VERSION ""

NS_ :

BS_:

BU_: HzpStatus PathPoint LtRtEdg HzpSlot FarPathPoint PathPointRear IPMFreeSpace LtRtSlot WheelObj HMI E115DCU
VAL_TABLE_ HZP_PathDltButton 2 "DeleteAllPath" 1 "DeleteOnePath" 0 "NotAct" ;
VAL_TABLE_ HZP_VSLAM_Sts 7 "Relocation" 6 "Locating Fail" 5 "Initial Locating Fail" 4 "Mapping OverSize" 3 "MappingFail" 2 "Localization" 1 "Mapping" 0 "UnEnable" ;
VAL_TABLE_ APA_Search_STS 7 "Finish" 6 "3rd Curb OK" 5 "Fail " 4 "Fall detect" 3 "Rise and Fall OK" 2 "Rise Conf" 1 "Rish detect" 0 "Reserved" ;
VAL_TABLE_ APA_STS 7 "RTA,Wait to release brake" 6 "APA_Fail" 5 "APA_Finish" 4 "APA HangOn" 3 "APA processing" 2 "Standby" 1 "OFF" 0 "Reserved" ;

BO_ 3221225472 VECTOR__INDEPENDENT_SIG_MSG: 0 Vector__XXX
 SG_ ESC_HBB_Status : 0|2@0+ (1,0) [0|3] "" Vector__XXX
 SG_ Checksum_GW_TCU1 : 0|8@0+ (1,0) [0|255] "" Vector__XXX
 SG_ Rollingcount_GW_TCU1 : 0|4@0+ (1,0) [0|15] "" Vector__XXX
 SG_ GpsNumSats2 : 0|8@0+ (1,0) [0|255] "" Vector__XXX
 SG_ GpsNumSats : 0|8@0+ (1,0) [0|255] "" Vector__XXX
 SG_ GpsAge : 0|16@0+ (0.01,0) [0|655.35] "" Vector__XXX

BO_ 1942 HZP_PathPointRear1: 8 PathPointRear
 SG_ PthPtRr1_Slope : 25|2@0+ (1,0) [0|0] ""  E115DCU
 SG_ PathPointStrAng : 54|11@0- (0.5,0) [-500|500] ""  E115DCU
 SG_ PthPtRollCnt : 59|4@0+ (1,0) [0|15] ""  E115DCU
 SG_ PathPointY : 23|14@0- (0.01,0) [0|0] ""  E115DCU
 SG_ PathPointX : 7|14@0- (0.01,0) [0|0] ""  E115DCU
 SG_ PathPointAng : 39|17@0- (0.003,0) [0|0] ""  E115DCU

BO_ 1943 HZP_PathPointRear2: 8 PathPointRear
 SG_ PthPtRr2_Slope : 25|2@0+ (1,0) [0|0] ""  E115DCU
 SG_ PathPointStrAng : 54|11@0- (0.5,0) [-500|500] ""  E115DCU
 SG_ PthPtRollCnt : 59|4@0+ (1,0) [0|15] ""  E115DCU
 SG_ PathPointY : 23|14@0- (0.01,0) [0|0] ""  E115DCU
 SG_ PathPointX : 7|14@0- (0.01,0) [0|0] ""  E115DCU
 SG_ PathPointAng : 39|17@0- (0.003,0) [0|0] ""  E115DCU

BO_ 1944 HZP_PathPointRear3: 8 PathPointRear
 SG_ PthPtRr3_Slope : 25|2@0+ (1,0) [0|0] ""  E115DCU
 SG_ PathPointStrAng : 54|11@0- (0.5,0) [-500|500] ""  E115DCU
 SG_ PthPtRollCnt : 59|4@0+ (1,0) [0|15] ""  E115DCU
 SG_ PathPointY : 23|14@0- (0.01,0) [0|0] ""  E115DCU
 SG_ PathPointX : 7|14@0- (0.01,0) [0|0] ""  E115DCU
 SG_ PathPointAng : 39|17@0- (0.003,0) [0|0] ""  E115DCU

BO_ 1945 HZP_PathPointRear4: 8 PathPointRear
 SG_ PthPtRr4_Slope : 25|2@0+ (1,0) [0|0] ""  E115DCU
 SG_ PathPointStrAng : 54|11@0- (0.5,0) [-500|500] ""  E115DCU
 SG_ PthPtRollCnt : 59|4@0+ (1,0) [0|15] ""  E115DCU
 SG_ PathPointY : 23|14@0- (0.01,0) [0|0] ""  E115DCU
 SG_ PathPointX : 7|14@0- (0.01,0) [0|0] ""  E115DCU
 SG_ PathPointAng : 39|17@0- (0.003,0) [0|0] ""  E115DCU

BO_ 1946 HZP_PathPointRear5: 8 PathPointRear
 SG_ PthPtRr5_Slope : 25|2@0+ (1,0) [0|0] ""  E115DCU
 SG_ PathPointStrAng : 54|11@0- (0.5,0) [-500|500] ""  E115DCU
 SG_ PthPtRollCnt : 59|4@0+ (1,0) [0|15] ""  E115DCU
 SG_ PathPointY : 23|14@0- (0.01,0) [0|0] ""  E115DCU
 SG_ PathPointX : 7|14@0- (0.01,0) [0|0] ""  E115DCU
 SG_ PathPointAng : 39|17@0- (0.003,0) [0|0] ""  E115DCU

BO_ 1947 HZP_PathPointRear6: 8 PathPointRear
 SG_ PthPtRr6_Slope : 25|2@0+ (1,0) [0|0] ""  E115DCU
 SG_ PathPointStrAng : 54|11@0- (0.5,0) [-500|500] ""  E115DCU
 SG_ PthPtRollCnt : 59|4@0+ (1,0) [0|15] ""  E115DCU
 SG_ PathPointY : 23|14@0- (0.01,0) [0|0] ""  E115DCU
 SG_ PathPointX : 7|14@0- (0.01,0) [0|0] ""  E115DCU
 SG_ PathPointAng : 39|17@0- (0.003,0) [0|0] ""  E115DCU

BO_ 1948 HZP_PathPointRear7: 8 PathPointRear
 SG_ PthPtRr7_Slope : 25|2@0+ (1,0) [0|0] ""  E115DCU
 SG_ PathPointStrAng : 54|11@0- (0.5,0) [-500|500] ""  E115DCU
 SG_ PthPtRollCnt : 59|4@0+ (1,0) [0|15] ""  E115DCU
 SG_ PathPointY : 23|14@0- (0.01,0) [0|0] ""  E115DCU
 SG_ PathPointX : 7|14@0- (0.01,0) [0|0] ""  E115DCU
 SG_ PathPointAng : 39|17@0- (0.003,0) [0|0] ""  E115DCU

BO_ 1949 HZP_PathPointRear8: 8 PathPointRear
 SG_ PthPtRr8_Slope : 25|2@0+ (1,0) [0|0] ""  E115DCU
 SG_ PathPointStrAng : 54|11@0- (0.5,0) [-500|500] ""  E115DCU
 SG_ PthPtRollCnt : 59|4@0+ (1,0) [0|15] ""  E115DCU
 SG_ PathPointY : 23|14@0- (0.01,0) [0|0] ""  E115DCU
 SG_ PathPointX : 7|14@0- (0.01,0) [0|0] ""  E115DCU
 SG_ PathPointAng : 39|17@0- (0.003,0) [0|0] ""  E115DCU

BO_ 1950 HZP_PathPointRear9: 8 PathPointRear
 SG_ PthPtRr9_Slope : 25|2@0+ (1,0) [0|0] ""  E115DCU
 SG_ PathPointStrAng : 54|11@0- (0.5,0) [-500|500] ""  E115DCU
 SG_ PthPtRollCnt : 59|4@0+ (1,0) [0|15] ""  E115DCU
 SG_ PathPointY : 23|14@0- (0.01,0) [0|0] ""  E115DCU
 SG_ PathPointX : 7|14@0- (0.01,0) [0|0] ""  E115DCU
 SG_ PathPointAng : 39|17@0- (0.003,0) [0|0] ""  E115DCU

BO_ 1951 HZP_PathPointRear10: 8 PathPointRear
 SG_ PthPtRr10_Slope : 25|2@0+ (1,0) [0|0] ""  E115DCU
 SG_ PathPointStrAng : 54|11@0- (0.5,0) [-500|500] ""  E115DCU
 SG_ PthPtRollCnt : 59|4@0+ (1,0) [0|15] ""  E115DCU
 SG_ PathPointY : 23|14@0- (0.01,0) [0|0] ""  E115DCU
 SG_ PathPointX : 7|14@0- (0.01,0) [0|0] ""  E115DCU
 SG_ PathPointAng : 39|17@0- (0.003,0) [0|0] ""  E115DCU

BO_ 1952 HZP_MapEdgSlot_Info: 8 LtRtSlot
 SG_ HZP_MapRtSlotNm : 21|6@0+ (1,0) [0|63] ""  E115DCU
 SG_ HZP_MapRtEdgNm : 14|7@0+ (1,0) [0|127] ""  E115DCU
 SG_ HZP_MapLtSlotNm : 29|6@0+ (1,0) [0|63] ""  E115DCU
 SG_ HZP_MapLtEdgNm : 6|7@0+ (1,0) [0|127] ""  E115DCU

BO_ 1745 HZP_MapLtSlotPt_1: 8 LtRtSlot
 SG_ LtSlotPt_RollCnt : 59|4@0+ (1,0) [0|15] ""  E115DCU
 SG_ LtSlot2_Pt01Y : 53|10@0- (0.1,0) [-51.2|51.1] "m"  E115DCU
 SG_ LtSlot2_Pt01X : 47|10@0- (0.1,0) [-51.2|51.1] "m"  E115DCU
 SG_ LtSlot1_Pt02Y : 25|10@0- (0.1,0) [-51.2|51.1] "m"  E115DCU
 SG_ LtSlot1_Pt02X : 19|10@0- (0.1,0) [-51.2|51.1] "m"  E115DCU
 SG_ LtSlot1_Pt01Y : 13|10@0- (0.1,0) [-51.2|51.1] "m"  E115DCU
 SG_ LtSlot1_Pt01X : 7|10@0- (0.1,0) [-51.2|51.1] "m"  E115DCU

BO_ 1746 HZP_MapLtSlotPt_2: 8 LtRtSlot
 SG_ LtSlotPt_RollCnt : 59|4@0+ (1,0) [0|15] ""  E115DCU
 SG_ LtSlot3_Pt02Y : 53|10@0- (0.1,0) [-51.2|51.1] "m"  E115DCU
 SG_ LtSlot3_Pt02X : 47|10@0- (0.1,0) [-51.2|51.1] "m"  E115DCU
 SG_ LtSlot3_Pt01Y : 25|10@0- (0.1,0) [-51.2|51.1] "m"  E115DCU
 SG_ LtSlot3_Pt01X : 19|10@0- (0.1,0) [-51.2|51.1] "m"  E115DCU
 SG_ LtSlot2_Pt02Y : 13|10@0- (0.1,0) [-51.2|51.1] "m"  E115DCU
 SG_ LtSlot2_Pt02X : 7|10@0- (0.1,0) [-51.2|51.1] "m"  E115DCU

BO_ 1747 HZP_MapLtSlotPt_3: 8 LtRtSlot
 SG_ LtSlotPt_RollCnt : 59|4@0+ (1,0) [0|15] ""  E115DCU
 SG_ LtSlot5_Pt01Y : 53|10@0- (0.1,0) [-51.2|51.1] "m"  E115DCU
 SG_ LtSlot5_Pt01X : 47|10@0- (0.1,0) [-51.2|51.1] "m"  E115DCU
 SG_ LtSlot4_Pt02Y : 25|10@0- (0.1,0) [-51.2|51.1] "m"  E115DCU
 SG_ LtSlot4_Pt02X : 19|10@0- (0.1,0) [-51.2|51.1] "m"  E115DCU
 SG_ LtSlot4_Pt01Y : 13|10@0- (0.1,0) [-51.2|51.1] "m"  E115DCU
 SG_ LtSlot4_Pt01X : 7|10@0- (0.1,0) [-51.2|51.1] "m"  E115DCU

BO_ 1748 HZP_MapLtSlotPt_4: 8 LtRtSlot
 SG_ LtSlotPt_RollCnt : 59|4@0+ (1,0) [0|15] ""  E115DCU
 SG_ LtSlot6_Pt02Y : 53|10@0- (0.1,0) [-51.2|51.1] "m"  E115DCU
 SG_ LtSlot6_Pt02X : 47|10@0- (0.1,0) [-51.2|51.1] "m"  E115DCU
 SG_ LtSlot6_Pt01Y : 25|10@0- (0.1,0) [-51.2|51.1] "m"  E115DCU
 SG_ LtSlot6_Pt01X : 19|10@0- (0.1,0) [-51.2|51.1] "m"  E115DCU
 SG_ LtSlot5_Pt02Y : 13|10@0- (0.1,0) [-51.2|51.1] "m"  E115DCU
 SG_ LtSlot5_Pt02X : 7|10@0- (0.1,0) [-51.2|51.1] "m"  E115DCU

BO_ 1749 HZP_MapLtSlotPt_5: 8 LtRtSlot
 SG_ LtSlotPt_RollCnt : 59|4@0+ (1,0) [0|15] ""  E115DCU
 SG_ LtSlot8_Pt01Y : 53|10@0- (0.1,0) [-51.2|51.1] "m"  E115DCU
 SG_ LtSlot8_Pt01X : 47|10@0- (0.1,0) [-51.2|51.1] "m"  E115DCU
 SG_ LtSlot7_Pt02Y : 25|10@0- (0.1,0) [-51.2|51.1] "m"  E115DCU
 SG_ LtSlot7_Pt02X : 19|10@0- (0.1,0) [-51.2|51.1] "m"  E115DCU
 SG_ LtSlot7_Pt01Y : 13|10@0- (0.1,0) [-51.2|51.1] "m"  E115DCU
 SG_ LtSlot7_Pt01X : 7|10@0- (0.1,0) [-51.2|51.1] "m"  E115DCU

BO_ 1750 HZP_MapLtSlotPt_6: 8 LtRtSlot
 SG_ LtSlotPt_RollCnt : 59|4@0+ (1,0) [0|15] ""  E115DCU
 SG_ LtSlot9_Pt02Y : 53|10@0- (0.1,0) [-51.2|51.1] "m"  E115DCU
 SG_ LtSlot9_Pt02X : 47|10@0- (0.1,0) [-51.2|51.1] "m"  E115DCU
 SG_ LtSlot9_Pt01Y : 25|10@0- (0.1,0) [-51.2|51.1] "m"  E115DCU
 SG_ LtSlot9_Pt01X : 19|10@0- (0.1,0) [-51.2|51.1] "m"  E115DCU
 SG_ LtSlot8_Pt02Y : 13|10@0- (0.1,0) [-51.2|51.1] "m"  E115DCU
 SG_ LtSlot8_Pt02X : 7|10@0- (0.1,0) [-51.2|51.1] "m"  E115DCU

BO_ 1751 HZP_MapLtSlotPt_7: 8 LtRtSlot
 SG_ LtSlotPt_RollCnt : 59|4@0+ (1,0) [0|15] ""  E115DCU
 SG_ LtSlot11_Pt01Y : 53|10@0- (0.1,0) [-51.2|51.1] "m"  E115DCU
 SG_ LtSlot11_Pt01X : 47|10@0- (0.1,0) [-51.2|51.1] "m"  E115DCU
 SG_ LtSlot10_Pt02Y : 25|10@0- (0.1,0) [-51.2|51.1] "m"  E115DCU
 SG_ LtSlot10_Pt02X : 19|10@0- (0.1,0) [-51.2|51.1] "m"  E115DCU
 SG_ LtSlot10_Pt01Y : 13|10@0- (0.1,0) [-51.2|51.1] "m"  E115DCU
 SG_ LtSlot10_Pt01X : 7|10@0- (0.1,0) [-51.2|51.1] "m"  E115DCU

BO_ 1752 HZP_MapLtSlotPt_8: 8 LtRtSlot
 SG_ LtSlotPt_RollCnt : 59|4@0+ (1,0) [0|15] ""  E115DCU
 SG_ LtSlot12_Pt02Y : 53|10@0- (0.1,0) [-51.2|51.1] "m"  E115DCU
 SG_ LtSlot12_Pt02X : 47|10@0- (0.1,0) [-51.2|51.1] "m"  E115DCU
 SG_ LtSlot12_Pt01Y : 25|10@0- (0.1,0) [-51.2|51.1] "m"  E115DCU
 SG_ LtSlot12_Pt01X : 19|10@0- (0.1,0) [-51.2|51.1] "m"  E115DCU
 SG_ LtSlot11_Pt02Y : 13|10@0- (0.1,0) [-51.2|51.1] "m"  E115DCU
 SG_ LtSlot11_Pt02X : 7|10@0- (0.1,0) [-51.2|51.1] "m"  E115DCU

BO_ 1753 HZP_MapLtSlotPt_9: 8 LtRtSlot
 SG_ LtSlotPt_RollCnt : 59|4@0+ (1,0) [0|15] ""  E115DCU
 SG_ LtSlot14_Pt01Y : 53|10@0- (0.1,0) [-51.2|51.1] "m"  E115DCU
 SG_ LtSlot14_Pt01X : 47|10@0- (0.1,0) [-51.2|51.1] "m"  E115DCU
 SG_ LtSlot13_Pt02Y : 25|10@0- (0.1,0) [-51.2|51.1] "m"  E115DCU
 SG_ LtSlot13_Pt02X : 19|10@0- (0.1,0) [-51.2|51.1] "m"  E115DCU
 SG_ LtSlot13_Pt01Y : 13|10@0- (0.1,0) [-51.2|51.1] "m"  E115DCU
 SG_ LtSlot13_Pt01X : 7|10@0- (0.1,0) [-51.2|51.1] "m"  E115DCU

BO_ 1754 HZP_MapLtSlotPt_10: 8 LtRtSlot
 SG_ LtSlotPt_RollCnt : 59|4@0+ (1,0) [0|15] ""  E115DCU
 SG_ LtSlot15_Pt02Y : 53|10@0- (0.1,0) [-51.2|51.1] "m"  E115DCU
 SG_ LtSlot15_Pt02X : 47|10@0- (0.1,0) [-51.2|51.1] "m"  E115DCU
 SG_ LtSlot15_Pt01Y : 25|10@0- (0.1,0) [-51.2|51.1] "m"  E115DCU
 SG_ LtSlot15_Pt01X : 19|10@0- (0.1,0) [-51.2|51.1] "m"  E115DCU
 SG_ LtSlot14_Pt02Y : 13|10@0- (0.1,0) [-51.2|51.1] "m"  E115DCU
 SG_ LtSlot14_Pt02X : 7|10@0- (0.1,0) [-51.2|51.1] "m"  E115DCU

BO_ 1761 HZP_MapRtSlotPt_1: 8 LtRtSlot
 SG_ RtSlotPt_RollCnt : 59|4@0+ (1,0) [0|15] ""  E115DCU
 SG_ RtSlot2_Pt01Y : 53|10@0- (0.1,0) [-51.2|51.1] "m"  E115DCU
 SG_ RtSlot2_Pt01X : 47|10@0- (0.1,0) [-51.2|51.1] "m"  E115DCU
 SG_ RtSlot1_Pt02Y : 25|10@0- (0.1,0) [-51.2|51.1] "m"  E115DCU
 SG_ RtSlot1_Pt02X : 19|10@0- (0.1,0) [-51.2|51.1] "m"  E115DCU
 SG_ RtSlot1_Pt01Y : 13|10@0- (0.1,0) [-51.2|51.1] "m"  E115DCU
 SG_ RtSlot1_Pt01X : 7|10@0- (0.1,0) [-51.2|51.1] "m"  E115DCU

BO_ 1762 HZP_MapRtSlotPt_2: 8 LtRtSlot
 SG_ RtSlotPt_RollCnt : 59|4@0+ (1,0) [0|15] ""  E115DCU
 SG_ RtSlot3_Pt02Y : 53|10@0- (0.1,0) [-51.2|51.1] "m"  E115DCU
 SG_ RtSlot3_Pt02X : 47|10@0- (0.1,0) [-51.2|51.1] "m"  E115DCU
 SG_ RtSlot3_Pt01Y : 25|10@0- (0.1,0) [-51.2|51.1] "m"  E115DCU
 SG_ RtSlot3_Pt01X : 19|10@0- (0.1,0) [-51.2|51.1] "m"  E115DCU
 SG_ RtSlot2_Pt02Y : 13|10@0- (0.1,0) [-51.2|51.1] "m"  E115DCU
 SG_ RtSlot2_Pt02X : 7|10@0- (0.1,0) [-51.2|51.1] "m"  E115DCU

BO_ 1763 HZP_MapRtSlotPt_3: 8 LtRtSlot
 SG_ RtSlotPt_RollCnt : 59|4@0+ (1,0) [0|15] ""  E115DCU
 SG_ RtSlot5_Pt01Y : 53|10@0- (0.1,0) [-51.2|51.1] "m"  E115DCU
 SG_ RtSlot5_Pt01X : 47|10@0- (0.1,0) [-51.2|51.1] "m"  E115DCU
 SG_ RtSlot4_Pt02Y : 25|10@0- (0.1,0) [-51.2|51.1] "m"  E115DCU
 SG_ RtSlot4_Pt02X : 19|10@0- (0.1,0) [-51.2|51.1] "m"  E115DCU
 SG_ RtSlot4_Pt01Y : 13|10@0- (0.1,0) [-51.2|51.1] "m"  E115DCU
 SG_ RtSlot4_Pt01X : 7|10@0- (0.1,0) [-51.2|51.1] "m"  E115DCU

BO_ 1764 HZP_MapRtSlotPt_4: 8 LtRtSlot
 SG_ RtSlotPt_RollCnt : 59|4@0+ (1,0) [0|15] ""  E115DCU
 SG_ RtSlot6_Pt02Y : 53|10@0- (0.1,0) [-51.2|51.1] "m"  E115DCU
 SG_ RtSlot6_Pt02X : 47|10@0- (0.1,0) [-51.2|51.1] "m"  E115DCU
 SG_ RtSlot6_Pt01Y : 25|10@0- (0.1,0) [-51.2|51.1] "m"  E115DCU
 SG_ RtSlot6_Pt01X : 19|10@0- (0.1,0) [-51.2|51.1] "m"  E115DCU
 SG_ RtSlot5_Pt02Y : 13|10@0- (0.1,0) [-51.2|51.1] "m"  E115DCU
 SG_ RtSlot5_Pt02X : 7|10@0- (0.1,0) [-51.2|51.1] "m"  E115DCU

BO_ 1765 HZP_MapRtSlotPt_5: 8 LtRtSlot
 SG_ RtSlotPt_RollCnt : 59|4@0+ (1,0) [0|15] ""  E115DCU
 SG_ RtSlot8_Pt01Y : 53|10@0- (0.1,0) [-51.2|51.1] "m"  E115DCU
 SG_ RtSlot8_Pt01X : 47|10@0- (0.1,0) [-51.2|51.1] "m"  E115DCU
 SG_ RtSlot7_Pt02Y : 25|10@0- (0.1,0) [-51.2|51.1] "m"  E115DCU
 SG_ RtSlot7_Pt02X : 19|10@0- (0.1,0) [-51.2|51.1] "m"  E115DCU
 SG_ RtSlot7_Pt01Y : 13|10@0- (0.1,0) [-51.2|51.1] "m"  E115DCU
 SG_ RtSlot7_Pt01X : 7|10@0- (0.1,0) [-51.2|51.1] "m"  E115DCU

BO_ 1766 HZP_MapRtSlotPt_6: 8 LtRtSlot
 SG_ RtSlotPt_RollCnt : 59|4@0+ (1,0) [0|15] ""  E115DCU
 SG_ RtSlot9_Pt02Y : 53|10@0- (0.1,0) [-51.2|51.1] "m"  E115DCU
 SG_ RtSlot9_Pt02X : 47|10@0- (0.1,0) [-51.2|51.1] "m"  E115DCU
 SG_ RtSlot9_Pt01Y : 25|10@0- (0.1,0) [-51.2|51.1] "m"  E115DCU
 SG_ RtSlot9_Pt01X : 19|10@0- (0.1,0) [-51.2|51.1] "m"  E115DCU
 SG_ RtSlot8_Pt02Y : 13|10@0- (0.1,0) [-51.2|51.1] "m"  E115DCU
 SG_ RtSlot8_Pt02X : 7|10@0- (0.1,0) [-51.2|51.1] "m"  E115DCU

BO_ 1767 HZP_MapRtSlotPt_7: 8 LtRtSlot
 SG_ RtSlotPt_RollCnt : 59|4@0+ (1,0) [0|15] ""  E115DCU
 SG_ RtSlot11_Pt01Y : 53|10@0- (0.1,0) [-51.2|51.1] "m"  E115DCU
 SG_ RtSlot11_Pt01X : 47|10@0- (0.1,0) [-51.2|51.1] "m"  E115DCU
 SG_ RtSlot10_Pt02Y : 25|10@0- (0.1,0) [-51.2|51.1] "m"  E115DCU
 SG_ RtSlot10_Pt02X : 19|10@0- (0.1,0) [-51.2|51.1] "m"  E115DCU
 SG_ RtSlot10_Pt01Y : 13|10@0- (0.1,0) [-51.2|51.1] "m"  E115DCU
 SG_ RtSlot10_Pt01X : 7|10@0- (0.1,0) [-51.2|51.1] "m"  E115DCU

BO_ 1768 HZP_MapRtSlotPt_8: 8 LtRtSlot
 SG_ RtSlotPt_RollCnt : 59|4@0+ (1,0) [0|15] ""  E115DCU
 SG_ RtSlot12_Pt02Y : 53|10@0- (0.1,0) [-51.2|51.1] "m"  E115DCU
 SG_ RtSlot12_Pt02X : 47|10@0- (0.1,0) [-51.2|51.1] "m"  E115DCU
 SG_ RtSlot12_Pt01Y : 25|10@0- (0.1,0) [-51.2|51.1] "m"  E115DCU
 SG_ RtSlot12_Pt01X : 19|10@0- (0.1,0) [-51.2|51.1] "m"  E115DCU
 SG_ RtSlot11_Pt02Y : 13|10@0- (0.1,0) [-51.2|51.1] "m"  E115DCU
 SG_ RtSlot11_Pt02X : 7|10@0- (0.1,0) [-51.2|51.1] "m"  E115DCU

BO_ 1769 HZP_MapRtSlotPt_9: 8 LtRtSlot
 SG_ RtSlotPt_RollCnt : 59|4@0+ (1,0) [0|15] ""  E115DCU
 SG_ RtSlot14_Pt01Y : 53|10@0- (0.1,0) [-51.2|51.1] "m"  E115DCU
 SG_ RtSlot14_Pt01X : 47|10@0- (0.1,0) [-51.2|51.1] "m"  E115DCU
 SG_ RtSlot13_Pt02Y : 25|10@0- (0.1,0) [-51.2|51.1] "m"  E115DCU
 SG_ RtSlot13_Pt02X : 19|10@0- (0.1,0) [-51.2|51.1] "m"  E115DCU
 SG_ RtSlot13_Pt01Y : 13|10@0- (0.1,0) [-51.2|51.1] "m"  E115DCU
 SG_ RtSlot13_Pt01X : 7|10@0- (0.1,0) [-51.2|51.1] "m"  E115DCU

BO_ 1770 HZP_MapRtSlotPt_10: 8 LtRtSlot
 SG_ RtSlotPt_RollCnt : 59|4@0+ (1,0) [0|15] ""  E115DCU
 SG_ RtSlot15_Pt02Y : 53|10@0- (0.1,0) [-51.2|51.1] "m"  E115DCU
 SG_ RtSlot15_Pt02X : 47|10@0- (0.1,0) [-51.2|51.1] "m"  E115DCU
 SG_ RtSlot15_Pt01Y : 25|10@0- (0.1,0) [-51.2|51.1] "m"  E115DCU
 SG_ RtSlot15_Pt01X : 19|10@0- (0.1,0) [-51.2|51.1] "m"  E115DCU
 SG_ RtSlot14_Pt02Y : 13|10@0- (0.1,0) [-51.2|51.1] "m"  E115DCU
 SG_ RtSlot14_Pt02X : 7|10@0- (0.1,0) [-51.2|51.1] "m"  E115DCU

BO_ 1979 HZP_MapRtEdgPt_CLS1: 8 LtRtEdg
 SG_ RtEdg_Pt30Cls : 61|2@0+ (1,0) [0|0] ""  E115DCU
 SG_ RtEdg_Pt29Cls : 63|2@0+ (1,0) [0|0] ""  E115DCU
 SG_ RtEdg_Pt28Cls : 49|2@0+ (1,0) [0|0] ""  E115DCU
 SG_ RtEdg_Pt27Cls : 51|2@0+ (1,0) [0|0] ""  E115DCU
 SG_ RtEdg_Pt26Cls : 53|2@0+ (1,0) [0|0] ""  E115DCU
 SG_ RtEdg_Pt25Cls : 55|2@0+ (1,0) [0|0] ""  E115DCU
 SG_ RtEdg_Pt24Cls : 41|2@0+ (1,0) [0|0] ""  E115DCU
 SG_ RtEdg_Pt23Cls : 43|2@0+ (1,0) [0|0] ""  E115DCU
 SG_ RtEdg_Pt22Cls : 45|2@0+ (1,0) [0|0] ""  E115DCU
 SG_ RtEdg_Pt21Cls : 47|2@0+ (1,0) [0|0] ""  E115DCU
 SG_ RtEdg_Pt20Cls : 33|2@0+ (1,0) [0|0] ""  E115DCU
 SG_ RtEdg_Pt19Cls : 35|2@0+ (1,0) [0|0] ""  E115DCU
 SG_ RtEdg_Pt18Cls : 37|2@0+ (1,0) [0|0] ""  E115DCU
 SG_ RtEdg_Pt17Cls : 39|2@0+ (1,0) [0|0] ""  E115DCU
 SG_ RtEdg_Pt16Cls : 25|2@0+ (1,0) [0|0] ""  E115DCU
 SG_ RtEdg_Pt15Cls : 27|2@0+ (1,0) [0|0] ""  E115DCU
 SG_ RtEdg_Pt14Cls : 29|2@0+ (1,0) [0|0] ""  E115DCU
 SG_ RtEdg_Pt13Cls : 31|2@0+ (1,0) [0|0] ""  E115DCU
 SG_ RtEdg_Pt12Cls : 17|2@0+ (1,0) [0|0] ""  E115DCU
 SG_ RtEdg_Pt11Cls : 19|2@0+ (1,0) [0|0] ""  E115DCU
 SG_ RtEdg_Pt10Cls : 21|2@0+ (1,0) [0|0] ""  E115DCU
 SG_ RtEdg_Pt09Cls : 23|2@0+ (1,0) [0|0] ""  E115DCU
 SG_ RtEdg_Pt08Cls : 9|2@0+ (1,0) [0|0] ""  E115DCU
 SG_ RtEdg_Pt07Cls : 11|2@0+ (1,0) [0|0] ""  E115DCU
 SG_ RtEdg_Pt06Cls : 13|2@0+ (1,0) [0|0] ""  E115DCU
 SG_ RtEdg_Pt05Cls : 15|2@0+ (1,0) [0|0] ""  E115DCU
 SG_ RtEdg_Pt04Cls : 1|2@0+ (1,0) [0|0] ""  E115DCU
 SG_ RtEdg_Pt03Cls : 3|2@0+ (1,0) [0|0] ""  E115DCU
 SG_ RtEdg_Pt02Cls : 5|2@0+ (1,0) [0|0] ""  E115DCU
 SG_ RtEdg_Pt01Cls : 7|2@0+ (1,0) [0|0] ""  E115DCU

BO_ 1963 HZP_MapLtEdgPt_CLS1: 8 LtRtEdg
 SG_ LtEdg_Pt30Cls : 61|2@0+ (1,0) [0|0] ""  E115DCU
 SG_ LtEdg_Pt29Cls : 63|2@0+ (1,0) [0|0] ""  E115DCU
 SG_ LtEdg_Pt28Cls : 49|2@0+ (1,0) [0|0] ""  E115DCU
 SG_ LtEdg_Pt27Cls : 51|2@0+ (1,0) [0|0] ""  E115DCU
 SG_ LtEdg_Pt26Cls : 53|2@0+ (1,0) [0|0] ""  E115DCU
 SG_ LtEdg_Pt25Cls : 55|2@0+ (1,0) [0|0] ""  E115DCU
 SG_ LtEdg_Pt24Cls : 41|2@0+ (1,0) [0|0] ""  E115DCU
 SG_ LtEdg_Pt23Cls : 43|2@0+ (1,0) [0|0] ""  E115DCU
 SG_ LtEdg_Pt22Cls : 45|2@0+ (1,0) [0|0] ""  E115DCU
 SG_ LtEdg_Pt21Cls : 47|2@0+ (1,0) [0|0] ""  E115DCU
 SG_ LtEdg_Pt20Cls : 33|2@0+ (1,0) [0|0] ""  E115DCU
 SG_ LtEdg_Pt19Cls : 35|2@0+ (1,0) [0|0] ""  E115DCU
 SG_ LtEdg_Pt18Cls : 37|2@0+ (1,0) [0|0] ""  E115DCU
 SG_ LtEdg_Pt17Cls : 39|2@0+ (1,0) [0|0] ""  E115DCU
 SG_ LtEdg_Pt16Cls : 25|2@0+ (1,0) [0|0] ""  E115DCU
 SG_ LtEdg_Pt15Cls : 27|2@0+ (1,0) [0|0] ""  E115DCU
 SG_ LtEdg_Pt14Cls : 29|2@0+ (1,0) [0|0] ""  E115DCU
 SG_ LtEdg_Pt13Cls : 31|2@0+ (1,0) [0|0] ""  E115DCU
 SG_ LtEdg_Pt12Cls : 17|2@0+ (1,0) [0|0] ""  E115DCU
 SG_ LtEdg_Pt11Cls : 19|2@0+ (1,0) [0|0] ""  E115DCU
 SG_ LtEdg_Pt10Cls : 21|2@0+ (1,0) [0|0] ""  E115DCU
 SG_ LtEdg_Pt09Cls : 23|2@0+ (1,0) [0|0] ""  E115DCU
 SG_ LtEdg_Pt08Cls : 9|2@0+ (1,0) [0|0] ""  E115DCU
 SG_ LtEdg_Pt07Cls : 11|2@0+ (1,0) [0|0] ""  E115DCU
 SG_ LtEdg_Pt06Cls : 13|2@0+ (1,0) [0|0] ""  E115DCU
 SG_ LtEdg_Pt05Cls : 15|2@0+ (1,0) [0|0] ""  E115DCU
 SG_ LtEdg_Pt04Cls : 1|2@0+ (1,0) [0|0] ""  E115DCU
 SG_ LtEdg_Pt03Cls : 3|2@0+ (1,0) [0|0] ""  E115DCU
 SG_ LtEdg_Pt02Cls : 5|2@0+ (1,0) [0|0] ""  E115DCU
 SG_ LtEdg_Pt01Cls : 7|2@0+ (1,0) [0|0] ""  E115DCU

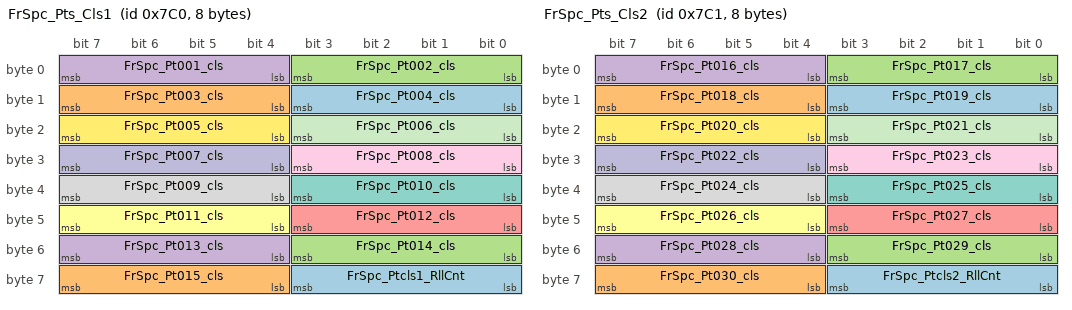
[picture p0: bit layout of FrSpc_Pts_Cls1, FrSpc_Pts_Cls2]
BO_ 1984 FrSpc_Pts_Cls1: 8 IPMFreeSpace
 SG_ FrSpc_Ptcls1_RllCnt : 59|4@0+ (1,0) [0|15] ""  E115DCU
 SG_ FrSpc_Pt015_cls : 63|4@0+ (1,0) [0|15] ""  E115DCU
 SG_ FrSpc_Pt014_cls : 51|4@0+ (1,0) [0|15] ""  E115DCU
 SG_ FrSpc_Pt013_cls : 55|4@0+ (1,0) [0|15] ""  E115DCU
 SG_ FrSpc_Pt012_cls : 43|4@0+ (1,0) [0|15] ""  E115DCU
 SG_ FrSpc_Pt011_cls : 47|4@0+ (1,0) [0|15] ""  E115DCU
 SG_ FrSpc_Pt010_cls : 35|4@0+ (1,0) [0|15] ""  E115DCU
 SG_ FrSpc_Pt009_cls : 39|4@0+ (1,0) [0|15] ""  E115DCU
 SG_ FrSpc_Pt008_cls : 27|4@0+ (1,0) [0|15] ""  E115DCU
 SG_ FrSpc_Pt007_cls : 31|4@0+ (1,0) [0|15] ""  E115DCU
 SG_ FrSpc_Pt006_cls : 19|4@0+ (1,0) [0|15] ""  E115DCU
 SG_ FrSpc_Pt005_cls : 23|4@0+ (1,0) [0|15] ""  E115DCU
 SG_ FrSpc_Pt004_cls : 11|4@0+ (1,0) [0|15] ""  E115DCU
 SG_ FrSpc_Pt003_cls : 15|4@0+ (1,0) [0|15] ""  E115DCU
 SG_ FrSpc_Pt002_cls : 3|4@0+ (1,0) [0|15] ""  E115DCU
 SG_ FrSpc_Pt001_cls : 7|4@0+ (1,0) [0|15] ""  E115DCU

BO_ 1985 FrSpc_Pts_Cls2: 8 IPMFreeSpace
 SG_ FrSpc_Ptcls2_RllCnt : 59|4@0+ (1,0) [0|15] ""  E115DCU
 SG_ FrSpc_Pt030_cls : 63|4@0+ (1,0) [0|15] ""  E115DCU
 SG_ FrSpc_Pt029_cls : 51|4@0+ (1,0) [0|15] ""  E115DCU
 SG_ FrSpc_Pt028_cls : 55|4@0+ (1,0) [0|15] ""  E115DCU
 SG_ FrSpc_Pt027_cls : 43|4@0+ (1,0) [0|15] ""  E115DCU
 SG_ FrSpc_Pt026_cls : 47|4@0+ (1,0) [0|15] ""  E115DCU
 SG_ FrSpc_Pt025_cls : 35|4@0+ (1,0) [0|15] ""  E115DCU
 SG_ FrSpc_Pt024_cls : 39|4@0+ (1,0) [0|15] ""  E115DCU
 SG_ FrSpc_Pt023_cls : 27|4@0+ (1,0) [0|15] ""  E115DCU
 SG_ FrSpc_Pt022_cls : 31|4@0+ (1,0) [0|15] ""  E115DCU
 SG_ FrSpc_Pt021_cls : 19|4@0+ (1,0) [0|15] ""  E115DCU
 SG_ FrSpc_Pt020_cls : 23|4@0+ (1,0) [0|15] ""  E115DCU
 SG_ FrSpc_Pt019_cls : 11|4@0+ (1,0) [0|15] ""  E115DCU
 SG_ FrSpc_Pt018_cls : 15|4@0+ (1,0) [0|15] ""  E115DCU
 SG_ FrSpc_Pt017_cls : 3|4@0+ (1,0) [0|15] ""  E115DCU
 SG_ FrSpc_Pt016_cls : 7|4@0+ (1,0) [0|15] ""  E115DCU

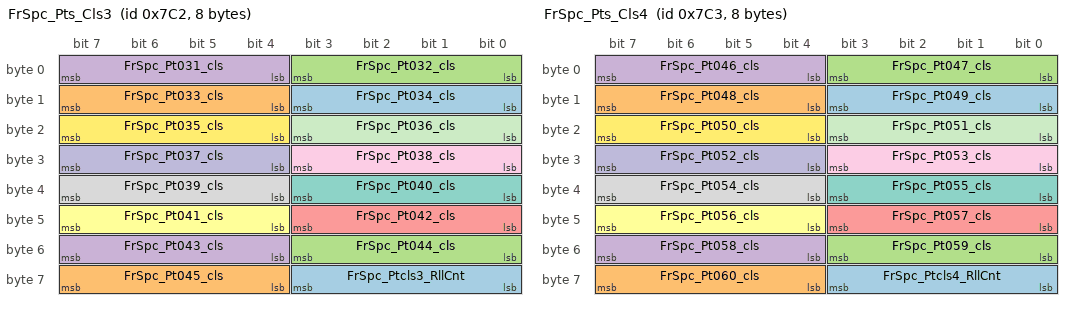
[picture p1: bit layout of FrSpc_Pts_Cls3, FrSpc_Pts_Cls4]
BO_ 1986 FrSpc_Pts_Cls3: 8 IPMFreeSpace
 SG_ FrSpc_Ptcls3_RllCnt : 59|4@0+ (1,0) [0|15] ""  E115DCU
 SG_ FrSpc_Pt045_cls : 63|4@0+ (1,0) [0|15] ""  E115DCU
 SG_ FrSpc_Pt044_cls : 51|4@0+ (1,0) [0|15] ""  E115DCU
 SG_ FrSpc_Pt043_cls : 55|4@0+ (1,0) [0|15] ""  E115DCU
 SG_ FrSpc_Pt042_cls : 43|4@0+ (1,0) [0|15] ""  E115DCU
 SG_ FrSpc_Pt041_cls : 47|4@0+ (1,0) [0|15] ""  E115DCU
 SG_ FrSpc_Pt040_cls : 35|4@0+ (1,0) [0|15] ""  E115DCU
 SG_ FrSpc_Pt039_cls : 39|4@0+ (1,0) [0|15] ""  E115DCU
 SG_ FrSpc_Pt038_cls : 27|4@0+ (1,0) [0|15] ""  E115DCU
 SG_ FrSpc_Pt037_cls : 31|4@0+ (1,0) [0|15] ""  E115DCU
 SG_ FrSpc_Pt036_cls : 19|4@0+ (1,0) [0|15] ""  E115DCU
 SG_ FrSpc_Pt035_cls : 23|4@0+ (1,0) [0|15] ""  E115DCU
 SG_ FrSpc_Pt034_cls : 11|4@0+ (1,0) [0|15] ""  E115DCU
 SG_ FrSpc_Pt033_cls : 15|4@0+ (1,0) [0|15] ""  E115DCU
 SG_ FrSpc_Pt032_cls : 3|4@0+ (1,0) [0|15] ""  E115DCU
 SG_ FrSpc_Pt031_cls : 7|4@0+ (1,0) [0|15] ""  E115DCU

BO_ 1987 FrSpc_Pts_Cls4: 8 IPMFreeSpace
 SG_ FrSpc_Ptcls4_RllCnt : 59|4@0+ (1,0) [0|15] ""  E115DCU
 SG_ FrSpc_Pt060_cls : 63|4@0+ (1,0) [0|15] ""  E115DCU
 SG_ FrSpc_Pt059_cls : 51|4@0+ (1,0) [0|15] ""  E115DCU
 SG_ FrSpc_Pt058_cls : 55|4@0+ (1,0) [0|15] ""  E115DCU
 SG_ FrSpc_Pt057_cls : 43|4@0+ (1,0) [0|15] ""  E115DCU
 SG_ FrSpc_Pt056_cls : 47|4@0+ (1,0) [0|15] ""  E115DCU
 SG_ FrSpc_Pt055_cls : 35|4@0+ (1,0) [0|15] ""  E115DCU
 SG_ FrSpc_Pt054_cls : 39|4@0+ (1,0) [0|15] ""  E115DCU
 SG_ FrSpc_Pt053_cls : 27|4@0+ (1,0) [0|15] ""  E115DCU
 SG_ FrSpc_Pt052_cls : 31|4@0+ (1,0) [0|15] ""  E115DCU
 SG_ FrSpc_Pt051_cls : 19|4@0+ (1,0) [0|15] ""  E115DCU
 SG_ FrSpc_Pt050_cls : 23|4@0+ (1,0) [0|15] ""  E115DCU
 SG_ FrSpc_Pt049_cls : 11|4@0+ (1,0) [0|15] ""  E115DCU
 SG_ FrSpc_Pt048_cls : 15|4@0+ (1,0) [0|15] ""  E115DCU
 SG_ FrSpc_Pt047_cls : 3|4@0+ (1,0) [0|15] ""  E115DCU
 SG_ FrSpc_Pt046_cls : 7|4@0+ (1,0) [0|15] ""  E115DCU

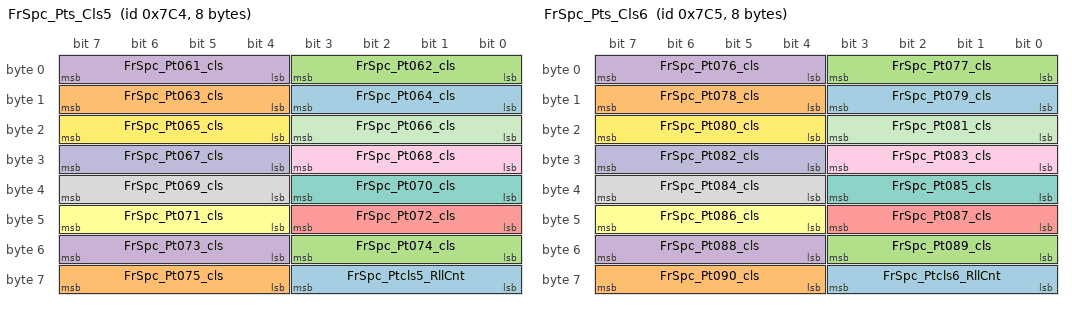
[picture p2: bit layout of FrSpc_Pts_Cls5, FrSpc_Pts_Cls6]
BO_ 1988 FrSpc_Pts_Cls5: 8 IPMFreeSpace
 SG_ FrSpc_Ptcls5_RllCnt : 59|4@0+ (1,0) [0|15] ""  E115DCU
 SG_ FrSpc_Pt075_cls : 63|4@0+ (1,0) [0|15] ""  E115DCU
 SG_ FrSpc_Pt074_cls : 51|4@0+ (1,0) [0|15] ""  E115DCU
 SG_ FrSpc_Pt073_cls : 55|4@0+ (1,0) [0|15] ""  E115DCU
 SG_ FrSpc_Pt072_cls : 43|4@0+ (1,0) [0|15] ""  E115DCU
 SG_ FrSpc_Pt071_cls : 47|4@0+ (1,0) [0|15] ""  E115DCU
 SG_ FrSpc_Pt070_cls : 35|4@0+ (1,0) [0|15] ""  E115DCU
 SG_ FrSpc_Pt069_cls : 39|4@0+ (1,0) [0|15] ""  E115DCU
 SG_ FrSpc_Pt068_cls : 27|4@0+ (1,0) [0|15] ""  E115DCU
 SG_ FrSpc_Pt067_cls : 31|4@0+ (1,0) [0|15] ""  E115DCU
 SG_ FrSpc_Pt066_cls : 19|4@0+ (1,0) [0|15] ""  E115DCU
 SG_ FrSpc_Pt065_cls : 23|4@0+ (1,0) [0|15] ""  E115DCU
 SG_ FrSpc_Pt064_cls : 11|4@0+ (1,0) [0|15] ""  E115DCU
 SG_ FrSpc_Pt063_cls : 15|4@0+ (1,0) [0|15] ""  E115DCU
 SG_ FrSpc_Pt062_cls : 3|4@0+ (1,0) [0|15] ""  E115DCU
 SG_ FrSpc_Pt061_cls : 7|4@0+ (1,0) [0|15] ""  E115DCU

BO_ 1989 FrSpc_Pts_Cls6: 8 IPMFreeSpace
 SG_ FrSpc_Ptcls6_RllCnt : 59|4@0+ (1,0) [0|15] ""  E115DCU
 SG_ FrSpc_Pt090_cls : 63|4@0+ (1,0) [0|15] ""  E115DCU
 SG_ FrSpc_Pt089_cls : 51|4@0+ (1,0) [0|15] ""  E115DCU
 SG_ FrSpc_Pt088_cls : 55|4@0+ (1,0) [0|15] ""  E115DCU
 SG_ FrSpc_Pt087_cls : 43|4@0+ (1,0) [0|15] ""  E115DCU
 SG_ FrSpc_Pt086_cls : 47|4@0+ (1,0) [0|15] ""  E115DCU
 SG_ FrSpc_Pt085_cls : 35|4@0+ (1,0) [0|15] ""  E115DCU
 SG_ FrSpc_Pt084_cls : 39|4@0+ (1,0) [0|15] ""  E115DCU
 SG_ FrSpc_Pt083_cls : 27|4@0+ (1,0) [0|15] ""  E115DCU
 SG_ FrSpc_Pt082_cls : 31|4@0+ (1,0) [0|15] ""  E115DCU
 SG_ FrSpc_Pt081_cls : 19|4@0+ (1,0) [0|15] ""  E115DCU
 SG_ FrSpc_Pt080_cls : 23|4@0+ (1,0) [0|15] ""  E115DCU
 SG_ FrSpc_Pt079_cls : 11|4@0+ (1,0) [0|15] ""  E115DCU
 SG_ FrSpc_Pt078_cls : 15|4@0+ (1,0) [0|15] ""  E115DCU
 SG_ FrSpc_Pt077_cls : 3|4@0+ (1,0) [0|15] ""  E115DCU
 SG_ FrSpc_Pt076_cls : 7|4@0+ (1,0) [0|15] ""  E115DCU

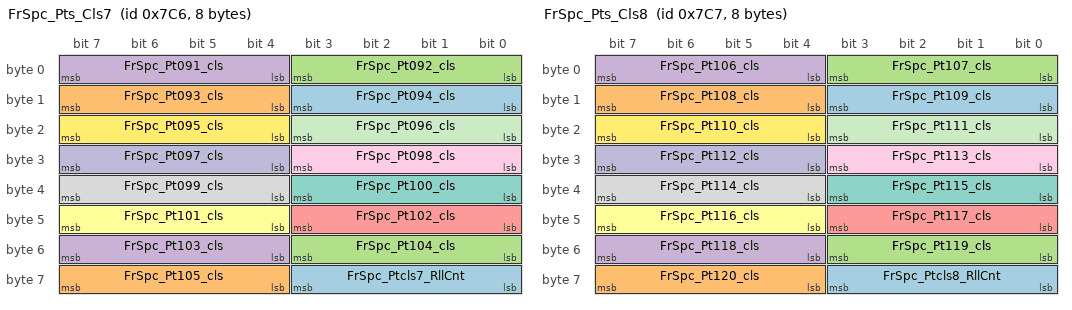
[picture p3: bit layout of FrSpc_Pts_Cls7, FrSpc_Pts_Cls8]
BO_ 1990 FrSpc_Pts_Cls7: 8 IPMFreeSpace
 SG_ FrSpc_Ptcls7_RllCnt : 59|4@0+ (1,0) [0|15] ""  E115DCU
 SG_ FrSpc_Pt105_cls : 63|4@0+ (1,0) [0|15] ""  E115DCU
 SG_ FrSpc_Pt104_cls : 51|4@0+ (1,0) [0|15] ""  E115DCU
 SG_ FrSpc_Pt103_cls : 55|4@0+ (1,0) [0|15] ""  E115DCU
 SG_ FrSpc_Pt102_cls : 43|4@0+ (1,0) [0|15] ""  E115DCU
 SG_ FrSpc_Pt101_cls : 47|4@0+ (1,0) [0|15] ""  E115DCU
 SG_ FrSpc_Pt100_cls : 35|4@0+ (1,0) [0|15] ""  E115DCU
 SG_ FrSpc_Pt099_cls : 39|4@0+ (1,0) [0|15] ""  E115DCU
 SG_ FrSpc_Pt098_cls : 27|4@0+ (1,0) [0|15] ""  E115DCU
 SG_ FrSpc_Pt097_cls : 31|4@0+ (1,0) [0|15] ""  E115DCU
 SG_ FrSpc_Pt096_cls : 19|4@0+ (1,0) [0|15] ""  E115DCU
 SG_ FrSpc_Pt095_cls : 23|4@0+ (1,0) [0|15] ""  E115DCU
 SG_ FrSpc_Pt094_cls : 11|4@0+ (1,0) [0|15] ""  E115DCU
 SG_ FrSpc_Pt093_cls : 15|4@0+ (1,0) [0|15] ""  E115DCU
 SG_ FrSpc_Pt092_cls : 3|4@0+ (1,0) [0|15] ""  E115DCU
 SG_ FrSpc_Pt091_cls : 7|4@0+ (1,0) [0|15] ""  E115DCU

BO_ 1991 FrSpc_Pts_Cls8: 8 IPMFreeSpace
 SG_ FrSpc_Ptcls8_RllCnt : 59|4@0+ (1,0) [0|15] ""  E115DCU
 SG_ FrSpc_Pt120_cls : 63|4@0+ (1,0) [0|15] ""  E115DCU
 SG_ FrSpc_Pt119_cls : 51|4@0+ (1,0) [0|15] ""  E115DCU
 SG_ FrSpc_Pt118_cls : 55|4@0+ (1,0) [0|15] ""  E115DCU
 SG_ FrSpc_Pt117_cls : 43|4@0+ (1,0) [0|15] ""  E115DCU
 SG_ FrSpc_Pt116_cls : 47|4@0+ (1,0) [0|15] ""  E115DCU
 SG_ FrSpc_Pt115_cls : 35|4@0+ (1,0) [0|15] ""  E115DCU
 SG_ FrSpc_Pt114_cls : 39|4@0+ (1,0) [0|15] ""  E115DCU
 SG_ FrSpc_Pt113_cls : 27|4@0+ (1,0) [0|15] ""  E115DCU
 SG_ FrSpc_Pt112_cls : 31|4@0+ (1,0) [0|15] ""  E115DCU
 SG_ FrSpc_Pt111_cls : 19|4@0+ (1,0) [0|15] ""  E115DCU
 SG_ FrSpc_Pt110_cls : 23|4@0+ (1,0) [0|15] ""  E115DCU
 SG_ FrSpc_Pt109_cls : 11|4@0+ (1,0) [0|15] ""  E115DCU
 SG_ FrSpc_Pt108_cls : 15|4@0+ (1,0) [0|15] ""  E115DCU
 SG_ FrSpc_Pt107_cls : 3|4@0+ (1,0) [0|15] ""  E115DCU
 SG_ FrSpc_Pt106_cls : 7|4@0+ (1,0) [0|15] ""  E115DCU

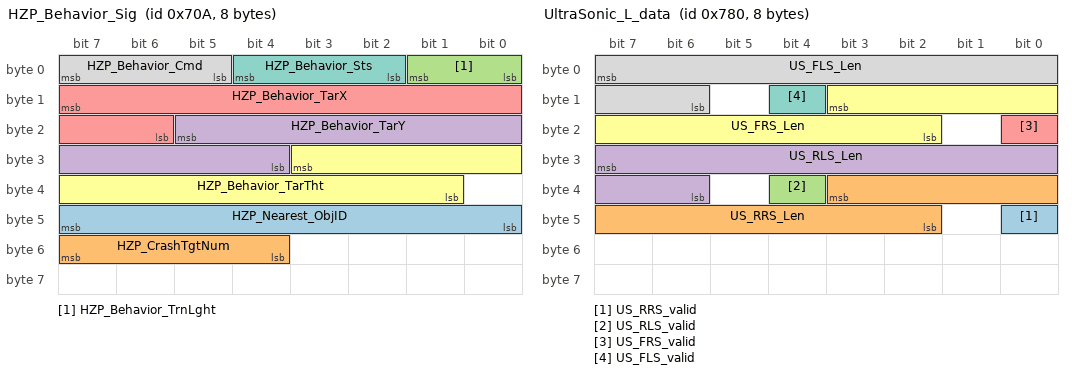
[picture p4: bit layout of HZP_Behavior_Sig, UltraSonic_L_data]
BO_ 1802 HZP_Behavior_Sig: 8 E115DCU
 SG_ HZP_Nearest_ObjID : 47|8@0+ (1,0) [0|0] "" Vector__XXX
 SG_ HZP_CrashTgtNum : 55|4@0+ (1,0) [0|0] "" Vector__XXX
 SG_ HZP_Behavior_TrnLght : 1|2@0+ (1,0) [0|0] "" Vector__XXX
 SG_ HZP_Behavior_TarY : 21|10@0- (0.02,0) [-10.24|10.22] "" Vector__XXX
 SG_ HZP_Behavior_TarX : 15|10@0- (0.05,0) [-25.6|25.55] "" Vector__XXX
 SG_ HZP_Behavior_TarTht : 27|11@0- (0.1758,0) [-180.0192|179.8434] "" Vector__XXX
 SG_ HZP_Behavior_Sts : 4|3@0+ (1,0) [0|0] "" Vector__XXX
 SG_ HZP_Behavior_Cmd : 7|3@0+ (1,0) [0|0] "" Vector__XXX

BO_ 1903 FrSpc_Info: 8 Vector__XXX
 SG_ FrSpc_CmrRightBlkFlg : 41|2@0+ (1,0) [0|0] "" Vector__XXX
 SG_ FrSpc_CmrRearBlkFlg : 45|2@0+ (1,0) [0|0] "" Vector__XXX
 SG_ FrSpc_CmrLeft_BlkFlg : 43|2@0+ (1,0) [0|0] "" Vector__XXX
 SG_ FrSpc_CmrFront_BlkFlg : 47|2@0+ (1,0) [0|0] "" Vector__XXX
 SG_ FreeSpc_IPM_Idx : 15|32@0+ (1,0) [0|0] "" Vector__XXX
 SG_ FrSpc_Num : 7|8@0+ (1,0) [0|0] "" Vector__XXX
 SG_ FrSpc0_Rllcnt : 59|4@0+ (1,0) [0|0] "" Vector__XXX

BO_ 1920 UltraSonic_L_data: 8 Vector__XXX
 SG_ US_RRS_valid : 40|1@0+ (1,0) [0|1] "" Vector__XXX
 SG_ US_RRS_Len : 35|10@0+ (1,0) [0|1023] "cm" Vector__XXX
 SG_ US_RLS_valid : 36|1@0+ (1,0) [0|1] "" Vector__XXX
 SG_ US_RLS_Len : 31|10@0+ (1,0) [0|1023] "cm" Vector__XXX
 SG_ US_FRS_valid : 16|1@0+ (1,0) [0|1] "" Vector__XXX
 SG_ US_FRS_Len : 11|10@0+ (1,0) [0|1023] "cm" Vector__XXX
 SG_ US_FLS_valid : 12|1@0+ (1,0) [0|1] "" Vector__XXX
 SG_ US_FLS_Len : 7|10@0+ (1,0) [0|1023] "cm" Vector__XXX

BO_ 1871 HZP_PathPoint_Far8: 8 FarPathPoint
 SG_ Far_PthPt15_Slope : 61|2@0+ (1,0) [0|0] ""  E115DCU
 SG_ Far_PthPt14_Slope : 63|2@0+ (1,0) [0|0] ""  E115DCU
 SG_ Far_PthPt13_Slope : 49|2@0+ (1,0) [0|0] ""  E115DCU
 SG_ Far_PthPt12_Slope : 51|2@0+ (1,0) [0|0] ""  E115DCU
 SG_ Far_PthPt11_Slope : 53|2@0+ (1,0) [0|0] ""  E115DCU
 SG_ Far_PthPt10_Slope : 55|2@0+ (1,0) [0|0] ""  E115DCU
 SG_ Far_PthPt9_Slope : 41|2@0+ (1,0) [0|0] ""  E115DCU
 SG_ Far_PthPt8_Slope : 43|2@0+ (1,0) [0|0] ""  E115DCU
 SG_ Far_PthPt7_Slope : 45|2@0+ (1,0) [0|0] ""  E115DCU
 SG_ Far_PthPt6_Slope : 47|2@0+ (1,0) [0|0] ""  E115DCU
 SG_ Far_PthPt5_Slope : 33|2@0+ (1,0) [0|0] ""  E115DCU
 SG_ Far_PthPt4_Slope : 35|2@0+ (1,0) [0|0] ""  E115DCU
 SG_ Far_PthPt3_Slope : 37|2@0+ (1,0) [0|0] ""  E115DCU
 SG_ Far_PthPt2_Slope : 39|2@0+ (1,0) [0|0] ""  E115DCU
 SG_ Far_PthPt1_Slope : 25|2@0+ (1,0) [0|0] ""  E115DCU
 SG_ Far_PathPoint15Ang : 19|10@0- (0.36,0) [-180|180] ""  E115DCU
 SG_ PthPtRollCnt : 59|4@0+ (1,0) [0|15] ""  E115DCU
 SG_ Far_PathPoint15Y : 13|10@0- (0.1,0) [-51.2|51.1] ""  E115DCU
 SG_ Far_PathPoint15X : 7|10@0- (0.1,0) [-51.2|51.1] ""  E115DCU

BO_ 1870 HZP_PathPoint_Far7: 8 FarPathPoint
 SG_ Far_PathPoint14Ang : 53|10@0- (0.36,0) [-180|180] ""  E115DCU
 SG_ Far_PathPoint13Ang : 19|10@0- (0.36,0) [-180|180] ""  E115DCU
 SG_ Far_PathPoint14Y : 47|10@0- (0.1,0) [-51.2|51.1] ""  E115DCU
 SG_ Far_PathPoint14X : 25|10@0- (0.1,0) [-51.2|51.1] ""  E115DCU
 SG_ PthPtRollCnt : 59|4@0+ (1,0) [0|15] ""  E115DCU
 SG_ Far_PathPoint13Y : 13|10@0- (0.1,0) [-51.2|51.1] ""  E115DCU
 SG_ Far_PathPoint13X : 7|10@0- (0.1,0) [-51.2|51.1] ""  E115DCU

BO_ 1869 HZP_PathPoint_Far6: 8 FarPathPoint
 SG_ Far_PathPoint12Ang : 53|10@0- (0.36,0) [-180|180] ""  E115DCU
 SG_ Far_PathPoint11Ang : 19|10@0- (0.36,0) [-180|180] ""  E115DCU
 SG_ Far_PathPoint12Y : 47|10@0- (0.1,0) [-51.2|51.1] ""  E115DCU
 SG_ Far_PathPoint12X : 25|10@0- (0.1,0) [-51.2|51.1] ""  E115DCU
 SG_ PthPtRollCnt : 59|4@0+ (1,0) [0|15] ""  E115DCU
 SG_ Far_PathPoint11Y : 13|10@0- (0.1,0) [-51.2|51.1] ""  E115DCU
 SG_ Far_PathPoint11X : 7|10@0- (0.1,0) [-51.2|51.1] ""  E115DCU

BO_ 1868 HZP_PathPoint_Far5: 8 FarPathPoint
 SG_ Far_PathPoint10Ang : 53|10@0- (0.36,0) [-180|180] ""  E115DCU
 SG_ Far_PathPoint9Ang : 19|10@0- (0.36,0) [-180|180] ""  E115DCU
 SG_ Far_PathPoint10Y : 47|10@0- (0.1,0) [-51.2|51.1] ""  E115DCU
 SG_ Far_PathPoint10X : 25|10@0- (0.1,0) [-51.2|51.1] ""  E115DCU
 SG_ PthPtRollCnt : 59|4@0+ (1,0) [0|15] ""  E115DCU
 SG_ Far_PathPoint9Y : 13|10@0- (0.1,0) [-51.2|51.1] ""  E115DCU
 SG_ Far_PathPoint9X : 7|10@0- (0.1,0) [-51.2|51.1] ""  E115DCU

BO_ 1867 HZP_PathPoint_Far4: 8 FarPathPoint
 SG_ Far_PathPoint8Ang : 53|10@0- (0.36,0) [-180|180] ""  E115DCU
 SG_ Far_PathPoint7Ang : 19|10@0- (0.36,0) [-180|180] ""  E115DCU
 SG_ Far_PathPoint8Y : 47|10@0- (0.1,0) [-51.2|51.1] ""  E115DCU
 SG_ Far_PathPoint8X : 25|10@0- (0.1,0) [-51.2|51.1] ""  E115DCU
 SG_ PthPtRollCnt : 59|4@0+ (1,0) [0|15] ""  E115DCU
 SG_ Far_PathPoint7Y : 13|10@0- (0.1,0) [-51.2|51.1] ""  E115DCU
 SG_ Far_PathPoint7X : 7|10@0- (0.1,0) [-51.2|51.1] ""  E115DCU

BO_ 1866 HZP_PathPoint_Far3: 8 FarPathPoint
 SG_ Far_PathPoint6Ang : 53|10@0- (0.36,0) [-180|180] ""  E115DCU
 SG_ Far_PathPoint5Ang : 19|10@0- (0.36,0) [-180|180] ""  E115DCU
 SG_ Far_PathPoint6Y : 47|10@0- (0.1,0) [-51.2|51.1] ""  E115DCU
 SG_ Far_PathPoint6X : 25|10@0- (0.1,0) [-51.2|51.1] ""  E115DCU
 SG_ PthPtRollCnt : 59|4@0+ (1,0) [0|15] ""  E115DCU
 SG_ Far_PathPoint5Y : 13|10@0- (0.1,0) [-51.2|51.1] ""  E115DCU
 SG_ Far_PathPoint5X : 7|10@0- (0.1,0) [-51.2|51.1] ""  E115DCU

BO_ 1865 HZP_PathPoint_Far2: 8 FarPathPoint
 SG_ Far_PathPoint4Ang : 53|10@0- (0.36,0) [-180|180] ""  E115DCU
 SG_ Far_PathPoint3Ang : 19|10@0- (0.36,0) [-180|180] ""  E115DCU
 SG_ Far_PathPoint4Y : 47|10@0- (0.1,0) [-51.2|51.1] ""  E115DCU
 SG_ Far_PathPoint4X : 25|10@0- (0.1,0) [-51.2|51.1] ""  E115DCU
 SG_ PthPtRollCnt : 59|4@0+ (1,0) [0|15] ""  E115DCU
 SG_ Far_PathPoint3Y : 13|10@0- (0.1,0) [-51.2|51.1] ""  E115DCU
 SG_ Far_PathPoint3X : 7|10@0- (0.1,0) [-51.2|51.1] ""  E115DCU

BO_ 1864 HZP_PathPoint_Far1: 8 FarPathPoint
 SG_ Far_PathPoint2Ang : 53|10@0- (0.36,0) [-180|180] ""  E115DCU
 SG_ Far_PathPoint1Ang : 19|10@0- (0.36,0) [-180|180] ""  E115DCU
 SG_ Far_PathPoint2Y : 47|10@0- (0.1,0) [-51.2|51.1] ""  E115DCU
 SG_ Far_PathPoint2X : 25|10@0- (0.1,0) [-51.2|51.1] ""  E115DCU
 SG_ PthPtRollCnt : 59|4@0+ (1,0) [0|15] ""  E115DCU
 SG_ Far_PathPoint1Y : 13|10@0- (0.1,0) [-51.2|51.1] ""  E115DCU
 SG_ Far_PathPoint1X : 7|10@0- (0.1,0) [-51.2|51.1] ""  E115DCU

BO_ 1978 HZP_MapRtEdgPt_10: 8 LtRtEdg
 SG_ RtRdgPt_RollCnt : 59|4@0+ (1,0) [0|15] ""  E115DCU
 SG_ RtEdg_Pt30Y : 53|10@0- (0.1,0) [-51.2|51.1] "m"  E115DCU
 SG_ RtEdg_Pt30X : 47|10@0- (0.1,0) [-51.2|51.1] "m"  E115DCU
 SG_ RtEdg_Pt29Y : 25|10@0- (0.1,0) [-51.2|51.1] "m"  E115DCU
 SG_ RtEdg_Pt29X : 19|10@0- (0.1,0) [-51.2|51.1] "m"  E115DCU
 SG_ RtEdg_Pt28Y : 13|10@0- (0.1,0) [-51.2|51.1] "m"  E115DCU
 SG_ RtEdg_Pt28X : 7|10@0- (0.1,0) [-51.2|51.1] "m"  E115DCU

BO_ 1977 HZP_MapRtEdgPt_9: 8 LtRtEdg
 SG_ RtRdgPt_RollCnt : 59|4@0+ (1,0) [0|15] ""  E115DCU
 SG_ RtEdg_Pt27Y : 53|10@0- (0.1,0) [-51.2|51.1] "m"  E115DCU
 SG_ RtEdg_Pt27X : 47|10@0- (0.1,0) [-51.2|51.1] "m"  E115DCU
 SG_ RtEdg_Pt26Y : 25|10@0- (0.1,0) [-51.2|51.1] "m"  E115DCU
 SG_ RtEdg_Pt26X : 19|10@0- (0.1,0) [-51.2|51.1] "m"  E115DCU
 SG_ RtEdg_Pt25Y : 13|10@0- (0.1,0) [-51.2|51.1] "m"  E115DCU
 SG_ RtEdg_Pt25X : 7|10@0- (0.1,0) [-51.2|51.1] "m"  E115DCU

BO_ 1976 HZP_MapRtEdgPt_8: 8 LtRtEdg
 SG_ RtRdgPt_RollCnt : 59|4@0+ (1,0) [0|15] ""  E115DCU
 SG_ RtEdg_Pt24Y : 53|10@0- (0.1,0) [-51.2|51.1] "m"  E115DCU
 SG_ RtEdg_Pt24X : 47|10@0- (0.1,0) [-51.2|51.1] "m"  E115DCU
 SG_ RtEdg_Pt23Y : 25|10@0- (0.1,0) [-51.2|51.1] "m"  E115DCU
 SG_ RtEdg_Pt23X : 19|10@0- (0.1,0) [-51.2|51.1] "m"  E115DCU
 SG_ RtEdg_Pt22Y : 13|10@0- (0.1,0) [-51.2|51.1] "m"  E115DCU
 SG_ RtEdg_Pt22X : 7|10@0- (0.1,0) [-51.2|51.1] "m"  E115DCU

BO_ 1975 HZP_MapRtEdgPt_7: 8 LtRtEdg
 SG_ RtRdgPt_RollCnt : 59|4@0+ (1,0) [0|15] ""  E115DCU
 SG_ RtEdg_Pt21Y : 53|10@0- (0.1,0) [-51.2|51.1] "m"  E115DCU
 SG_ RtEdg_Pt21X : 47|10@0- (0.1,0) [-51.2|51.1] "m"  E115DCU
 SG_ RtEdg_Pt20Y : 25|10@0- (0.1,0) [-51.2|51.1] "m"  E115DCU
 SG_ RtEdg_Pt20X : 19|10@0- (0.1,0) [-51.2|51.1] "m"  E115DCU
 SG_ RtEdg_Pt19Y : 13|10@0- (0.1,0) [-51.2|51.1] "m"  E115DCU
 SG_ RtEdg_Pt19X : 7|10@0- (0.1,0) [-51.2|51.1] "m"  E115DCU

BO_ 1974 HZP_MapRtEdgPt_6: 8 LtRtEdg
 SG_ RtRdgPt_RollCnt : 59|4@0+ (1,0) [0|15] ""  E115DCU
 SG_ RtEdg_Pt18Y : 53|10@0- (0.1,0) [-51.2|51.1] "m"  E115DCU
 SG_ RtEdg_Pt18X : 47|10@0- (0.1,0) [-51.2|51.1] "m"  E115DCU
 SG_ RtEdg_Pt17Y : 25|10@0- (0.1,0) [-51.2|51.1] "m"  E115DCU
 SG_ RtEdg_Pt17X : 19|10@0- (0.1,0) [-51.2|51.1] "m"  E115DCU
 SG_ RtEdg_Pt16Y : 13|10@0- (0.1,0) [-51.2|51.1] "m"  E115DCU
 SG_ RtEdg_Pt16X : 7|10@0- (0.1,0) [-51.2|51.1] "m"  E115DCU

BO_ 1973 HZP_MapRtEdgPt_5: 8 LtRtEdg
 SG_ RtRdgPt_RollCnt : 59|4@0+ (1,0) [0|15] ""  E115DCU
 SG_ RtEdg_Pt15Y : 53|10@0- (0.1,0) [-51.2|51.1] "m"  E115DCU
 SG_ RtEdg_Pt15X : 47|10@0- (0.1,0) [-51.2|51.1] "m"  E115DCU
 SG_ RtEdg_Pt14Y : 25|10@0- (0.1,0) [-51.2|51.1] "m"  E115DCU
 SG_ RtEdg_Pt14X : 19|10@0- (0.1,0) [-51.2|51.1] "m"  E115DCU
 SG_ RtEdg_Pt13Y : 13|10@0- (0.1,0) [-51.2|51.1] "m"  E115DCU
 SG_ RtEdg_Pt13X : 7|10@0- (0.1,0) [-51.2|51.1] "m"  E115DCU

BO_ 1972 HZP_MapRtEdgPt_4: 8 LtRtEdg
 SG_ RtRdgPt_RollCnt : 59|4@0+ (1,0) [0|15] ""  E115DCU
 SG_ RtEdg_Pt12Y : 53|10@0- (0.1,0) [-51.2|51.1] "m"  E115DCU
 SG_ RtEdg_Pt12X : 47|10@0- (0.1,0) [-51.2|51.1] "m"  E115DCU
 SG_ RtEdg_Pt11Y : 25|10@0- (0.1,0) [-51.2|51.1] "m"  E115DCU
 SG_ RtEdg_Pt11X : 19|10@0- (0.1,0) [-51.2|51.1] "m"  E115DCU
 SG_ RtEdg_Pt10Y : 13|10@0- (0.1,0) [-51.2|51.1] "m"  E115DCU
 SG_ RtEdg_Pt10X : 7|10@0- (0.1,0) [-51.2|51.1] "m"  E115DCU

BO_ 1971 HZP_MapRtEdgPt_3: 8 LtRtEdg
 SG_ RtRdgPt_RollCnt : 59|4@0+ (1,0) [0|15] ""  E115DCU
 SG_ RtEdg_Pt09Y : 53|10@0- (0.1,0) [-51.2|51.1] "m"  E115DCU
 SG_ RtEdg_Pt09X : 47|10@0- (0.1,0) [-51.2|51.1] "m"  E115DCU
 SG_ RtEdg_Pt08Y : 25|10@0- (0.1,0) [-51.2|51.1] "m"  E115DCU
 SG_ RtEdg_Pt08X : 19|10@0- (0.1,0) [-51.2|51.1] "m"  E115DCU
 SG_ RtEdg_Pt07Y : 13|10@0- (0.1,0) [-51.2|51.1] "m"  E115DCU
 SG_ RtEdg_Pt07X : 7|10@0- (0.1,0) [-51.2|51.1] "m"  E115DCU

BO_ 1970 HZP_MapRtEdgPt_2: 8 LtRtEdg
 SG_ RtRdgPt_RollCnt : 59|4@0+ (1,0) [0|15] ""  E115DCU
 SG_ RtEdg_Pt06Y : 53|10@0- (0.1,0) [-51.2|51.1] "m"  E115DCU
 SG_ RtEdg_Pt06X : 47|10@0- (0.1,0) [-51.2|51.1] "m"  E115DCU
 SG_ RtEdg_Pt05Y : 25|10@0- (0.1,0) [-51.2|51.1] "m"  E115DCU
 SG_ RtEdg_Pt05X : 19|10@0- (0.1,0) [-51.2|51.1] "m"  E115DCU
 SG_ RtEdg_Pt04Y : 13|10@0- (0.1,0) [-51.2|51.1] "m"  E115DCU
 SG_ RtEdg_Pt04X : 7|10@0- (0.1,0) [-51.2|51.1] "m"  E115DCU

BO_ 1969 HZP_MapRtEdgPt_1: 8 LtRtEdg
 SG_ RtRdgPt_RollCnt : 59|4@0+ (1,0) [0|15] ""  E115DCU
 SG_ RtEdg_Pt03Y : 53|10@0- (0.1,0) [-51.2|51.1] "m"  E115DCU
 SG_ RtEdg_Pt03X : 47|10@0- (0.1,0) [-51.2|51.1] "m"  E115DCU
 SG_ RtEdg_Pt02Y : 25|10@0- (0.1,0) [-51.2|51.1] "m"  E115DCU
 SG_ RtEdg_Pt02X : 19|10@0- (0.1,0) [-51.2|51.1] "m"  E115DCU
 SG_ RtEdg_Pt01Y : 13|10@0- (0.1,0) [-51.2|51.1] "m"  E115DCU
 SG_ RtEdg_Pt01X : 7|10@0- (0.1,0) [-51.2|51.1] "m"  E115DCU

BO_ 1962 HZP_MapLtEdgPt_10: 8 LtRtEdg
 SG_ LtRdgPt_RollCnt : 59|4@0+ (1,0) [0|15] ""  E115DCU
 SG_ LtEdg_Pt30Y : 53|10@0- (0.1,0) [-51.2|51.1] "m"  E115DCU
 SG_ LtEdg_Pt30X : 47|10@0- (0.1,0) [-51.2|51.1] "m"  E115DCU
 SG_ LtEdg_Pt29Y : 25|10@0- (0.1,0) [-51.2|51.1] "m"  E115DCU
 SG_ LtEdg_Pt29X : 19|10@0- (0.1,0) [-51.2|51.1] "m"  E115DCU
 SG_ LtEdg_Pt28Y : 13|10@0- (0.1,0) [-51.2|51.1] "m"  E115DCU
 SG_ LtEdg_Pt28X : 7|10@0- (0.1,0) [-51.2|51.1] "m"  E115DCU

BO_ 1961 HZP_MapLtEdgPt_9: 8 LtRtEdg
 SG_ LtRdgPt_RollCnt : 59|4@0+ (1,0) [0|15] ""  E115DCU
 SG_ LtEdg_Pt27Y : 53|10@0- (0.1,0) [-51.2|51.1] "m"  E115DCU
 SG_ LtEdg_Pt27X : 47|10@0- (0.1,0) [-51.2|51.1] "m"  E115DCU
 SG_ LtEdg_Pt26Y : 25|10@0- (0.1,0) [-51.2|51.1] "m"  E115DCU
 SG_ LtEdg_Pt26X : 19|10@0- (0.1,0) [-51.2|51.1] "m"  E115DCU
 SG_ LtEdg_Pt25Y : 13|10@0- (0.1,0) [-51.2|51.1] "m"  E115DCU
 SG_ LtEdg_Pt25X : 7|10@0- (0.1,0) [-51.2|51.1] "m"  E115DCU

BO_ 1960 HZP_MapLtEdgPt_8: 8 LtRtEdg
 SG_ LtRdgPt_RollCnt : 59|4@0+ (1,0) [0|15] ""  E115DCU
 SG_ LtEdg_Pt24Y : 53|10@0- (0.1,0) [-51.2|51.1] "m"  E115DCU
 SG_ LtEdg_Pt24X : 47|10@0- (0.1,0) [-51.2|51.1] "m"  E115DCU
 SG_ LtEdg_Pt23Y : 25|10@0- (0.1,0) [-51.2|51.1] "m"  E115DCU
 SG_ LtEdg_Pt23X : 19|10@0- (0.1,0) [-51.2|51.1] "m"  E115DCU
 SG_ LtEdg_Pt22Y : 13|10@0- (0.1,0) [-51.2|51.1] "m"  E115DCU
 SG_ LtEdg_Pt22X : 7|10@0- (0.1,0) [-51.2|51.1] "m"  E115DCU

BO_ 1959 HZP_MapLtEdgPt_7: 8 LtRtEdg
 SG_ LtRdgPt_RollCnt : 59|4@0+ (1,0) [0|15] ""  E115DCU
 SG_ LtEdg_Pt21Y : 53|10@0- (0.1,0) [-51.2|51.1] "m"  E115DCU
 SG_ LtEdg_Pt21X : 47|10@0- (0.1,0) [-51.2|51.1] "m"  E115DCU
 SG_ LtEdg_Pt20Y : 25|10@0- (0.1,0) [-51.2|51.1] "m"  E115DCU
 SG_ LtEdg_Pt20X : 19|10@0- (0.1,0) [-51.2|51.1] "m"  E115DCU
 SG_ LtEdg_Pt19Y : 13|10@0- (0.1,0) [-51.2|51.1] "m"  E115DCU
 SG_ LtEdg_Pt19X : 7|10@0- (0.1,0) [-51.2|51.1] "m"  E115DCU

BO_ 1958 HZP_MapLtEdgPt_6: 8 LtRtEdg
 SG_ LtRdgPt_RollCnt : 59|4@0+ (1,0) [0|15] ""  E115DCU
 SG_ LtEdg_Pt18Y : 53|10@0- (0.1,0) [-51.2|51.1] "m"  E115DCU
 SG_ LtEdg_Pt18X : 47|10@0- (0.1,0) [-51.2|51.1] "m"  E115DCU
 SG_ LtEdg_Pt17Y : 25|10@0- (0.1,0) [-51.2|51.1] "m"  E115DCU
 SG_ LtEdg_Pt17X : 19|10@0- (0.1,0) [-51.2|51.1] "m"  E115DCU
 SG_ LtEdg_Pt16Y : 13|10@0- (0.1,0) [-51.2|51.1] "m"  E115DCU
 SG_ LtEdg_Pt16X : 7|10@0- (0.1,0) [-51.2|51.1] "m"  E115DCU

BO_ 1957 HZP_MapLtEdgPt_5: 8 LtRtEdg
 SG_ LtRdgPt_RollCnt : 59|4@0+ (1,0) [0|15] ""  E115DCU
 SG_ LtEdg_Pt15Y : 53|10@0- (0.1,0) [-51.2|51.1] "m"  E115DCU
 SG_ LtEdg_Pt15X : 47|10@0- (0.1,0) [-51.2|51.1] "m"  E115DCU
 SG_ LtEdg_Pt14Y : 25|10@0- (0.1,0) [-51.2|51.1] "m"  E115DCU
 SG_ LtEdg_Pt14X : 19|10@0- (0.1,0) [-51.2|51.1] "m"  E115DCU
 SG_ LtEdg_Pt13Y : 13|10@0- (0.1,0) [-51.2|51.1] "m"  E115DCU
 SG_ LtEdg_Pt13X : 7|10@0- (0.1,0) [-51.2|51.1] "m"  E115DCU

BO_ 1956 HZP_MapLtEdgPt_4: 8 LtRtEdg
 SG_ LtRdgPt_RollCnt : 59|4@0+ (1,0) [0|15] ""  E115DCU
 SG_ LtEdg_Pt12Y : 53|10@0- (0.1,0) [-51.2|51.1] "m"  E115DCU
 SG_ LtEdg_Pt12X : 47|10@0- (0.1,0) [-51.2|51.1] "m"  E115DCU
 SG_ LtEdg_Pt11Y : 25|10@0- (0.1,0) [-51.2|51.1] "m"  E115DCU
 SG_ LtEdg_Pt11X : 19|10@0- (0.1,0) [-51.2|51.1] "m"  E115DCU
 SG_ LtEdg_Pt10Y : 13|10@0- (0.1,0) [-51.2|51.1] "m"  E115DCU
 SG_ LtEdg_Pt10X : 7|10@0- (0.1,0) [-51.2|51.1] "m"  E115DCU

BO_ 1955 HZP_MapLtEdgPt_3: 8 LtRtEdg
 SG_ LtRdgPt_RollCnt : 59|4@0+ (1,0) [0|15] ""  E115DCU
 SG_ LtEdg_Pt09Y : 53|10@0- (0.1,0) [-51.2|51.1] "m"  E115DCU
 SG_ LtEdg_Pt09X : 47|10@0- (0.1,0) [-51.2|51.1] "m"  E115DCU
 SG_ LtEdg_Pt08Y : 25|10@0- (0.1,0) [-51.2|51.1] "m"  E115DCU
 SG_ LtEdg_Pt08X : 19|10@0- (0.1,0) [-51.2|51.1] "m"  E115DCU
 SG_ LtEdg_Pt07Y : 13|10@0- (0.1,0) [-51.2|51.1] "m"  E115DCU
 SG_ LtEdg_Pt07X : 7|10@0- (0.1,0) [-51.2|51.1] "m"  E115DCU

BO_ 1954 HZP_MapLtEdgPt_2: 8 LtRtEdg
 SG_ LtRdgPt_RollCnt : 59|4@0+ (1,0) [0|15] ""  E115DCU
 SG_ LtEdg_Pt06Y : 53|10@0- (0.1,0) [-51.2|51.1] "m"  E115DCU
 SG_ LtEdg_Pt06X : 47|10@0- (0.1,0) [-51.2|51.1] "m"  E115DCU
 SG_ LtEdg_Pt05Y : 25|10@0- (0.1,0) [-51.2|51.1] "m"  E115DCU
 SG_ LtEdg_Pt05X : 19|10@0- (0.1,0) [-51.2|51.1] "m"  E115DCU
 SG_ LtEdg_Pt04Y : 13|10@0- (0.1,0) [-51.2|51.1] "m"  E115DCU
 SG_ LtEdg_Pt04X : 7|10@0- (0.1,0) [-51.2|51.1] "m"  E115DCU

BO_ 1953 HZP_MapLtEdgPt_1: 8 LtRtEdg
 SG_ LtRdgPt_RollCnt : 59|4@0+ (1,0) [0|15] ""  E115DCU
 SG_ LtEdg_Pt03Y : 53|10@0- (0.1,0) [-51.2|51.1] "m"  E115DCU
 SG_ LtEdg_Pt03X : 47|10@0- (0.1,0) [-51.2|51.1] "m"  E115DCU
 SG_ LtEdg_Pt02Y : 25|10@0- (0.1,0) [-51.2|51.1] "m"  E115DCU
 SG_ LtEdg_Pt02X : 19|10@0- (0.1,0) [-51.2|51.1] "m"  E115DCU
 SG_ LtEdg_Pt01Y : 13|10@0- (0.1,0) [-51.2|51.1] "m"  E115DCU
 SG_ LtEdg_Pt01X : 7|10@0- (0.1,0) [-51.2|51.1] "m"  E115DCU

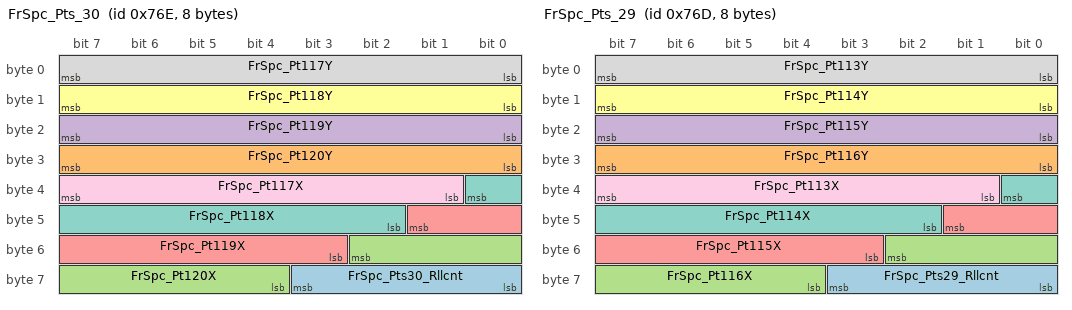
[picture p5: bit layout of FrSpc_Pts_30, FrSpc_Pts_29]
BO_ 1902 FrSpc_Pts_30: 8 IPMFreeSpace
 SG_ FrSpc_Pts30_Rllcnt : 59|4@0+ (1,0) [0|0] ""  E115DCU
 SG_ FrSpc_Pt120Y : 31|8@0- (0.0625,0) [-8|7.9375] "m"  E115DCU
 SG_ FrSpc_Pt120X : 50|7@0- (0.125,0) [-8|7.875] "m"  E115DCU
 SG_ FrSpc_Pt119Y : 23|8@0- (0.0625,0) [-8|7.9375] "m"  E115DCU
 SG_ FrSpc_Pt119X : 41|7@0- (0.125,0) [-8|7.875] "m"  E115DCU
 SG_ FrSpc_Pt118Y : 15|8@0- (0.0625,0) [-8|7.9375] "m"  E115DCU
 SG_ FrSpc_Pt118X : 32|7@0- (0.125,0) [-8|7.875] "m"  E115DCU
 SG_ FrSpc_Pt117Y : 7|8@0- (0.0625,0) [-8|7.9375] "m"  E115DCU
 SG_ FrSpc_Pt117X : 39|7@0- (0.125,0) [-8|7.875] "m"  E115DCU

BO_ 1901 FrSpc_Pts_29: 8 IPMFreeSpace
 SG_ FrSpc_Pts29_Rllcnt : 59|4@0+ (1,0) [0|0] ""  E115DCU
 SG_ FrSpc_Pt116Y : 31|8@0- (0.0625,0) [-8|7.9375] "m"  E115DCU
 SG_ FrSpc_Pt116X : 50|7@0- (0.125,0) [-8|7.875] "m"  E115DCU
 SG_ FrSpc_Pt115Y : 23|8@0- (0.0625,0) [-8|7.9375] "m"  E115DCU
 SG_ FrSpc_Pt115X : 41|7@0- (0.125,0) [-8|7.875] "m"  E115DCU
 SG_ FrSpc_Pt114Y : 15|8@0- (0.0625,0) [-8|7.9375] "m"  E115DCU
 SG_ FrSpc_Pt114X : 32|7@0- (0.125,0) [-8|7.875] "m"  E115DCU
 SG_ FrSpc_Pt113Y : 7|8@0- (0.0625,0) [-8|7.9375] "m"  E115DCU
 SG_ FrSpc_Pt113X : 39|7@0- (0.125,0) [-8|7.875] "m"  E115DCU

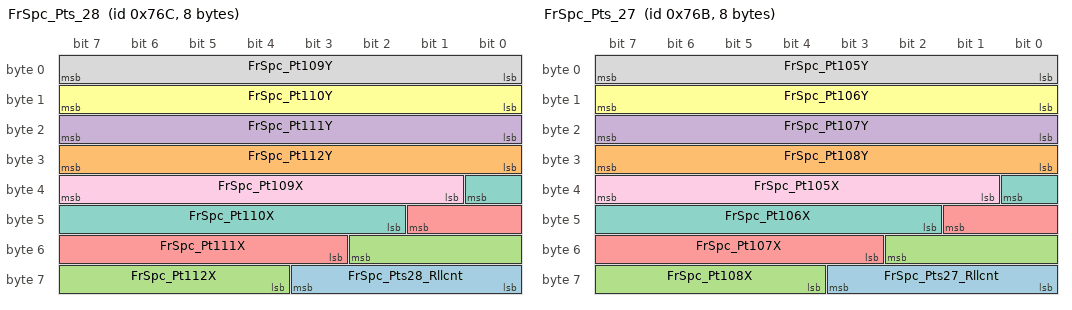
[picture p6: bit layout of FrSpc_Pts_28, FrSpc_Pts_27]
BO_ 1900 FrSpc_Pts_28: 8 IPMFreeSpace
 SG_ FrSpc_Pts28_Rllcnt : 59|4@0+ (1,0) [0|0] ""  E115DCU
 SG_ FrSpc_Pt112Y : 31|8@0- (0.0625,0) [-8|7.9375] "m"  E115DCU
 SG_ FrSpc_Pt112X : 50|7@0- (0.125,0) [-8|7.875] "m"  E115DCU
 SG_ FrSpc_Pt111Y : 23|8@0- (0.0625,0) [-8|7.9375] "m"  E115DCU
 SG_ FrSpc_Pt111X : 41|7@0- (0.125,0) [-8|7.875] "m"  E115DCU
 SG_ FrSpc_Pt110Y : 15|8@0- (0.0625,0) [-8|7.9375] "m"  E115DCU
 SG_ FrSpc_Pt110X : 32|7@0- (0.125,0) [-8|7.875] "m"  E115DCU
 SG_ FrSpc_Pt109Y : 7|8@0- (0.0625,0) [-8|7.9375] "m"  E115DCU
 SG_ FrSpc_Pt109X : 39|7@0- (0.125,0) [-8|7.875] "m"  E115DCU

BO_ 1899 FrSpc_Pts_27: 8 IPMFreeSpace
 SG_ FrSpc_Pts27_Rllcnt : 59|4@0+ (1,0) [0|0] ""  E115DCU
 SG_ FrSpc_Pt108Y : 31|8@0- (0.0625,0) [-8|7.9375] "m"  E115DCU
 SG_ FrSpc_Pt108X : 50|7@0- (0.125,0) [-8|7.875] "m"  E115DCU
 SG_ FrSpc_Pt107Y : 23|8@0- (0.0625,0) [-8|7.9375] "m"  E115DCU
 SG_ FrSpc_Pt107X : 41|7@0- (0.125,0) [-8|7.875] "m"  E115DCU
 SG_ FrSpc_Pt106Y : 15|8@0- (0.0625,0) [-8|7.9375] "m"  E115DCU
 SG_ FrSpc_Pt106X : 32|7@0- (0.125,0) [-8|7.875] "m"  E115DCU
 SG_ FrSpc_Pt105Y : 7|8@0- (0.0625,0) [-8|7.9375] "m"  E115DCU
 SG_ FrSpc_Pt105X : 39|7@0- (0.125,0) [-8|7.875] "m"  E115DCU

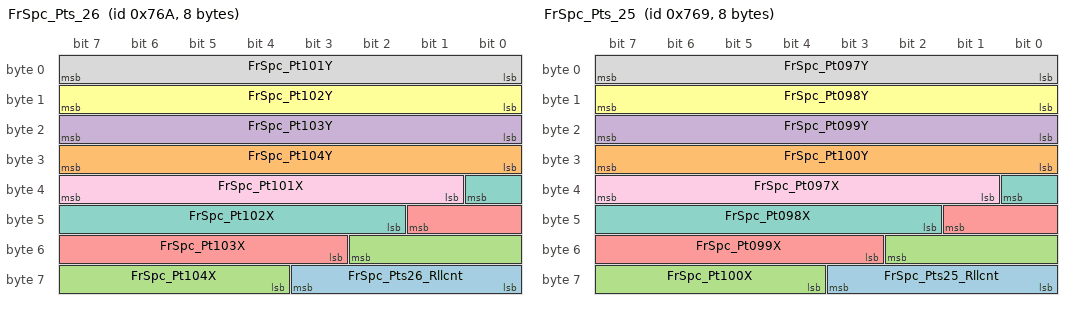
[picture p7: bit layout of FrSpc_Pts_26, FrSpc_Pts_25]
BO_ 1898 FrSpc_Pts_26: 8 IPMFreeSpace
 SG_ FrSpc_Pts26_Rllcnt : 59|4@0+ (1,0) [0|0] ""  E115DCU
 SG_ FrSpc_Pt104Y : 31|8@0- (0.0625,0) [-8|7.9375] "m"  E115DCU
 SG_ FrSpc_Pt104X : 50|7@0- (0.125,0) [-8|7.875] "m"  E115DCU
 SG_ FrSpc_Pt103Y : 23|8@0- (0.0625,0) [-8|7.9375] "m"  E115DCU
 SG_ FrSpc_Pt103X : 41|7@0- (0.125,0) [-8|7.875] "m"  E115DCU
 SG_ FrSpc_Pt102Y : 15|8@0- (0.0625,0) [-8|7.9375] "m"  E115DCU
 SG_ FrSpc_Pt102X : 32|7@0- (0.125,0) [-8|7.875] "m"  E115DCU
 SG_ FrSpc_Pt101Y : 7|8@0- (0.0625,0) [-8|7.9375] "m"  E115DCU
 SG_ FrSpc_Pt101X : 39|7@0- (0.125,0) [-8|7.875] "m"  E115DCU

BO_ 1897 FrSpc_Pts_25: 8 IPMFreeSpace
 SG_ FrSpc_Pts25_Rllcnt : 59|4@0+ (1,0) [0|0] ""  E115DCU
 SG_ FrSpc_Pt100Y : 31|8@0- (0.0625,0) [-8|7.9375] "m"  E115DCU
 SG_ FrSpc_Pt100X : 50|7@0- (0.125,0) [-8|7.875] "m"  E115DCU
 SG_ FrSpc_Pt099Y : 23|8@0- (0.0625,0) [-8|7.9375] "m"  E115DCU
 SG_ FrSpc_Pt099X : 41|7@0- (0.125,0) [-8|7.875] "m"  E115DCU
 SG_ FrSpc_Pt098Y : 15|8@0- (0.0625,0) [-8|7.9375] "m"  E115DCU
 SG_ FrSpc_Pt098X : 32|7@0- (0.125,0) [-8|7.875] "m"  E115DCU
 SG_ FrSpc_Pt097Y : 7|8@0- (0.0625,0) [-8|7.9375] "m"  E115DCU
 SG_ FrSpc_Pt097X : 39|7@0- (0.125,0) [-8|7.875] "m"  E115DCU

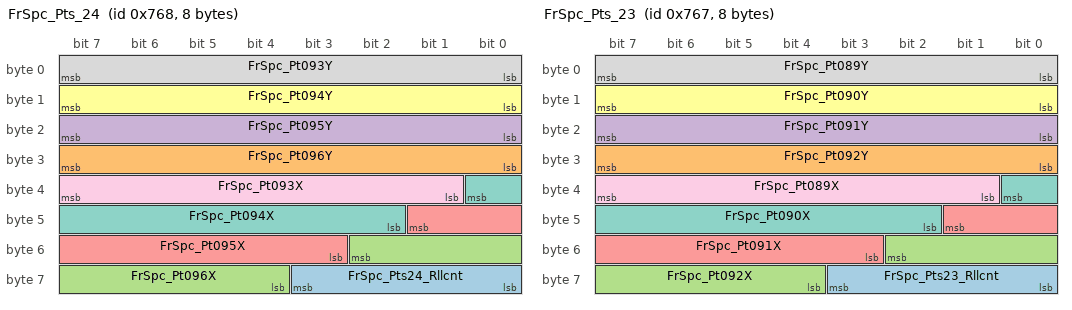
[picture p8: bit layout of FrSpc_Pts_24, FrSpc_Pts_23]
BO_ 1896 FrSpc_Pts_24: 8 IPMFreeSpace
 SG_ FrSpc_Pts24_Rllcnt : 59|4@0+ (1,0) [0|0] ""  E115DCU
 SG_ FrSpc_Pt096Y : 31|8@0- (0.0625,0) [-8|7.9375] "m"  E115DCU
 SG_ FrSpc_Pt096X : 50|7@0- (0.125,0) [-8|7.875] "m"  E115DCU
 SG_ FrSpc_Pt095Y : 23|8@0- (0.0625,0) [-8|7.9375] "m"  E115DCU
 SG_ FrSpc_Pt095X : 41|7@0- (0.125,0) [-8|7.875] "m"  E115DCU
 SG_ FrSpc_Pt094Y : 15|8@0- (0.0625,0) [-8|7.9375] "m"  E115DCU
 SG_ FrSpc_Pt094X : 32|7@0- (0.125,0) [-8|7.875] "m"  E115DCU
 SG_ FrSpc_Pt093Y : 7|8@0- (0.0625,0) [-8|7.9375] "m"  E115DCU
 SG_ FrSpc_Pt093X : 39|7@0- (0.125,0) [-8|7.875] "m"  E115DCU

BO_ 1895 FrSpc_Pts_23: 8 IPMFreeSpace
 SG_ FrSpc_Pts23_Rllcnt : 59|4@0+ (1,0) [0|0] ""  E115DCU
 SG_ FrSpc_Pt092Y : 31|8@0- (0.0625,0) [-8|7.9375] "m"  E115DCU
 SG_ FrSpc_Pt092X : 50|7@0- (0.125,0) [-8|7.875] "m"  E115DCU
 SG_ FrSpc_Pt091Y : 23|8@0- (0.0625,0) [-8|7.9375] "m"  E115DCU
 SG_ FrSpc_Pt091X : 41|7@0- (0.125,0) [-8|7.875] "m"  E115DCU
 SG_ FrSpc_Pt090Y : 15|8@0- (0.0625,0) [-8|7.9375] "m"  E115DCU
 SG_ FrSpc_Pt090X : 32|7@0- (0.125,0) [-8|7.875] "m"  E115DCU
 SG_ FrSpc_Pt089Y : 7|8@0- (0.0625,0) [-8|7.9375] "m"  E115DCU
 SG_ FrSpc_Pt089X : 39|7@0- (0.125,0) [-8|7.875] "m"  E115DCU

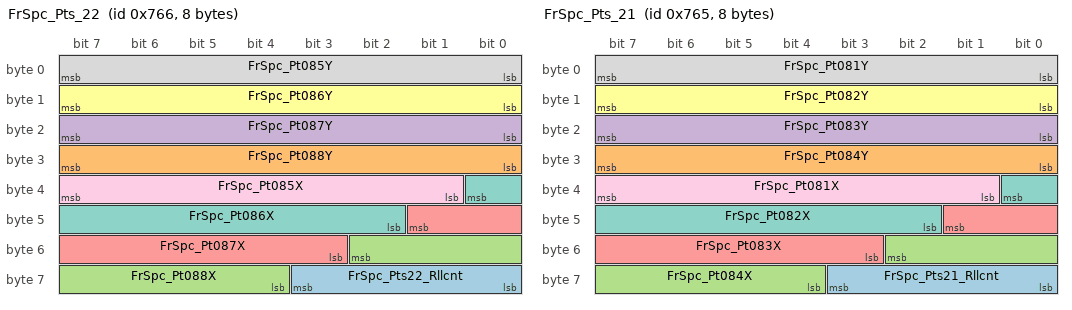
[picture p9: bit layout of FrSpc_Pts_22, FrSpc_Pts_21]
BO_ 1894 FrSpc_Pts_22: 8 IPMFreeSpace
 SG_ FrSpc_Pts22_Rllcnt : 59|4@0+ (1,0) [0|0] ""  E115DCU
 SG_ FrSpc_Pt088Y : 31|8@0- (0.0625,0) [-8|7.9375] "m"  E115DCU
 SG_ FrSpc_Pt088X : 50|7@0- (0.125,0) [-8|7.875] "m"  E115DCU
 SG_ FrSpc_Pt087Y : 23|8@0- (0.0625,0) [-8|7.9375] "m"  E115DCU
 SG_ FrSpc_Pt087X : 41|7@0- (0.125,0) [-8|7.875] "m"  E115DCU
 SG_ FrSpc_Pt086Y : 15|8@0- (0.0625,0) [-8|7.9375] "m"  E115DCU
 SG_ FrSpc_Pt086X : 32|7@0- (0.125,0) [-8|7.875] "m"  E115DCU
 SG_ FrSpc_Pt085Y : 7|8@0- (0.0625,0) [-8|7.9375] "m"  E115DCU
 SG_ FrSpc_Pt085X : 39|7@0- (0.125,0) [-8|7.875] "m"  E115DCU

BO_ 1893 FrSpc_Pts_21: 8 IPMFreeSpace
 SG_ FrSpc_Pts21_Rllcnt : 59|4@0+ (1,0) [0|0] ""  E115DCU
 SG_ FrSpc_Pt084Y : 31|8@0- (0.0625,0) [-8|7.9375] "m"  E115DCU
 SG_ FrSpc_Pt084X : 50|7@0- (0.125,0) [-8|7.875] "m"  E115DCU
 SG_ FrSpc_Pt083Y : 23|8@0- (0.0625,0) [-8|7.9375] "m"  E115DCU
 SG_ FrSpc_Pt083X : 41|7@0- (0.125,0) [-8|7.875] "m"  E115DCU
 SG_ FrSpc_Pt082Y : 15|8@0- (0.0625,0) [-8|7.9375] "m"  E115DCU
 SG_ FrSpc_Pt082X : 32|7@0- (0.125,0) [-8|7.875] "m"  E115DCU
 SG_ FrSpc_Pt081Y : 7|8@0- (0.0625,0) [-8|7.9375] "m"  E115DCU
 SG_ FrSpc_Pt081X : 39|7@0- (0.125,0) [-8|7.875] "m"  E115DCU

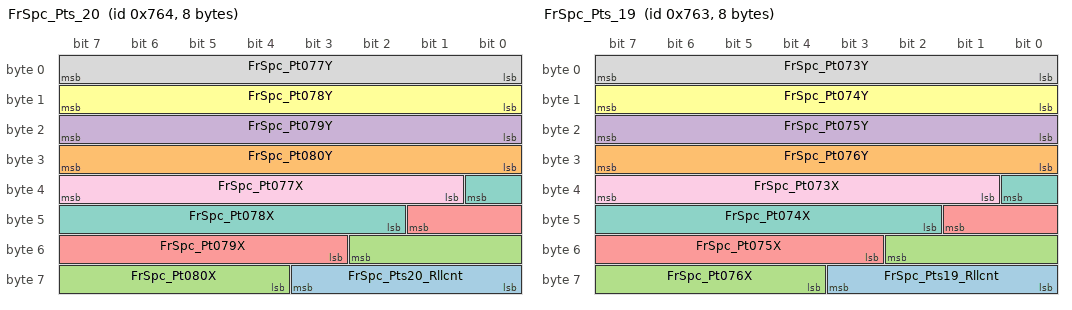
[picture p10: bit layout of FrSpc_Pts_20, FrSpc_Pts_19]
BO_ 1892 FrSpc_Pts_20: 8 IPMFreeSpace
 SG_ FrSpc_Pts20_Rllcnt : 59|4@0+ (1,0) [0|0] ""  E115DCU
 SG_ FrSpc_Pt080Y : 31|8@0- (0.0625,0) [-8|7.9375] "m"  E115DCU
 SG_ FrSpc_Pt080X : 50|7@0- (0.125,0) [-8|7.875] "m"  E115DCU
 SG_ FrSpc_Pt079Y : 23|8@0- (0.0625,0) [-8|7.9375] "m"  E115DCU
 SG_ FrSpc_Pt079X : 41|7@0- (0.125,0) [-8|7.875] "m"  E115DCU
 SG_ FrSpc_Pt078Y : 15|8@0- (0.0625,0) [-8|7.9375] "m"  E115DCU
 SG_ FrSpc_Pt078X : 32|7@0- (0.125,0) [-8|7.875] "m"  E115DCU
 SG_ FrSpc_Pt077Y : 7|8@0- (0.0625,0) [-8|7.9375] "m"  E115DCU
 SG_ FrSpc_Pt077X : 39|7@0- (0.125,0) [-8|7.875] "m"  E115DCU

BO_ 1891 FrSpc_Pts_19: 8 IPMFreeSpace
 SG_ FrSpc_Pts19_Rllcnt : 59|4@0+ (1,0) [0|0] ""  E115DCU
 SG_ FrSpc_Pt076Y : 31|8@0- (0.0625,0) [-8|7.9375] "m"  E115DCU
 SG_ FrSpc_Pt076X : 50|7@0- (0.125,0) [-8|7.875] "m"  E115DCU
 SG_ FrSpc_Pt075Y : 23|8@0- (0.0625,0) [-8|7.9375] "m"  E115DCU
 SG_ FrSpc_Pt075X : 41|7@0- (0.125,0) [-8|7.875] "m"  E115DCU
 SG_ FrSpc_Pt074Y : 15|8@0- (0.0625,0) [-8|7.9375] "m"  E115DCU
 SG_ FrSpc_Pt074X : 32|7@0- (0.125,0) [-8|7.875] "m"  E115DCU
 SG_ FrSpc_Pt073Y : 7|8@0- (0.0625,0) [-8|7.9375] "m"  E115DCU
 SG_ FrSpc_Pt073X : 39|7@0- (0.125,0) [-8|7.875] "m"  E115DCU

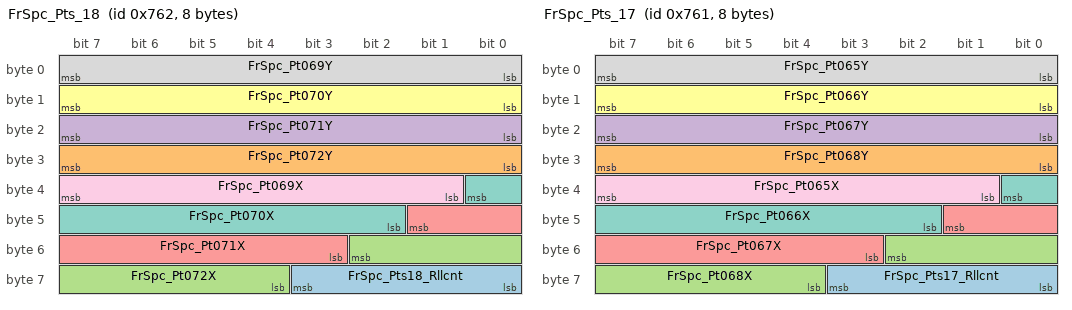
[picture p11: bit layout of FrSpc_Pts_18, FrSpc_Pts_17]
BO_ 1890 FrSpc_Pts_18: 8 IPMFreeSpace
 SG_ FrSpc_Pts18_Rllcnt : 59|4@0+ (1,0) [0|0] ""  E115DCU
 SG_ FrSpc_Pt072Y : 31|8@0- (0.0625,0) [-8|7.9375] "m"  E115DCU
 SG_ FrSpc_Pt072X : 50|7@0- (0.125,0) [-8|7.875] "m"  E115DCU
 SG_ FrSpc_Pt071Y : 23|8@0- (0.0625,0) [-8|7.9375] "m"  E115DCU
 SG_ FrSpc_Pt071X : 41|7@0- (0.125,0) [-8|7.875] "m"  E115DCU
 SG_ FrSpc_Pt070Y : 15|8@0- (0.0625,0) [-8|7.9375] "m"  E115DCU
 SG_ FrSpc_Pt070X : 32|7@0- (0.125,0) [-8|7.875] "m"  E115DCU
 SG_ FrSpc_Pt069Y : 7|8@0- (0.0625,0) [-8|7.9375] "m"  E115DCU
 SG_ FrSpc_Pt069X : 39|7@0- (0.125,0) [-8|7.875] "m"  E115DCU

BO_ 1889 FrSpc_Pts_17: 8 IPMFreeSpace
 SG_ FrSpc_Pts17_Rllcnt : 59|4@0+ (1,0) [0|0] ""  E115DCU
 SG_ FrSpc_Pt068Y : 31|8@0- (0.0625,0) [-8|7.9375] "m"  E115DCU
 SG_ FrSpc_Pt068X : 50|7@0- (0.125,0) [-8|7.875] "m"  E115DCU
 SG_ FrSpc_Pt067Y : 23|8@0- (0.0625,0) [-8|7.9375] "m"  E115DCU
 SG_ FrSpc_Pt067X : 41|7@0- (0.125,0) [-8|7.875] "m"  E115DCU
 SG_ FrSpc_Pt066Y : 15|8@0- (0.0625,0) [-8|7.9375] "m"  E115DCU
 SG_ FrSpc_Pt066X : 32|7@0- (0.125,0) [-8|7.875] "m"  E115DCU
 SG_ FrSpc_Pt065Y : 7|8@0- (0.0625,0) [-8|7.9375] "m"  E115DCU
 SG_ FrSpc_Pt065X : 39|7@0- (0.125,0) [-8|7.875] "m"  E115DCU

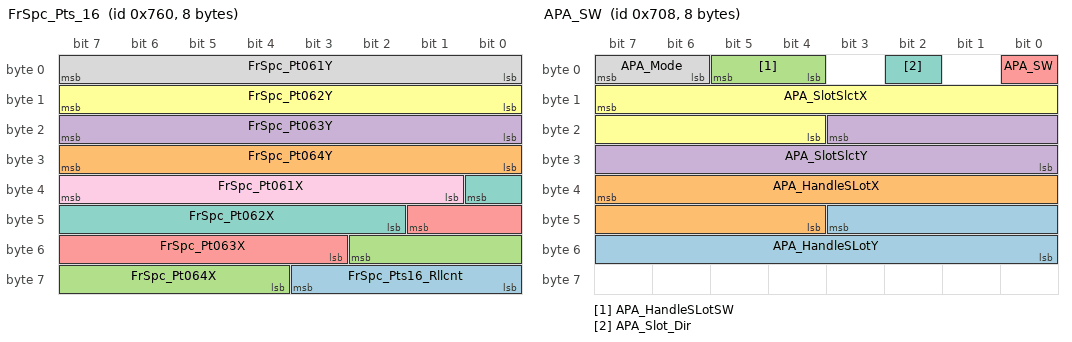
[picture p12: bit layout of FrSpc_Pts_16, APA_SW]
BO_ 1888 FrSpc_Pts_16: 8 IPMFreeSpace
 SG_ FrSpc_Pts16_Rllcnt : 59|4@0+ (1,0) [0|0] ""  E115DCU
 SG_ FrSpc_Pt064Y : 31|8@0- (0.0625,0) [-8|7.9375] "m"  E115DCU
 SG_ FrSpc_Pt064X : 50|7@0- (0.125,0) [-8|7.875] "m"  E115DCU
 SG_ FrSpc_Pt063Y : 23|8@0- (0.0625,0) [-8|7.9375] "m"  E115DCU
 SG_ FrSpc_Pt063X : 41|7@0- (0.125,0) [-8|7.875] "m"  E115DCU
 SG_ FrSpc_Pt062Y : 15|8@0- (0.0625,0) [-8|7.9375] "m"  E115DCU
 SG_ FrSpc_Pt062X : 32|7@0- (0.125,0) [-8|7.875] "m"  E115DCU
 SG_ FrSpc_Pt061Y : 7|8@0- (0.0625,0) [-8|7.9375] "m"  E115DCU
 SG_ FrSpc_Pt061X : 39|7@0- (0.125,0) [-8|7.875] "m"  E115DCU

BO_ 1887 FrSpc_Pts_15: 8 IPMFreeSpace
 SG_ FrSpc_Pts15_Rllcnt : 59|4@0+ (1,0) [0|0] ""  E115DCU
 SG_ FrSpc_Pt060Y : 31|8@0- (0.0625,0) [-8|7.9375] "m"  E115DCU
 SG_ FrSpc_Pt060X : 50|7@0- (0.125,0) [-8|7.875] "m"  E115DCU
 SG_ FrSpc_Pt059Y : 23|8@0- (0.0625,0) [-8|7.9375] "m"  E115DCU
 SG_ FrSpc_Pt059X : 41|7@0- (0.125,0) [-8|7.875] "m"  E115DCU
 SG_ FrSpc_Pt058Y : 15|8@0- (0.0625,0) [-8|7.9375] "m"  E115DCU
 SG_ FrSpc_Pt058X : 32|7@0- (0.125,0) [-8|7.875] "m"  E115DCU
 SG_ FrSpc_Pt057Y : 7|8@0- (0.0625,0) [-8|7.9375] "m"  E115DCU
 SG_ FrSpc_Pt057X : 39|7@0- (0.125,0) [-8|7.875] "m"  E115DCU

BO_ 1886 FrSpc_Pts_14: 8 IPMFreeSpace
 SG_ FrSpc_Pts14_Rllcnt : 59|4@0+ (1,0) [0|0] ""  E115DCU
 SG_ FrSpc_Pt056Y : 31|8@0- (0.0625,0) [-8|7.9375] "m"  E115DCU
 SG_ FrSpc_Pt056X : 50|7@0- (0.125,0) [-8|7.875] "m"  E115DCU
 SG_ FrSpc_Pt055Y : 23|8@0- (0.0625,0) [-8|7.9375] "m"  E115DCU
 SG_ FrSpc_Pt055X : 41|7@0- (0.125,0) [-8|7.875] "m"  E115DCU
 SG_ FrSpc_Pt054Y : 15|8@0- (0.0625,0) [-8|7.9375] "m"  E115DCU
 SG_ FrSpc_Pt054X : 32|7@0- (0.125,0) [-8|7.875] "m"  E115DCU
 SG_ FrSpc_Pt053Y : 7|8@0- (0.0625,0) [-8|7.9375] "m"  E115DCU
 SG_ FrSpc_Pt053X : 39|7@0- (0.125,0) [-8|7.875] "m"  E115DCU

BO_ 1885 FrSpc_Pts_13: 8 IPMFreeSpace
 SG_ FrSpc_Pts13_Rllcnt : 59|4@0+ (1,0) [0|0] ""  E115DCU
 SG_ FrSpc_Pt052Y : 31|8@0- (0.0625,0) [-8|7.9375] "m"  E115DCU
 SG_ FrSpc_Pt052X : 50|7@0- (0.125,0) [-8|7.875] "m"  E115DCU
 SG_ FrSpc_Pt051Y : 23|8@0- (0.0625,0) [-8|7.9375] "m"  E115DCU
 SG_ FrSpc_Pt051X : 41|7@0- (0.125,0) [-8|7.875] "m"  E115DCU
 SG_ FrSpc_Pt050Y : 15|8@0- (0.0625,0) [-8|7.9375] "m"  E115DCU
 SG_ FrSpc_Pt050X : 32|7@0- (0.125,0) [-8|7.875] "m"  E115DCU
 SG_ FrSpc_Pt049Y : 7|8@0- (0.0625,0) [-8|7.9375] "m"  E115DCU
 SG_ FrSpc_Pt049X : 39|7@0- (0.125,0) [-8|7.875] "m"  E115DCU

BO_ 1884 FrSpc_Pts_12: 8 IPMFreeSpace
 SG_ FrSpc_Pts12_Rllcnt : 59|4@0+ (1,0) [0|0] ""  E115DCU
 SG_ FrSpc_Pt048Y : 31|8@0- (0.0625,0) [-8|7.9375] "m"  E115DCU
 SG_ FrSpc_Pt048X : 50|7@0- (0.125,0) [-8|7.875] "m"  E115DCU
 SG_ FrSpc_Pt047Y : 23|8@0- (0.0625,0) [-8|7.9375] "m"  E115DCU
 SG_ FrSpc_Pt047X : 41|7@0- (0.125,0) [-8|7.875] "m"  E115DCU
 SG_ FrSpc_Pt046Y : 15|8@0- (0.0625,0) [-8|7.9375] "m"  E115DCU
 SG_ FrSpc_Pt046X : 32|7@0- (0.125,0) [-8|7.875] "m"  E115DCU
 SG_ FrSpc_Pt045Y : 7|8@0- (0.0625,0) [-8|7.9375] "m"  E115DCU
 SG_ FrSpc_Pt045X : 39|7@0- (0.125,0) [-8|7.875] "m"  E115DCU

BO_ 1883 FrSpc_Pts_11: 8 IPMFreeSpace
 SG_ FrSpc_Pts11_Rllcnt : 59|4@0+ (1,0) [0|0] ""  E115DCU
 SG_ FrSpc_Pt044Y : 31|8@0- (0.0625,0) [-8|7.9375] "m"  E115DCU
 SG_ FrSpc_Pt044X : 50|7@0- (0.125,0) [-8|7.875] "m"  E115DCU
 SG_ FrSpc_Pt043Y : 23|8@0- (0.0625,0) [-8|7.9375] "m"  E115DCU
 SG_ FrSpc_Pt043X : 41|7@0- (0.125,0) [-8|7.875] "m"  E115DCU
 SG_ FrSpc_Pt042Y : 15|8@0- (0.0625,0) [-8|7.9375] "m"  E115DCU
 SG_ FrSpc_Pt042X : 32|7@0- (0.125,0) [-8|7.875] "m"  E115DCU
 SG_ FrSpc_Pt041Y : 7|8@0- (0.0625,0) [-8|7.9375] "m"  E115DCU
 SG_ FrSpc_Pt041X : 39|7@0- (0.125,0) [-8|7.875] "m"  E115DCU

BO_ 1882 FrSpc_Pts_10: 8 IPMFreeSpace
 SG_ FrSpc_Pts10_Rllcnt : 59|4@0+ (1,0) [0|0] ""  E115DCU
 SG_ FrSpc_Pt040Y : 31|8@0- (0.0625,0) [-8|7.9375] "m"  E115DCU
 SG_ FrSpc_Pt040X : 50|7@0- (0.125,0) [-8|7.875] "m"  E115DCU
 SG_ FrSpc_Pt039Y : 23|8@0- (0.0625,0) [-8|7.9375] "m"  E115DCU
 SG_ FrSpc_Pt039X : 41|7@0- (0.125,0) [-8|7.875] "m"  E115DCU
 SG_ FrSpc_Pt038Y : 15|8@0- (0.0625,0) [-8|7.9375] "m"  E115DCU
 SG_ FrSpc_Pt038X : 32|7@0- (0.125,0) [-8|7.875] "m"  E115DCU
 SG_ FrSpc_Pt037Y : 7|8@0- (0.0625,0) [-8|7.9375] "m"  E115DCU
 SG_ FrSpc_Pt037X : 39|7@0- (0.125,0) [-8|7.875] "m"  E115DCU

BO_ 1881 FrSpc_Pts_9: 8 IPMFreeSpace
 SG_ FrSpc_Pts9_Rllcnt : 59|4@0+ (1,0) [0|0] ""  E115DCU
 SG_ FrSpc_Pt036Y : 31|8@0- (0.0625,0) [-8|7.9375] "m"  E115DCU
 SG_ FrSpc_Pt036X : 50|7@0- (0.125,0) [-8|7.875] "m"  E115DCU
 SG_ FrSpc_Pt035Y : 23|8@0- (0.0625,0) [-8|7.9375] "m"  E115DCU
 SG_ FrSpc_Pt035X : 41|7@0- (0.125,0) [-8|7.875] "m"  E115DCU
 SG_ FrSpc_Pt034Y : 15|8@0- (0.0625,0) [-8|7.9375] "m"  E115DCU
 SG_ FrSpc_Pt034X : 32|7@0- (0.125,0) [-8|7.875] "m"  E115DCU
 SG_ FrSpc_Pt033Y : 7|8@0- (0.0625,0) [-8|7.9375] "m"  E115DCU
 SG_ FrSpc_Pt033X : 39|7@0- (0.125,0) [-8|7.875] "m"  E115DCU

BO_ 1880 FrSpc_Pts_8: 8 IPMFreeSpace
 SG_ FrSpc_Pts8_Rllcnt : 59|4@0+ (1,0) [0|0] ""  E115DCU
 SG_ FrSpc_Pt032Y : 31|8@0- (0.0625,0) [-8|7.9375] "m"  E115DCU
 SG_ FrSpc_Pt032X : 50|7@0- (0.125,0) [-8|7.875] "m"  E115DCU
 SG_ FrSpc_Pt031Y : 23|8@0- (0.0625,0) [-8|7.9375] "m"  E115DCU
 SG_ FrSpc_Pt031X : 41|7@0- (0.125,0) [-8|7.875] "m"  E115DCU
 SG_ FrSpc_Pt030Y : 15|8@0- (0.0625,0) [-8|7.9375] "m"  E115DCU
 SG_ FrSpc_Pt030X : 32|7@0- (0.125,0) [-8|7.875] "m"  E115DCU
 SG_ FrSpc_Pt029Y : 7|8@0- (0.0625,0) [-8|7.9375] "m"  E115DCU
 SG_ FrSpc_Pt029X : 39|7@0- (0.125,0) [-8|7.875] "m"  E115DCU

BO_ 1879 FrSpc_Pts_7: 8 IPMFreeSpace
 SG_ FrSpc_Pts7_Rllcnt : 59|4@0+ (1,0) [0|0] ""  E115DCU
 SG_ FrSpc_Pt028Y : 31|8@0- (0.0625,0) [-8|7.9375] "m"  E115DCU
 SG_ FrSpc_Pt028X : 50|7@0- (0.125,0) [-8|7.875] "m"  E115DCU
 SG_ FrSpc_Pt027Y : 23|8@0- (0.0625,0) [-8|7.9375] "m"  E115DCU
 SG_ FrSpc_Pt027X : 41|7@0- (0.125,0) [-8|7.875] "m"  E115DCU
 SG_ FrSpc_Pt026Y : 15|8@0- (0.0625,0) [-8|7.9375] "m"  E115DCU
 SG_ FrSpc_Pt026X : 32|7@0- (0.125,0) [-8|7.875] "m"  E115DCU
 SG_ FrSpc_Pt025Y : 7|8@0- (0.0625,0) [-8|7.9375] "m"  E115DCU
 SG_ FrSpc_Pt025X : 39|7@0- (0.125,0) [-8|7.875] "m"  E115DCU

BO_ 1878 FrSpc_Pts_6: 8 IPMFreeSpace
 SG_ FrSpc_Pts6_Rllcnt : 59|4@0+ (1,0) [0|0] ""  E115DCU
 SG_ FrSpc_Pt024Y : 31|8@0- (0.0625,0) [-8|7.9375] "m"  E115DCU
 SG_ FrSpc_Pt024X : 50|7@0- (0.125,0) [-8|7.875] "m"  E115DCU
 SG_ FrSpc_Pt023Y : 23|8@0- (0.0625,0) [-8|7.9375] "m"  E115DCU
 SG_ FrSpc_Pt023X : 41|7@0- (0.125,0) [-8|7.875] "m"  E115DCU
 SG_ FrSpc_Pt022Y : 15|8@0- (0.0625,0) [-8|7.9375] "m"  E115DCU
 SG_ FrSpc_Pt022X : 32|7@0- (0.125,0) [-8|7.875] "m"  E115DCU
 SG_ FrSpc_Pt021Y : 7|8@0- (0.0625,0) [-8|7.9375] "m"  E115DCU
 SG_ FrSpc_Pt021X : 39|7@0- (0.125,0) [-8|7.875] "m"  E115DCU

BO_ 1877 FrSpc_Pts_5: 8 IPMFreeSpace
 SG_ FrSpc_Pts5_Rllcnt : 59|4@0+ (1,0) [0|0] ""  E115DCU
 SG_ FrSpc_Pt020Y : 31|8@0- (0.0625,0) [-8|7.9375] "m"  E115DCU
 SG_ FrSpc_Pt020X : 50|7@0- (0.125,0) [-8|7.875] "m"  E115DCU
 SG_ FrSpc_Pt019Y : 23|8@0- (0.0625,0) [-8|7.9375] "m"  E115DCU
 SG_ FrSpc_Pt019X : 41|7@0- (0.125,0) [-8|7.875] "m"  E115DCU
 SG_ FrSpc_Pt018Y : 15|8@0- (0.0625,0) [-8|7.9375] "m"  E115DCU
 SG_ FrSpc_Pt018X : 32|7@0- (0.125,0) [-8|7.875] "m"  E115DCU
 SG_ FrSpc_Pt017Y : 7|8@0- (0.0625,0) [-8|7.9375] "m"  E115DCU
 SG_ FrSpc_Pt017X : 39|7@0- (0.125,0) [-8|7.875] "m"  E115DCU

BO_ 1876 FrSpc_Pts_4: 8 IPMFreeSpace
 SG_ FrSpc_Pts4_Rllcnt : 59|4@0+ (1,0) [0|0] ""  E115DCU
 SG_ FrSpc_Pt016Y : 31|8@0- (0.0625,0) [-8|7.9375] "m"  E115DCU
 SG_ FrSpc_Pt016X : 50|7@0- (0.125,0) [-8|7.875] "m"  E115DCU
 SG_ FrSpc_Pt015Y : 23|8@0- (0.0625,0) [-8|7.9375] "m"  E115DCU
 SG_ FrSpc_Pt015X : 41|7@0- (0.125,0) [-8|7.875] "m"  E115DCU
 SG_ FrSpc_Pt014Y : 15|8@0- (0.0625,0) [-8|7.9375] "m"  E115DCU
 SG_ FrSpc_Pt014X : 32|7@0- (0.125,0) [-8|7.875] "m"  E115DCU
 SG_ FrSpc_Pt013Y : 7|8@0- (0.0625,0) [-8|7.9375] "m"  E115DCU
 SG_ FrSpc_Pt013X : 39|7@0- (0.125,0) [-8|7.875] "m"  E115DCU

BO_ 1875 FrSpc_Pts_3: 8 IPMFreeSpace
 SG_ FrSpc_Pts3_Rllcnt : 59|4@0+ (1,0) [0|0] ""  E115DCU
 SG_ FrSpc_Pt012Y : 31|8@0- (0.0625,0) [-8|7.9375] "m"  E115DCU
 SG_ FrSpc_Pt012X : 50|7@0- (0.125,0) [-8|7.875] "m"  E115DCU
 SG_ FrSpc_Pt011Y : 23|8@0- (0.0625,0) [-8|7.9375] "m"  E115DCU
 SG_ FrSpc_Pt011X : 41|7@0- (0.125,0) [-8|7.875] "m"  E115DCU
 SG_ FrSpc_Pt010Y : 15|8@0- (0.0625,0) [-8|7.9375] "m"  E115DCU
 SG_ FrSpc_Pt010X : 32|7@0- (0.125,0) [-8|7.875] "m"  E115DCU
 SG_ FrSpc_Pt009Y : 7|8@0- (0.0625,0) [-8|7.9375] "m"  E115DCU
 SG_ FrSpc_Pt009X : 39|7@0- (0.125,0) [-8|7.875] "m"  E115DCU

BO_ 1874 FrSpc_Pts_2: 8 IPMFreeSpace
 SG_ FrSpc_Pts2_Rllcnt : 59|4@0+ (1,0) [0|0] ""  E115DCU
 SG_ FrSpc_Pt008Y : 31|8@0- (0.0625,0) [-8|7.9375] "m"  E115DCU
 SG_ FrSpc_Pt008X : 50|7@0- (0.125,0) [-8|7.875] "m"  E115DCU
 SG_ FrSpc_Pt007Y : 23|8@0- (0.0625,0) [-8|7.9375] "m"  E115DCU
 SG_ FrSpc_Pt007X : 41|7@0- (0.125,0) [-8|7.875] "m"  E115DCU
 SG_ FrSpc_Pt006Y : 15|8@0- (0.0625,0) [-8|7.9375] "m"  E115DCU
 SG_ FrSpc_Pt006X : 32|7@0- (0.125,0) [-8|7.875] "m"  E115DCU
 SG_ FrSpc_Pt005Y : 7|8@0- (0.0625,0) [-8|7.9375] "m"  E115DCU
 SG_ FrSpc_Pt005X : 39|7@0- (0.125,0) [-8|7.875] "m"  E115DCU

BO_ 1873 FrSpc_Pts_1: 8 IPMFreeSpace
 SG_ FrSpc_Pts1_Rllcnt : 59|4@0+ (1,0) [0|0] ""  E115DCU
 SG_ FrSpc_Pt004Y : 31|8@0- (0.0625,0) [-8|7.9375] "m"  E115DCU
 SG_ FrSpc_Pt004X : 50|7@0- (0.125,0) [-8|7.875] "m"  E115DCU
 SG_ FrSpc_Pt003Y : 23|8@0- (0.0625,0) [-8|7.9375] "m"  E115DCU
 SG_ FrSpc_Pt003X : 41|7@0- (0.125,0) [-8|7.875] "m"  E115DCU
 SG_ FrSpc_Pt002Y : 15|8@0- (0.0625,0) [-8|7.9375] "m"  E115DCU
 SG_ FrSpc_Pt002X : 32|7@0- (0.125,0) [-8|7.875] "m"  E115DCU
 SG_ FrSpc_Pt001Y : 7|8@0- (0.0625,0) [-8|7.9375] "m"  E115DCU
 SG_ FrSpc_Pt001X : 39|7@0- (0.125,0) [-8|7.875] "m"  E115DCU

BO_ 1369 HZP_Destination: 8 HzpStatus
 SG_ HZP_DestPnt_Rllcnt : 59|4@0+ (1,0) [0|0] ""  E115DCU
 SG_ HZP_Destination_Y : 19|20@0- (0.01,0) [0|0] ""  E115DCU
 SG_ HZP_Destination_X : 7|20@0- (0.01,0) [0|0] ""  E115DCU
 SG_ HZP_Destination_HdAng : 47|17@0- (0.003,0) [0|0] ""  E115DCU

BO_ 1861 APA_AvlSlot_Pos5: 8 E115DCU
 SG_ APA_AvlSlot10_Y : 44|10@0- (0.02,0) [-10.24|10.22] "m" Vector__XXX
 SG_ APA_AvlSlot10_X : 39|11@0- (0.015,0) [-15.36|15.345] "m" Vector__XXX
 SG_ APA_AvlSlot10_Tht : 50|11@0- (0.2,0) [-204.8|204.6] "deg" Vector__XXX
 SG_ APA_AvlSlot09_Y : 12|10@0- (0.02,0) [-10.24|10.22] "m" Vector__XXX
 SG_ APA_AvlSlot09_X : 7|11@0- (0.015,0) [-15.36|15.345] "m" Vector__XXX
 SG_ APA_AvlSlot09_Tht : 18|11@0- (0.2,0) [-204.8|204.6] "deg" Vector__XXX

BO_ 1860 APA_AvlSlot_Pos4: 8 E115DCU
 SG_ APA_AvlSlot08_Y : 44|10@0- (0.02,0) [-10.24|10.22] "m" Vector__XXX
 SG_ APA_AvlSlot08_X : 39|11@0- (0.015,0) [-15.36|15.345] "m" Vector__XXX
 SG_ APA_AvlSlot08_Tht : 50|11@0- (0.2,0) [-204.8|204.6] "deg" Vector__XXX
 SG_ APA_AvlSlot07_Y : 12|10@0- (0.02,0) [-10.24|10.22] "m" Vector__XXX
 SG_ APA_AvlSlot07_X : 7|11@0- (0.015,0) [-15.36|15.345] "m" Vector__XXX
 SG_ APA_AvlSlot07_Tht : 18|11@0- (0.2,0) [-204.8|204.6] "deg" Vector__XXX

BO_ 1859 APA_AvlSlot_Pos3: 8 E115DCU
 SG_ APA_AvlSlot06_Y : 44|10@0- (0.02,0) [-10.24|10.22] "m" Vector__XXX
 SG_ APA_AvlSlot06_X : 39|11@0- (0.015,0) [-15.36|15.345] "m" Vector__XXX
 SG_ APA_AvlSlot06_Tht : 50|11@0- (0.2,0) [-204.8|204.6] "deg" Vector__XXX
 SG_ APA_AvlSlot05_Y : 12|10@0- (0.02,0) [-10.24|10.22] "m" Vector__XXX
 SG_ APA_AvlSlot05_X : 7|11@0- (0.015,0) [-15.36|15.345] "m" Vector__XXX
 SG_ APA_AvlSlot05_Tht : 18|11@0- (0.2,0) [-204.8|204.6] "deg" Vector__XXX

BO_ 1858 APA_AvlSlot_Pos2: 8 E115DCU
 SG_ APA_AvlSlot04_Y : 44|10@0- (0.02,0) [-10.24|10.22] "m" Vector__XXX
 SG_ APA_AvlSlot04_X : 39|11@0- (0.015,0) [-15.36|15.345] "m" Vector__XXX
 SG_ APA_AvlSlot04_Tht : 50|11@0- (0.2,0) [-204.8|204.6] "deg" Vector__XXX
 SG_ APA_AvlSlot03_Y : 12|10@0- (0.02,0) [-10.24|10.22] "m" Vector__XXX
 SG_ APA_AvlSlot03_X : 7|11@0- (0.015,0) [-15.36|15.345] "m" Vector__XXX
 SG_ APA_AvlSlot03_Tht : 18|11@0- (0.2,0) [-204.8|204.6] "deg" Vector__XXX

BO_ 1857 APA_AvlSlot_Pos1: 8 E115DCU
 SG_ APA_AvlSlot02_Y : 44|10@0- (0.02,0) [-10.24|10.22] "m" Vector__XXX
 SG_ APA_AvlSlot02_X : 39|11@0- (0.015,0) [-15.36|15.345] "m" Vector__XXX
 SG_ APA_AvlSlot02_Tht : 50|11@0- (0.2,0) [-204.8|204.6] "deg" Vector__XXX
 SG_ APA_AvlSlot01_Y : 12|10@0- (0.02,0) [-10.24|10.22] "m" Vector__XXX
 SG_ APA_AvlSlot01_X : 7|11@0- (0.015,0) [-15.36|15.345] "m" Vector__XXX
 SG_ APA_AvlSlot01_Tht : 18|11@0- (0.2,0) [-204.8|204.6] "deg" Vector__XXX

BO_ 1801 APA_Status_2: 8 E115DCU
 SG_ APA_Status2_Rllcnt : 59|4@0+ (1,0) [0|0] "" Vector__XXX
 SG_ APA_NxtKeyPtY : 11|12@0- (0.01,0) [-20.48|20.47] "" Vector__XXX
 SG_ APA_NxtKeyPtX : 7|12@0- (0.01,0) [-20.48|20.47] "" Vector__XXX
 SG_ APA_NxtKeyPtTht : 31|12@0- (0.1,0) [-204.8|204.7] "" Vector__XXX

BO_ 1838 HZP_VisSlot_EdgInfo: 8 HzpSlot
 SG_ APA_Slot10_Edge4FLg : 32|1@0+ (1,0) [0|0] ""  E115DCU
 SG_ APA_Slot10_Edge3FLg : 33|1@0+ (1,0) [0|0] ""  E115DCU
 SG_ APA_Slot10_Edge2FLg : 34|1@0+ (1,0) [0|0] ""  E115DCU
 SG_ APA_Slot09_Edge4FLg : 36|1@0+ (1,0) [0|0] ""  E115DCU
 SG_ APA_Slot09_Edge2FLg : 38|1@0+ (1,0) [0|0] ""  E115DCU
 SG_ APA_Slot09_Edge1FLg : 39|1@0+ (1,0) [0|0] ""  E115DCU
 SG_ APA_Slot08_Edge4FLg : 24|1@0+ (1,0) [0|0] ""  E115DCU
 SG_ APA_Slot08_Edge3FLg : 25|1@0+ (1,0) [0|0] ""  E115DCU
 SG_ APA_Slot08_Edge2FLg : 26|1@0+ (1,0) [0|0] ""  E115DCU
 SG_ APA_Slot07_Edge4FLg : 28|1@0+ (1,0) [0|0] ""  E115DCU
 SG_ APA_Slot07_Edge3FLg : 29|1@0+ (1,0) [0|0] ""  E115DCU
 SG_ APA_Slot07_Edge2FLg : 30|1@0+ (1,0) [0|0] ""  E115DCU
 SG_ APA_Slot06_Edge4FLg : 16|1@0+ (1,0) [0|0] ""  E115DCU
 SG_ APA_Slot06_Edge3FLg : 17|1@0+ (1,0) [0|0] ""  E115DCU
 SG_ APA_Slot06_Edge2FLg : 18|1@0+ (1,0) [0|0] ""  E115DCU
 SG_ APA_Slot05_Edge4FLg : 20|1@0+ (1,0) [0|0] ""  E115DCU
 SG_ APA_Slot05_Edge3FLg : 21|1@0+ (1,0) [0|0] ""  E115DCU
 SG_ APA_Slot05_Edge2FLg : 22|1@0+ (1,0) [0|0] ""  E115DCU
 SG_ APA_Slot04_Edge4FLg : 8|1@0+ (1,0) [0|0] ""  E115DCU
 SG_ APA_Slot04_Edge3FLg : 9|1@0+ (1,0) [0|0] ""  E115DCU
 SG_ APA_Slot04_Edge2FLg : 10|1@0+ (1,0) [0|0] ""  E115DCU
 SG_ APA_Slot03_Edge4FLg : 12|1@0+ (1,0) [0|0] ""  E115DCU
 SG_ APA_Slot03_Edge3FLg : 13|1@0+ (1,0) [0|0] ""  E115DCU
 SG_ APA_Slot03_Edge2FLg : 14|1@0+ (1,0) [0|0] ""  E115DCU
 SG_ APA_Slot02_Edge4FLg : 0|1@0+ (1,0) [0|0] ""  E115DCU
 SG_ APA_Slot02_Edge3FLg : 1|1@0+ (1,0) [0|0] ""  E115DCU
 SG_ APA_Slot02_Edge2FLg : 2|1@0+ (1,0) [0|0] ""  E115DCU
 SG_ APA_Slot01_Edge4FLg : 4|1@0+ (1,0) [0|0] ""  E115DCU
 SG_ APA_Slot01_Edge3FLg : 5|1@0+ (1,0) [0|0] ""  E115DCU
 SG_ APA_Slot01_Edge2FLg : 6|1@0+ (1,0) [0|0] ""  E115DCU
 SG_ APA_Slot09_Edge3FLg : 37|1@0+ (1,0) [0|0] ""  E115DCU
 SG_ APA_Slot08_Edge1FLg : 27|1@0+ (1,0) [0|0] ""  E115DCU
 SG_ APA_Slot07_Edge1FLg : 31|1@0+ (1,0) [0|0] ""  E115DCU
 SG_ APA_Slot06_Edge1FLg : 19|1@0+ (1,0) [0|0] ""  E115DCU
 SG_ APA_Slot05_Edge1FLg : 23|1@0+ (1,0) [0|0] ""  E115DCU
 SG_ APA_Slot04_Edge1FLg : 11|1@0+ (1,0) [0|0] ""  E115DCU
 SG_ APA_Slot03_Edge1FLg : 15|1@0+ (1,0) [0|0] ""  E115DCU
 SG_ APA_Slot02_Edge1FLg : 3|1@0+ (1,0) [0|0] ""  E115DCU
 SG_ APA_Slot01_Edge1FLg : 7|1@0+ (1,0) [0|0] ""  E115DCU
 SG_ APA_Slot10_Edge1FLg : 35|1@0+ (1,0) [0|0] ""  E115DCU

BO_ 1800 APA_SW: 8 HMI
 SG_ APA_HandleSLotY : 43|12@0- (0.01,0) [-20.48|20.47] ""  E115DCU
 SG_ APA_HandleSLotX : 39|12@0- (0.01,0) [-20.48|20.47] ""  E115DCU
 SG_ APA_HandleSLotSW : 5|2@0+ (1,0) [0|0] ""  E115DCU
 SG_ APA_SlotSlctY : 19|12@0- (0.01,0) [0|0] "m"  E115DCU
 SG_ APA_SW : 0|1@0+ (1,0) [0|0] ""  E115DCU
 SG_ APA_SlotSlctX : 15|12@0- (0.01,0) [0|0] "m"  E115DCU
 SG_ APA_Slot_Dir : 2|1@0+ (1,0) [0|0] ""  E115DCU
 SG_ APA_Mode : 7|2@0+ (1,0) [0|0] ""  E115DCU

BO_ 1797 APA_AvlSlot_1: 8 E115DCU
 SG_ APA_AvlSlot_Rllcnt : 59|4@0+ (1,0) [0|0] "" Vector__XXX
 SG_ APA_TarSlotY : 23|12@0- (0.01,0) [-20.48|20.47] "" Vector__XXX
 SG_ APA_TarSlotX : 3|12@0- (0.01,0) [-20.48|20.47] "" Vector__XXX
 SG_ APA_TarSlotTht : 27|12@0- (0.1,0) [-204.8|204.7] "" Vector__XXX
 SG_ APA_AvlSlotNum : 7|4@0+ (1,0) [0|0] "" Vector__XXX

BO_ 1799 APA_Status_1: 8 E115DCU
 SG_ APA_Status1_Rllcnt : 59|4@0+ (1,0) [0|0] "" Vector__XXX
 SG_ APA_Spc_Sts : 30|3@0+ (1,0) [0|0] "" Vector__XXX
 SG_ APA_State : 23|4@0+ (1,0) [0|0] "" Vector__XXX
 SG_ APA_StpNum : 7|4@0+ (1,0) [0|0] "" Vector__XXX
 SG_ APA_StpNow : 3|4@0+ (1,0) [0|0] "" Vector__XXX
 SG_ APA_Ctrl_State : 19|4@0+ (1,0) [0|0] "" Vector__XXX
 SG_ APA_Bar : 15|7@0+ (0.01,0) [0|0] "" Vector__XXX

BO_ 1368 HZP_PathFollow_Info: 8 HzpStatus
 SG_ HZP_PrePntRear_Num : 47|6@0+ (1,0) [0|63] ""  E115DCU
 SG_ HZP_PrePntFar_Num : 39|8@0+ (1,0) [0|0] ""  E115DCU
 SG_ HZP_PthEndTyp : 17|1@0+ (1,0) [0|0] ""  E115DCU
 SG_ HZP_PrePntNum : 16|5@0+ (1,0) [0|0] ""  E115DCU
 SG_ HZP_DistToEnd : 41|18@0+ (0.01,0) [0|0] "m"  E115DCU
 SG_ HZP_AvlPth1Idx : 7|4@0+ (1,0) [0|0] ""  E115DCU

BO_ 1367 HZP_Localization_Info: 8 HzpStatus
 SG_ HZP_Location_Type : 42|2@0+ (1,0) [0|3] ""  E115DCU
 SG_ HZP_Localization_SegIdx : 19|4@0+ (1,0) [0|0] ""  E115DCU
 SG_ HZP_Localization_HdAng : 40|17@0- (0.003,0) [0|0] ""  E115DCU
 SG_ HZP_Localization_Y : 31|20@0- (0.01,0) [0|0] ""  E115DCU
 SG_ HZP_Localization_X : 7|20@0- (0.01,0) [0|0] ""  E115DCU

BO_ 1855 HZP_PathPoint15: 8 PathPoint
 SG_ PthPt15_Slope : 25|2@0+ (1,0) [0|0] ""  E115DCU
 SG_ PathPointStrAng : 54|11@0- (0.5,0) [-500|500] ""  E115DCU
 SG_ PthPtRollCnt : 59|4@0+ (1,0) [0|15] ""  E115DCU
 SG_ PathPointY : 23|14@0- (0.01,0) [0|0] ""  E115DCU
 SG_ PathPointX : 7|14@0- (0.01,0) [0|0] ""  E115DCU
 SG_ PathPointAng : 39|17@0- (0.003,0) [0|0] ""  E115DCU

BO_ 1854 HZP_PathPoint14: 8 PathPoint
 SG_ PthPt14_Slope : 25|2@0+ (1,0) [0|0] ""  E115DCU
 SG_ PathPointStrAng : 54|11@0- (0.5,0) [-500|500] ""  E115DCU
 SG_ PthPtRollCnt : 59|4@0+ (1,0) [0|15] ""  E115DCU
 SG_ PathPointY : 23|14@0- (0.01,0) [0|0] ""  E115DCU
 SG_ PathPointX : 7|14@0- (0.01,0) [0|0] ""  E115DCU
 SG_ PathPointAng : 39|17@0- (0.003,0) [0|0] ""  E115DCU

BO_ 1853 HZP_PathPoint13: 8 PathPoint
 SG_ PthPt13_Slope : 25|2@0+ (1,0) [0|0] ""  E115DCU
 SG_ PathPointStrAng : 54|11@0- (0.5,0) [-500|500] ""  E115DCU
 SG_ PthPtRollCnt : 59|4@0+ (1,0) [0|15] ""  E115DCU
 SG_ PathPointY : 23|14@0- (0.01,0) [0|0] ""  E115DCU
 SG_ PathPointX : 7|14@0- (0.01,0) [0|0] ""  E115DCU
 SG_ PathPointAng : 39|17@0- (0.003,0) [0|0] ""  E115DCU

BO_ 1844 HZP_PathPoint4: 8 PathPoint
 SG_ PthPt4_Slope : 25|2@0+ (1,0) [0|0] ""  E115DCU
 SG_ PathPointStrAng : 54|11@0- (0.5,0) [-500|500] ""  E115DCU
 SG_ PthPtRollCnt : 59|4@0+ (1,0) [0|15] ""  E115DCU
 SG_ PathPointY : 23|14@0- (0.01,0) [0|0] ""  E115DCU
 SG_ PathPointX : 7|14@0- (0.01,0) [0|0] ""  E115DCU
 SG_ PathPointAng : 39|17@0- (0.003,0) [0|0] ""  E115DCU

BO_ 1843 HZP_PathPoint3: 8 PathPoint
 SG_ PthPt3_Slope : 25|2@0+ (1,0) [0|0] ""  E115DCU
 SG_ PathPointStrAng : 54|11@0- (0.5,0) [-500|500] ""  E115DCU
 SG_ PthPtRollCnt : 59|4@0+ (1,0) [0|15] ""  E115DCU
 SG_ PathPointY : 23|14@0- (0.01,0) [0|0] ""  E115DCU
 SG_ PathPointX : 7|14@0- (0.01,0) [0|0] ""  E115DCU
 SG_ PathPointAng : 39|17@0- (0.003,0) [0|0] ""  E115DCU

BO_ 1852 HZP_PathPoint12: 8 PathPoint
 SG_ PthPt12_Slope : 25|2@0+ (1,0) [0|0] ""  E115DCU
 SG_ PathPointStrAng : 54|11@0- (0.5,0) [-500|500] ""  E115DCU
 SG_ PthPtRollCnt : 59|4@0+ (1,0) [0|15] ""  E115DCU
 SG_ PathPointY : 23|14@0- (0.01,0) [0|0] ""  E115DCU
 SG_ PathPointX : 7|14@0- (0.01,0) [0|0] ""  E115DCU
 SG_ PathPointAng : 39|17@0- (0.003,0) [0|0] ""  E115DCU

BO_ 1851 HZP_PathPoint11: 8 PathPoint
 SG_ PthPt11_Slope : 25|2@0+ (1,0) [0|0] ""  E115DCU
 SG_ PathPointStrAng : 54|11@0- (0.5,0) [-500|500] ""  E115DCU
 SG_ PthPtRollCnt : 59|4@0+ (1,0) [0|15] ""  E115DCU
 SG_ PathPointY : 23|14@0- (0.01,0) [0|0] ""  E115DCU
 SG_ PathPointX : 7|14@0- (0.01,0) [0|0] ""  E115DCU
 SG_ PathPointAng : 39|17@0- (0.003,0) [0|0] ""  E115DCU

BO_ 1850 HZP_PathPoint10: 8 PathPoint
 SG_ PthPt10_Slope : 25|2@0+ (1,0) [0|0] ""  E115DCU
 SG_ PathPointStrAng : 54|11@0- (0.5,0) [-500|500] ""  E115DCU
 SG_ PthPtRollCnt : 59|4@0+ (1,0) [0|15] ""  E115DCU
 SG_ PathPointY : 23|14@0- (0.01,0) [0|0] ""  E115DCU
 SG_ PathPointX : 7|14@0- (0.01,0) [0|0] ""  E115DCU
 SG_ PathPointAng : 39|17@0- (0.003,0) [0|0] ""  E115DCU

BO_ 1849 HZP_PathPoint9: 8 PathPoint
 SG_ PthPt9_Slope : 25|2@0+ (1,0) [0|0] ""  E115DCU
 SG_ PathPointStrAng : 54|11@0- (0.5,0) [-500|500] ""  E115DCU
 SG_ PthPtRollCnt : 59|4@0+ (1,0) [0|15] ""  E115DCU
 SG_ PathPointY : 23|14@0- (0.01,0) [0|0] ""  E115DCU
 SG_ PathPointX : 7|14@0- (0.01,0) [0|0] ""  E115DCU
 SG_ PathPointAng : 39|17@0- (0.003,0) [0|0] ""  E115DCU

BO_ 1848 HZP_PathPoint8: 8 PathPoint
 SG_ PthPt8_Slope : 25|2@0+ (1,0) [0|0] ""  E115DCU
 SG_ PathPointStrAng : 54|11@0- (0.5,0) [-500|500] ""  E115DCU
 SG_ PthPtRollCnt : 59|4@0+ (1,0) [0|15] ""  E115DCU
 SG_ PathPointY : 23|14@0- (0.01,0) [0|0] ""  E115DCU
 SG_ PathPointX : 7|14@0- (0.01,0) [0|0] ""  E115DCU
 SG_ PathPointAng : 39|17@0- (0.003,0) [0|0] ""  E115DCU

BO_ 1847 HZP_PathPoint7: 8 PathPoint
 SG_ PthPt7_Slope : 25|2@0+ (1,0) [0|0] ""  E115DCU
 SG_ PathPointStrAng : 54|11@0- (0.5,0) [-500|500] ""  E115DCU
 SG_ PthPtRollCnt : 59|4@0+ (1,0) [0|15] ""  E115DCU
 SG_ PathPointY : 23|14@0- (0.01,0) [0|0] ""  E115DCU
 SG_ PathPointX : 7|14@0- (0.01,0) [0|0] ""  E115DCU
 SG_ PathPointAng : 39|17@0- (0.003,0) [0|0] ""  E115DCU

BO_ 1846 HZP_PathPoint6: 8 PathPoint
 SG_ PthPt6_Slope : 25|2@0+ (1,0) [0|0] ""  E115DCU
 SG_ PathPointStrAng : 54|11@0- (0.5,0) [-500|500] ""  E115DCU
 SG_ PthPtRollCnt : 59|4@0+ (1,0) [0|15] ""  E115DCU
 SG_ PathPointY : 23|14@0- (0.01,0) [0|0] ""  E115DCU
 SG_ PathPointX : 7|14@0- (0.01,0) [0|0] ""  E115DCU
 SG_ PathPointAng : 39|17@0- (0.003,0) [0|0] ""  E115DCU

BO_ 1845 HZP_PathPoint5: 8 PathPoint
 SG_ PthPt5_Slope : 25|2@0+ (1,0) [0|0] ""  E115DCU
 SG_ PathPointStrAng : 54|11@0- (0.5,0) [-500|500] ""  E115DCU
 SG_ PthPtRollCnt : 59|4@0+ (1,0) [0|15] ""  E115DCU
 SG_ PathPointY : 23|14@0- (0.01,0) [0|0] ""  E115DCU
 SG_ PathPointX : 7|14@0- (0.01,0) [0|0] ""  E115DCU
 SG_ PathPointAng : 39|17@0- (0.003,0) [0|0] ""  E115DCU

BO_ 1842 HZP_PathPoint2: 8 PathPoint
 SG_ PthPt2_Slope : 25|2@0+ (1,0) [0|0] ""  E115DCU
 SG_ PathPointStrAng : 54|11@0- (0.5,0) [-500|500] ""  E115DCU
 SG_ PthPtRollCnt : 59|4@0+ (1,0) [0|15] ""  E115DCU
 SG_ PathPointY : 23|14@0- (0.01,0) [0|0] ""  E115DCU
 SG_ PathPointX : 7|14@0- (0.01,0) [0|0] ""  E115DCU
 SG_ PathPointAng : 39|17@0- (0.003,0) [0|0] ""  E115DCU

BO_ 1841 HZP_PathPoint1: 8 PathPoint
 SG_ PthPt1_Slope : 25|2@0+ (1,0) [0|0] ""  E115DCU
 SG_ PathPointStrAng : 54|11@0- (0.5,0) [-500|500] ""  E115DCU
 SG_ PthPtRollCnt : 59|4@0+ (1,0) [0|15] ""  E115DCU
 SG_ PathPointY : 23|14@0- (0.01,0) [0|0] ""  E115DCU
 SG_ PathPointX : 7|14@0- (0.01,0) [0|0] ""  E115DCU
 SG_ PathPointAng : 39|17@0- (0.003,0) [0|0] ""  E115DCU

BO_ 1366 HZP_VSLAM_Info: 8 HzpStatus
 SG_ HZP_InMapSavNum : 35|4@0+ (1,0) [0|0] ""  E115DCU
 SG_ HZP_OutMapSavNum : 39|4@0+ (1,0) [0|0] ""  E115DCU
 SG_ HZP_VSLAM_PathLen : 15|18@0+ (0.01,0) [0|0] ""  E115DCU
 SG_ HZP_VSLAM_PathIdx : 3|4@0+ (1,0) [0|0] ""  E115DCU
 SG_ HZP_VSLAM_Sts : 7|4@0+ (1,0) [0|0] ""  E115DCU

BO_ 1839 HZP_VisSlot_Info: 8 HzpSlot
 SG_ HZP_Slot_Vis_PtRllcnt : 55|4@0+ (1,0) [0|0] ""  E115DCU
 SG_ SlotVis_fault : 35|1@0+ (1,0) [0|0] ""  E115DCU
 SG_ Slot_VisNum : 39|4@0+ (1,0) [0|0] ""  E115DCU
 SG_ SlotVis_IPMNum : 7|32@0+ (1,0) [0|0] ""  E115DCU

BO_ 1365 HZP_VISRollCnt: 8 HzpStatus
 SG_ HZP_VSLAM_RollCnt : 63|4@0+ (1,0) [0|0] ""  E115DCU
 SG_ HZP_VSLAM_MappingAlive : 45|2@0+ (1,0) [0|0] ""  E115DCU
 SG_ HZP_VSLAM_LocationAlive : 53|2@0+ (1,0) [0|0] ""  E115DCU
 SG_ HZP_VSLAM_CameraAlive : 49|2@0+ (1,0) [0|0] ""  E115DCU
 SG_ HZP_VSLAM_BusAlive : 41|2@0+ (1,0) [0|0] ""  E115DCU
 SG_ HZP_SlotSemSeg_RollCnt : 35|4@0+ (1,0) [0|0] ""  E115DCU
 SG_ HZP_LctSemSeg_RollCnt : 39|4@0+ (1,0) [0|0] ""  E115DCU
 SG_ IPM_Idx : 7|32@0+ (1,0) [0|0] ""  E115DCU

BO_ 1830 HZP_VisSlot10_2: 8 HzpSlot
 SG_ SlotPt4_VisFlg : 48|1@0+ (1,0) [0|0] ""  E115DCU
 SG_ SlotPt3_VisFlg : 49|1@0+ (1,0) [0|0] ""  E115DCU
 SG_ HZP_Slot_Vis_PtRllcnt : 55|4@0+ (1,0) [0|0] ""  E115DCU
 SG_ HZP_Slot_Vis_P4y : 35|12@0- (0.01,0) [0|0] ""  E115DCU
 SG_ HZP_Slot_Vis_P4x : 31|12@0- (0.01,0) [0|0] ""  E115DCU
 SG_ HZP_Slot_Vis_P3y : 11|12@0- (0.01,0) [0|0] ""  E115DCU
 SG_ HZP_Slot_Vis_P3x : 7|12@0- (0.01,0) [0|0] ""  E115DCU

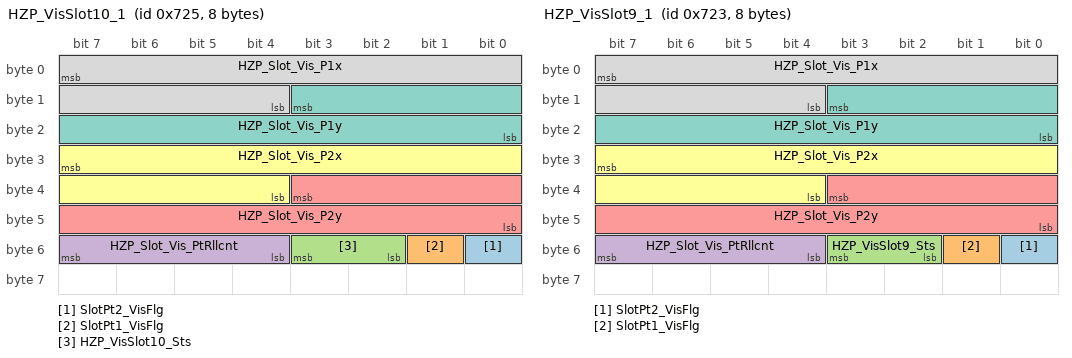
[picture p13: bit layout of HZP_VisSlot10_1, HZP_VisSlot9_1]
BO_ 1829 HZP_VisSlot10_1: 8 HzpSlot
 SG_ SlotPt2_VisFlg : 48|1@0+ (1,0) [0|0] ""  E115DCU
 SG_ SlotPt1_VisFlg : 49|1@0+ (1,0) [0|0] ""  E115DCU
 SG_ HZP_VisSlot10_Sts : 51|2@0+ (1,0) [0|0] ""  E115DCU
 SG_ HZP_Slot_Vis_PtRllcnt : 55|4@0+ (1,0) [0|0] ""  E115DCU
 SG_ HZP_Slot_Vis_P2y : 35|12@0- (0.01,0) [0|0] ""  E115DCU
 SG_ HZP_Slot_Vis_P2x : 31|12@0- (0.01,0) [0|0] ""  E115DCU
 SG_ HZP_Slot_Vis_P1y : 11|12@0- (0.01,0) [0|0] ""  E115DCU
 SG_ HZP_Slot_Vis_P1x : 7|12@0- (0.01,0) [0|0] ""  E115DCU

BO_ 1828 HZP_VisSlot9_2: 8 HzpSlot
 SG_ SlotPt4_VisFlg : 48|1@0+ (1,0) [0|0] ""  E115DCU
 SG_ SlotPt3_VisFlg : 49|1@0+ (1,0) [0|0] ""  E115DCU
 SG_ HZP_Slot_Vis_PtRllcnt : 55|4@0+ (1,0) [0|0] ""  E115DCU
 SG_ HZP_Slot_Vis_P4y : 35|12@0- (0.01,0) [0|0] ""  E115DCU
 SG_ HZP_Slot_Vis_P4x : 31|12@0- (0.01,0) [0|0] ""  E115DCU
 SG_ HZP_Slot_Vis_P3y : 11|12@0- (0.01,0) [0|0] ""  E115DCU
 SG_ HZP_Slot_Vis_P3x : 7|12@0- (0.01,0) [0|0] ""  E115DCU

BO_ 1827 HZP_VisSlot9_1: 8 HzpSlot
 SG_ SlotPt2_VisFlg : 48|1@0+ (1,0) [0|0] ""  E115DCU
 SG_ SlotPt1_VisFlg : 49|1@0+ (1,0) [0|0] ""  E115DCU
 SG_ HZP_VisSlot9_Sts : 51|2@0+ (1,0) [0|0] ""  E115DCU
 SG_ HZP_Slot_Vis_PtRllcnt : 55|4@0+ (1,0) [0|0] ""  E115DCU
 SG_ HZP_Slot_Vis_P2y : 35|12@0- (0.01,0) [0|0] ""  E115DCU
 SG_ HZP_Slot_Vis_P2x : 31|12@0- (0.01,0) [0|0] ""  E115DCU
 SG_ HZP_Slot_Vis_P1y : 11|12@0- (0.01,0) [0|0] ""  E115DCU
 SG_ HZP_Slot_Vis_P1x : 7|12@0- (0.01,0) [0|0] ""  E115DCU

BO_ 1826 HZP_VisSlot8_2: 8 HzpSlot
 SG_ SlotPt4_VisFlg : 48|1@0+ (1,0) [0|0] ""  E115DCU
 SG_ SlotPt3_VisFlg : 49|1@0+ (1,0) [0|0] ""  E115DCU
 SG_ HZP_Slot_Vis_PtRllcnt : 55|4@0+ (1,0) [0|0] ""  E115DCU
 SG_ HZP_Slot_Vis_P4y : 35|12@0- (0.01,0) [0|0] ""  E115DCU
 SG_ HZP_Slot_Vis_P4x : 31|12@0- (0.01,0) [0|0] ""  E115DCU
 SG_ HZP_Slot_Vis_P3y : 11|12@0- (0.01,0) [0|0] ""  E115DCU
 SG_ HZP_Slot_Vis_P3x : 7|12@0- (0.01,0) [0|0] ""  E115DCU

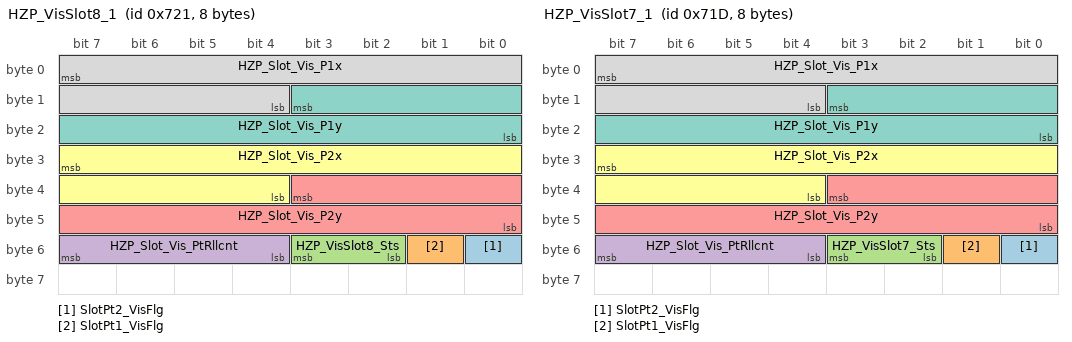
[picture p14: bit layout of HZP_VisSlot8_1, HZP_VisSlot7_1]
BO_ 1825 HZP_VisSlot8_1: 8 HzpSlot
 SG_ SlotPt2_VisFlg : 48|1@0+ (1,0) [0|0] ""  E115DCU
 SG_ SlotPt1_VisFlg : 49|1@0+ (1,0) [0|0] ""  E115DCU
 SG_ HZP_VisSlot8_Sts : 51|2@0+ (1,0) [0|0] ""  E115DCU
 SG_ HZP_Slot_Vis_PtRllcnt : 55|4@0+ (1,0) [0|0] ""  E115DCU
 SG_ HZP_Slot_Vis_P2y : 35|12@0- (0.01,0) [0|0] ""  E115DCU
 SG_ HZP_Slot_Vis_P2x : 31|12@0- (0.01,0) [0|0] ""  E115DCU
 SG_ HZP_Slot_Vis_P1y : 11|12@0- (0.01,0) [0|0] ""  E115DCU
 SG_ HZP_Slot_Vis_P1x : 7|12@0- (0.01,0) [0|0] ""  E115DCU

BO_ 1822 HZP_VisSlot7_2: 8 HzpSlot
 SG_ SlotPt4_VisFlg : 48|1@0+ (1,0) [0|0] ""  E115DCU
 SG_ SlotPt3_VisFlg : 49|1@0+ (1,0) [0|0] ""  E115DCU
 SG_ HZP_Slot_Vis_PtRllcnt : 55|4@0+ (1,0) [0|0] ""  E115DCU
 SG_ HZP_Slot_Vis_P4y : 35|12@0- (0.01,0) [0|0] ""  E115DCU
 SG_ HZP_Slot_Vis_P4x : 31|12@0- (0.01,0) [0|0] ""  E115DCU
 SG_ HZP_Slot_Vis_P3y : 11|12@0- (0.01,0) [0|0] ""  E115DCU
 SG_ HZP_Slot_Vis_P3x : 7|12@0- (0.01,0) [0|0] ""  E115DCU

BO_ 1821 HZP_VisSlot7_1: 8 HzpSlot
 SG_ SlotPt2_VisFlg : 48|1@0+ (1,0) [0|0] ""  E115DCU
 SG_ SlotPt1_VisFlg : 49|1@0+ (1,0) [0|0] ""  E115DCU
 SG_ HZP_VisSlot7_Sts : 51|2@0+ (1,0) [0|0] ""  E115DCU
 SG_ HZP_Slot_Vis_PtRllcnt : 55|4@0+ (1,0) [0|0] ""  E115DCU
 SG_ HZP_Slot_Vis_P2y : 35|12@0- (0.01,0) [0|0] ""  E115DCU
 SG_ HZP_Slot_Vis_P2x : 31|12@0- (0.01,0) [0|0] ""  E115DCU
 SG_ HZP_Slot_Vis_P1y : 11|12@0- (0.01,0) [0|0] ""  E115DCU
 SG_ HZP_Slot_Vis_P1x : 7|12@0- (0.01,0) [0|0] ""  E115DCU

BO_ 1820 HZP_VisSlot6_2: 8 HzpSlot
 SG_ SlotPt4_VisFlg : 48|1@0+ (1,0) [0|0] ""  E115DCU
 SG_ SlotPt3_VisFlg : 49|1@0+ (1,0) [0|0] ""  E115DCU
 SG_ HZP_Slot_Vis_PtRllcnt : 55|4@0+ (1,0) [0|0] ""  E115DCU
 SG_ HZP_Slot_Vis_P4y : 35|12@0- (0.01,0) [0|0] ""  E115DCU
 SG_ HZP_Slot_Vis_P4x : 31|12@0- (0.01,0) [0|0] ""  E115DCU
 SG_ HZP_Slot_Vis_P3y : 11|12@0- (0.01,0) [0|0] ""  E115DCU
 SG_ HZP_Slot_Vis_P3x : 7|12@0- (0.01,0) [0|0] ""  E115DCU

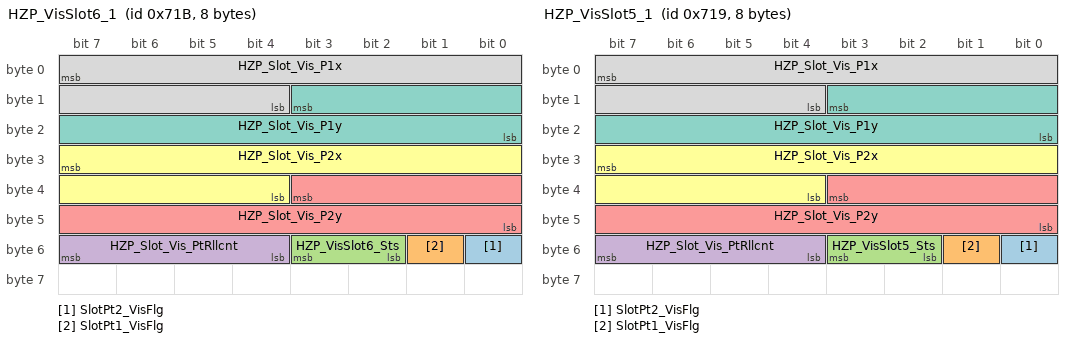
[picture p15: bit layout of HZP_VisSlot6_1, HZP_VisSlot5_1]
BO_ 1819 HZP_VisSlot6_1: 8 HzpSlot
 SG_ SlotPt2_VisFlg : 48|1@0+ (1,0) [0|0] ""  E115DCU
 SG_ SlotPt1_VisFlg : 49|1@0+ (1,0) [0|0] ""  E115DCU
 SG_ HZP_VisSlot6_Sts : 51|2@0+ (1,0) [0|0] ""  E115DCU
 SG_ HZP_Slot_Vis_PtRllcnt : 55|4@0+ (1,0) [0|0] ""  E115DCU
 SG_ HZP_Slot_Vis_P2y : 35|12@0- (0.01,0) [0|0] ""  E115DCU
 SG_ HZP_Slot_Vis_P2x : 31|12@0- (0.01,0) [0|0] ""  E115DCU
 SG_ HZP_Slot_Vis_P1y : 11|12@0- (0.01,0) [0|0] ""  E115DCU
 SG_ HZP_Slot_Vis_P1x : 7|12@0- (0.01,0) [0|0] ""  E115DCU

BO_ 1818 HZP_VisSlot5_2: 8 HzpSlot
 SG_ SlotPt4_VisFlg : 48|1@0+ (1,0) [0|0] ""  E115DCU
 SG_ SlotPt3_VisFlg : 49|1@0+ (1,0) [0|0] ""  E115DCU
 SG_ HZP_Slot_Vis_PtRllcnt : 55|4@0+ (1,0) [0|0] ""  E115DCU
 SG_ HZP_Slot_Vis_P4y : 35|12@0- (0.01,0) [0|0] ""  E115DCU
 SG_ HZP_Slot_Vis_P4x : 31|12@0- (0.01,0) [0|0] ""  E115DCU
 SG_ HZP_Slot_Vis_P3y : 11|12@0- (0.01,0) [0|0] ""  E115DCU
 SG_ HZP_Slot_Vis_P3x : 7|12@0- (0.01,0) [0|0] ""  E115DCU

BO_ 1817 HZP_VisSlot5_1: 8 HzpSlot
 SG_ SlotPt2_VisFlg : 48|1@0+ (1,0) [0|0] ""  E115DCU
 SG_ SlotPt1_VisFlg : 49|1@0+ (1,0) [0|0] ""  E115DCU
 SG_ HZP_VisSlot5_Sts : 51|2@0+ (1,0) [0|0] ""  E115DCU
 SG_ HZP_Slot_Vis_PtRllcnt : 55|4@0+ (1,0) [0|0] ""  E115DCU
 SG_ HZP_Slot_Vis_P2y : 35|12@0- (0.01,0) [0|0] ""  E115DCU
 SG_ HZP_Slot_Vis_P2x : 31|12@0- (0.01,0) [0|0] ""  E115DCU
 SG_ HZP_Slot_Vis_P1y : 11|12@0- (0.01,0) [0|0] ""  E115DCU
 SG_ HZP_Slot_Vis_P1x : 7|12@0- (0.01,0) [0|0] ""  E115DCU

BO_ 1816 HZP_VisSlot4_2: 8 HzpSlot
 SG_ SlotPt4_VisFlg : 48|1@0+ (1,0) [0|0] ""  E115DCU
 SG_ SlotPt3_VisFlg : 49|1@0+ (1,0) [0|0] ""  E115DCU
 SG_ HZP_Slot_Vis_PtRllcnt : 55|4@0+ (1,0) [0|0] ""  E115DCU
 SG_ HZP_Slot_Vis_P4y : 35|12@0- (0.01,0) [0|0] ""  E115DCU
 SG_ HZP_Slot_Vis_P4x : 31|12@0- (0.01,0) [0|0] ""  E115DCU
 SG_ HZP_Slot_Vis_P3y : 11|12@0- (0.01,0) [0|0] ""  E115DCU
 SG_ HZP_Slot_Vis_P3x : 7|12@0- (0.01,0) [0|0] ""  E115DCU

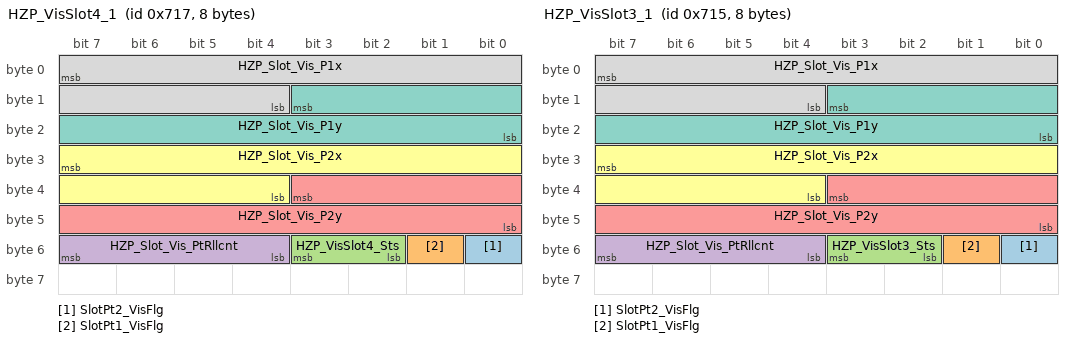
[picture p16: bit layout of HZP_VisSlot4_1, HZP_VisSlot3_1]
BO_ 1815 HZP_VisSlot4_1: 8 HzpSlot
 SG_ SlotPt2_VisFlg : 48|1@0+ (1,0) [0|0] ""  E115DCU
 SG_ SlotPt1_VisFlg : 49|1@0+ (1,0) [0|0] ""  E115DCU
 SG_ HZP_VisSlot4_Sts : 51|2@0+ (1,0) [0|0] ""  E115DCU
 SG_ HZP_Slot_Vis_PtRllcnt : 55|4@0+ (1,0) [0|0] ""  E115DCU
 SG_ HZP_Slot_Vis_P2y : 35|12@0- (0.01,0) [0|0] ""  E115DCU
 SG_ HZP_Slot_Vis_P2x : 31|12@0- (0.01,0) [0|0] ""  E115DCU
 SG_ HZP_Slot_Vis_P1y : 11|12@0- (0.01,0) [0|0] ""  E115DCU
 SG_ HZP_Slot_Vis_P1x : 7|12@0- (0.01,0) [0|0] ""  E115DCU

BO_ 1814 HZP_VisSlot3_2: 8 HzpSlot
 SG_ SlotPt4_VisFlg : 48|1@0+ (1,0) [0|0] ""  E115DCU
 SG_ SlotPt3_VisFlg : 49|1@0+ (1,0) [0|0] ""  E115DCU
 SG_ HZP_Slot_Vis_PtRllcnt : 55|4@0+ (1,0) [0|0] ""  E115DCU
 SG_ HZP_Slot_Vis_P4y : 35|12@0- (0.01,0) [0|0] ""  E115DCU
 SG_ HZP_Slot_Vis_P4x : 31|12@0- (0.01,0) [0|0] ""  E115DCU
 SG_ HZP_Slot_Vis_P3y : 11|12@0- (0.01,0) [0|0] ""  E115DCU
 SG_ HZP_Slot_Vis_P3x : 7|12@0- (0.01,0) [0|0] ""  E115DCU

BO_ 1813 HZP_VisSlot3_1: 8 HzpSlot
 SG_ SlotPt2_VisFlg : 48|1@0+ (1,0) [0|0] ""  E115DCU
 SG_ SlotPt1_VisFlg : 49|1@0+ (1,0) [0|0] ""  E115DCU
 SG_ HZP_VisSlot3_Sts : 51|2@0+ (1,0) [0|0] ""  E115DCU
 SG_ HZP_Slot_Vis_PtRllcnt : 55|4@0+ (1,0) [0|0] ""  E115DCU
 SG_ HZP_Slot_Vis_P2y : 35|12@0- (0.01,0) [0|0] ""  E115DCU
 SG_ HZP_Slot_Vis_P2x : 31|12@0- (0.01,0) [0|0] ""  E115DCU
 SG_ HZP_Slot_Vis_P1y : 11|12@0- (0.01,0) [0|0] ""  E115DCU
 SG_ HZP_Slot_Vis_P1x : 7|12@0- (0.01,0) [0|0] ""  E115DCU

BO_ 1812 HZP_VisSlot2_2: 8 HzpSlot
 SG_ SlotPt4_VisFlg : 48|1@0+ (1,0) [0|0] ""  E115DCU
 SG_ SlotPt3_VisFlg : 49|1@0+ (1,0) [0|0] ""  E115DCU
 SG_ HZP_Slot_Vis_PtRllcnt : 55|4@0+ (1,0) [0|0] ""  E115DCU
 SG_ HZP_Slot_Vis_P4y : 35|12@0- (0.01,0) [0|0] ""  E115DCU
 SG_ HZP_Slot_Vis_P4x : 31|12@0- (0.01,0) [0|0] ""  E115DCU
 SG_ HZP_Slot_Vis_P3y : 11|12@0- (0.01,0) [0|0] ""  E115DCU
 SG_ HZP_Slot_Vis_P3x : 7|12@0- (0.01,0) [0|0] ""  E115DCU

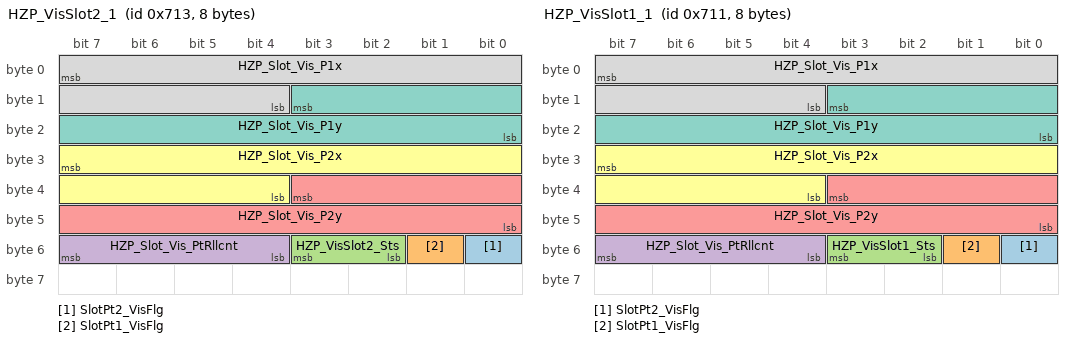
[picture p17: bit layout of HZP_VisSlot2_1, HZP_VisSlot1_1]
BO_ 1811 HZP_VisSlot2_1: 8 HzpSlot
 SG_ SlotPt2_VisFlg : 48|1@0+ (1,0) [0|0] ""  E115DCU
 SG_ SlotPt1_VisFlg : 49|1@0+ (1,0) [0|0] ""  E115DCU
 SG_ HZP_VisSlot2_Sts : 51|2@0+ (1,0) [0|0] ""  E115DCU
 SG_ HZP_Slot_Vis_PtRllcnt : 55|4@0+ (1,0) [0|0] ""  E115DCU
 SG_ HZP_Slot_Vis_P2y : 35|12@0- (0.01,0) [0|0] ""  E115DCU
 SG_ HZP_Slot_Vis_P2x : 31|12@0- (0.01,0) [0|0] ""  E115DCU
 SG_ HZP_Slot_Vis_P1y : 11|12@0- (0.01,0) [0|0] ""  E115DCU
 SG_ HZP_Slot_Vis_P1x : 7|12@0- (0.01,0) [0|0] ""  E115DCU

BO_ 1810 HZP_VisSlot1_2: 8 HzpSlot
 SG_ SlotPt4_VisFlg : 48|1@0+ (1,0) [0|0] ""  E115DCU
 SG_ SlotPt3_VisFlg : 49|1@0+ (1,0) [0|0] ""  E115DCU
 SG_ HZP_Slot_Vis_PtRllcnt : 55|4@0+ (1,0) [0|0] ""  E115DCU
 SG_ HZP_Slot_Vis_P4y : 35|12@0- (0.01,0) [0|0] ""  E115DCU
 SG_ HZP_Slot_Vis_P4x : 31|12@0- (0.01,0) [0|0] ""  E115DCU
 SG_ HZP_Slot_Vis_P3y : 11|12@0- (0.01,0) [0|0] ""  E115DCU
 SG_ HZP_Slot_Vis_P3x : 7|12@0- (0.01,0) [0|0] ""  E115DCU

BO_ 1809 HZP_VisSlot1_1: 8 HzpSlot
 SG_ SlotPt2_VisFlg : 48|1@0+ (1,0) [0|0] ""  E115DCU
 SG_ SlotPt1_VisFlg : 49|1@0+ (1,0) [0|0] ""  E115DCU
 SG_ HZP_VisSlot1_Sts : 51|2@0+ (1,0) [0|0] ""  E115DCU
 SG_ HZP_Slot_Vis_PtRllcnt : 55|4@0+ (1,0) [0|0] ""  E115DCU
 SG_ HZP_Slot_Vis_P2y : 35|12@0- (0.01,0) [0|0] ""  E115DCU
 SG_ HZP_Slot_Vis_P2x : 31|12@0- (0.01,0) [0|0] ""  E115DCU
 SG_ HZP_Slot_Vis_P1y : 11|12@0- (0.01,0) [0|0] ""  E115DCU
 SG_ HZP_Slot_Vis_P1x : 7|12@0- (0.01,0) [0|0] ""  E115DCU

BO_ 1796 HZP_Status_3: 8 E115DCU
 SG_ Slope_Estimate : 55|16@0- (0.001,0) [-32.768|32.767] "deg" Vector__XXX
 SG_ HZP_Path_a2 : 39|16@0- (5E-006,0) [-0.16384|0.163835] "" Vector__XXX
 SG_ HZP_Path_a1 : 23|16@0- (1E-005,0) [0|0] "" Vector__XXX
 SG_ HZP_Path_a0 : 7|16@0- (0.001,0) [0|0] "" Vector__XXX

BO_ 1795 HZP_SW: 8 HMI
 SG_ HZP_Location_Req : 34|1@0+ (1,0) [0|0] ""  E115DCU
 SG_ HZP_SS_SW : 36|1@0+ (1,0) [0|0] ""  E115DCU
 SG_ HZP_PrkOutType : 15|2@0+ (1,0) [0|0] ""  E115DCU
 SG_ HZP_FP_Start : 13|1@0+ (1,0) [0|1] ""  E115DCU
 SG_ HZP_InZoneConf : 11|1@0+ (1,0) [0|0] ""  E115DCU
 SG_ HZP_PthTrainning_End : 9|1@0+ (1,0) [0|0] ""  E115DCU
 SG_ HZP_IniPnt_UserY : 51|12@0+ (1,0) [0|0] ""  E115DCU
 SG_ HZP_IniPnt_UserX : 47|12@0+ (1,0) [0|0] ""  E115DCU
 SG_ HZP_PathDltSlct : 27|4@0+ (1,0) [0|0] ""  E115DCU
 SG_ HZP_PathDltButton : 39|2@0+ (1,0) [0|0] ""  E115DCU
 SG_ HZP_PathDir : 17|2@0+ (1,0) [0|0] ""  E115DCU
 SG_ HZP_Cncl : 19|1@0+ (1,0) [0|0] ""  E115DCU
 SG_ HZP_FuncSlct : 23|3@0+ (1,0) [0|0] ""  E115DCU
 SG_ HZP_Path_Slct : 31|4@0+ (1,0) [0|0] ""  E115DCU
 SG_ HZP_Resume : 1|1@0+ (1,0) [0|0] ""  E115DCU
 SG_ HZP_PrkMode : 3|1@0+ (1,0) [0|0] ""  E115DCU
 SG_ HZP_ActSW : 5|1@0+ (1,0) [0|0] ""  E115DCU
 SG_ HZP_Enb : 7|1@0+ (1,0) [0|0] ""  E115DCU

BO_ 1794 HZP_Status_2: 8 Vector__XXX
 SG_ APA_STS : 63|4@0+ (1,0) [0|0] "" Vector__XXX
 SG_ APA_Search_STS : 59|4@0+ (1,0) [0|15] "" Vector__XXX
 SG_ HZP_PosY : 35|20@0- (0.01,0) [0|0] "m" Vector__XXX
 SG_ HZP_PosX : 11|20@0- (0.01,0) [0|0] "m" Vector__XXX
 SG_ HZP_CurPoint_ID : 7|12@0+ (1,0) [0|0] "" Vector__XXX

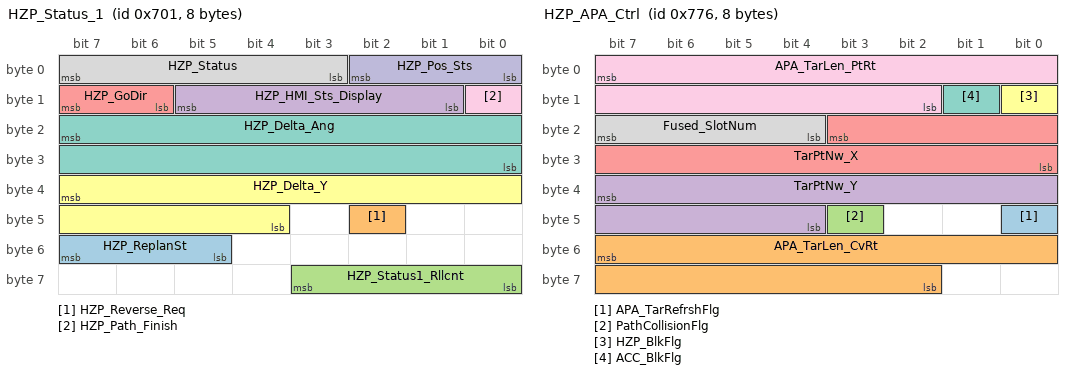
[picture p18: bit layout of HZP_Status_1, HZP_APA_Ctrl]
BO_ 1793 HZP_Status_1: 8 E115DCU
 SG_ HZP_ReplanSt : 55|3@0+ (1,0) [0|7] "" Vector__XXX
 SG_ HZP_Reverse_Req : 42|1@0+ (1,0) [0|1] "" Vector__XXX
 SG_ HZP_Status1_Rllcnt : 59|4@0+ (1,0) [0|0] "" Vector__XXX
 SG_ HZP_HMI_Sts_Display : 13|5@0+ (1,0) [0|0] "" Vector__XXX
 SG_ HZP_GoDir : 15|2@0- (1,0) [0|0] "" Vector__XXX
 SG_ HZP_Delta_Y : 39|12@0- (0.01,0) [0|0] "m" Vector__XXX
 SG_ HZP_Delta_Ang : 23|16@0- (0.01,0) [0|0] "" Vector__XXX
 SG_ HZP_Status : 7|5@0+ (1,0) [0|0] "" Vector__XXX
 SG_ HZP_Path_Finish : 8|1@0+ (1,0) [0|0] "" Vector__XXX
 SG_ HZP_Pos_Sts : 2|3@0+ (1,0) [0|0] "" Vector__XXX

BO_ 828 GW_IBCM3: 8 Vector__XXX
 SG_ BCM_DoorLockSt : 2|1@0+ (1,0) [0|1] "" Vector__XXX
 SG_ BCM_FrontWiperSwitchSt : 15|2@0+ (1,0) [0|3] "" Vector__XXX
 SG_ BCM_IgnitionSt : 1|2@0+ (1,0) [0|3] "" Vector__XXX

BO_ 2007 ObjWhl_Info: 8 WheelObj
 SG_ Obj_Whl24_Src : 49|2@0+ (1,0) [0|3] ""  E115DCU
 SG_ Obj_Whl23_Src : 51|2@0+ (1,0) [0|3] ""  E115DCU
 SG_ Obj_Whl22_Src : 53|2@0+ (1,0) [0|3] ""  E115DCU
 SG_ Obj_Whl21_Src : 55|2@0+ (1,0) [0|3] ""  E115DCU
 SG_ Obj_Whl20_Src : 41|2@0+ (1,0) [0|3] ""  E115DCU
 SG_ Obj_Whl19_Src : 43|2@0+ (1,0) [0|3] ""  E115DCU
 SG_ Obj_Whl18_Src : 45|2@0+ (1,0) [0|3] ""  E115DCU
 SG_ Obj_Whl17_Src : 47|2@0+ (1,0) [0|3] ""  E115DCU
 SG_ Obj_Whl16_Src : 33|2@0+ (1,0) [0|3] ""  E115DCU
 SG_ Obj_Whl15_Src : 35|2@0+ (1,0) [0|3] ""  E115DCU
 SG_ Obj_Whl14_Src : 37|2@0+ (1,0) [0|3] ""  E115DCU
 SG_ Obj_Whl13_Src : 39|2@0+ (1,0) [0|3] ""  E115DCU
 SG_ Obj_Whl12_Src : 25|2@0+ (1,0) [0|3] ""  E115DCU
 SG_ Obj_Whl11_Src : 27|2@0+ (1,0) [0|3] ""  E115DCU
 SG_ Obj_Whl10_Src : 29|2@0+ (1,0) [0|3] ""  E115DCU
 SG_ Obj_Whl9_Src : 31|2@0+ (1,0) [0|3] ""  E115DCU
 SG_ Obj_Whl8_Src : 17|2@0+ (1,0) [0|3] ""  E115DCU
 SG_ Obj_Whl7_Src : 19|2@0+ (1,0) [0|3] ""  E115DCU
 SG_ Obj_Whl6_Src : 21|2@0+ (1,0) [0|3] ""  E115DCU
 SG_ Obj_Whl5_Src : 23|2@0+ (1,0) [0|3] ""  E115DCU
 SG_ Obj_Whl4_Src : 9|2@0+ (1,0) [0|3] ""  E115DCU
 SG_ Obj_Whl3_Src : 11|2@0+ (1,0) [0|3] ""  E115DCU
 SG_ Obj_Whl2_Src : 13|2@0+ (1,0) [0|3] ""  E115DCU
 SG_ Obj_Whl1_Src : 15|2@0+ (1,0) [0|3] ""  E115DCU
 SG_ ObjWhlRollCnt : 59|4@0+ (1,0) [0|15] ""  E115DCU
 SG_ Obj_Whl_Num : 7|6@0+ (1,0) [0|63] ""  E115DCU

BO_ 2008 Obj_Whl_Pos1: 8 WheelObj
 SG_ ObjWhlRollCnt : 59|4@0+ (1,0) [0|15] ""  E115DCU
 SG_ Obj_Whl3_PosY : 53|10@0- (0.04,0) [-20.48|20.44] ""  E115DCU
 SG_ Obj_Whl3_PosX : 47|10@0- (0.04,0) [-20.48|20.44] ""  E115DCU
 SG_ Obj_Whl2_PosY : 25|10@0- (0.04,0) [-20.48|20.44] ""  E115DCU
 SG_ Obj_Whl2_PosX : 19|10@0- (0.04,0) [-20.48|20.44] ""  E115DCU
 SG_ Obj_Whl1_PosY : 13|10@0- (0.04,0) [-20.48|20.44] ""  E115DCU
 SG_ Obj_Whl1_PosX : 7|10@0- (0.04,0) [-20.48|20.44] ""  E115DCU

BO_ 2009 Obj_Whl_Pos2: 8 WheelObj
 SG_ ObjWhlRollCnt : 59|4@0+ (1,0) [0|15] ""  E115DCU
 SG_ Obj_Whl6_PosY : 53|10@0- (0.04,0) [-20.48|20.44] ""  E115DCU
 SG_ Obj_Whl6_PosX : 47|10@0- (0.04,0) [-20.48|20.44] ""  E115DCU
 SG_ Obj_Whl5_PosY : 25|10@0- (0.04,0) [-20.48|20.44] ""  E115DCU
 SG_ Obj_Whl5_PosX : 19|10@0- (0.04,0) [-20.48|20.44] ""  E115DCU
 SG_ Obj_Whl4_PosY : 13|10@0- (0.04,0) [-20.48|20.44] ""  E115DCU
 SG_ Obj_Whl4_PosX : 7|10@0- (0.04,0) [-20.48|20.44] ""  E115DCU

BO_ 2010 Obj_Whl_Pos3: 8 WheelObj
 SG_ ObjWhlRollCnt : 59|4@0+ (1,0) [0|15] ""  E115DCU
 SG_ Obj_Whl9_PosY : 53|10@0- (0.04,0) [-20.48|20.44] ""  E115DCU
 SG_ Obj_Whl9_PosX : 47|10@0- (0.04,0) [-20.48|20.44] ""  E115DCU
 SG_ Obj_Whl8_PosY : 25|10@0- (0.04,0) [-20.48|20.44] ""  E115DCU
 SG_ Obj_Whl8_PosX : 19|10@0- (0.04,0) [-20.48|20.44] ""  E115DCU
 SG_ Obj_Whl7_PosY : 13|10@0- (0.04,0) [-20.48|20.44] ""  E115DCU
 SG_ Obj_Whl7_PosX : 7|10@0- (0.04,0) [-20.48|20.44] ""  E115DCU

BO_ 2011 Obj_Whl_Pos4: 8 WheelObj
 SG_ ObjWhlRollCnt : 59|4@0+ (1,0) [0|15] ""  E115DCU
 SG_ Obj_Whl12_PosY : 53|10@0- (0.04,0) [-20.48|20.44] ""  E115DCU
 SG_ Obj_Whl12_PosX : 47|10@0- (0.04,0) [-20.48|20.44] ""  E115DCU
 SG_ Obj_Whl11_PosY : 25|10@0- (0.04,0) [-20.48|20.44] ""  E115DCU
 SG_ Obj_Whl11_PosX : 19|10@0- (0.04,0) [-20.48|20.44] ""  E115DCU
 SG_ Obj_Whl10_PosY : 13|10@0- (0.04,0) [-20.48|20.44] ""  E115DCU
 SG_ Obj_Whl10_PosX : 7|10@0- (0.04,0) [-20.48|20.44] ""  E115DCU

BO_ 2012 Obj_Whl_Pos5: 8 WheelObj
 SG_ ObjWhlRollCnt : 59|4@0+ (1,0) [0|15] ""  E115DCU
 SG_ Obj_Whl15_PosY : 53|10@0- (0.04,0) [-20.48|20.44] ""  E115DCU
 SG_ Obj_Whl15_PosX : 47|10@0- (0.04,0) [-20.48|20.44] ""  E115DCU
 SG_ Obj_Whl14_PosY : 25|10@0- (0.04,0) [-20.48|20.44] ""  E115DCU
 SG_ Obj_Whl14_PosX : 19|10@0- (0.04,0) [-20.48|20.44] ""  E115DCU
 SG_ Obj_Whl13_PosY : 13|10@0- (0.04,0) [-20.48|20.44] ""  E115DCU
 SG_ Obj_Whl13_PosX : 7|10@0- (0.04,0) [-20.48|20.44] ""  E115DCU

BO_ 2013 Obj_Whl_Pos6: 8 WheelObj
 SG_ ObjWhlRollCnt : 59|4@0+ (1,0) [0|15] ""  E115DCU
 SG_ Obj_Whl18_PosY : 53|10@0- (0.04,0) [-20.48|20.44] ""  E115DCU
 SG_ Obj_Whl18_PosX : 47|10@0- (0.04,0) [-20.48|20.44] ""  E115DCU
 SG_ Obj_Whl17_PosY : 25|10@0- (0.04,0) [-20.48|20.44] ""  E115DCU
 SG_ Obj_Whl17_PosX : 19|10@0- (0.04,0) [-20.48|20.44] ""  E115DCU
 SG_ Obj_Whl16_PosY : 13|10@0- (0.04,0) [-20.48|20.44] ""  E115DCU
 SG_ Obj_Whl16_PosX : 7|10@0- (0.04,0) [-20.48|20.44] ""  E115DCU

BO_ 2014 Obj_Whl_Pos7: 8 WheelObj
 SG_ ObjWhlRollCnt : 59|4@0+ (1,0) [0|15] ""  E115DCU
 SG_ Obj_Whl21_PosY : 53|10@0- (0.04,0) [-20.48|20.44] ""  E115DCU
 SG_ Obj_Whl21_PosX : 47|10@0- (0.04,0) [-20.48|20.44] ""  E115DCU
 SG_ Obj_Whl20_PosY : 25|10@0- (0.04,0) [-20.48|20.44] ""  E115DCU
 SG_ Obj_Whl20_PosX : 19|10@0- (0.04,0) [-20.48|20.44] ""  E115DCU
 SG_ Obj_Whl19_PosY : 13|10@0- (0.04,0) [-20.48|20.44] ""  E115DCU
 SG_ Obj_Whl19_PosX : 7|10@0- (0.04,0) [-20.48|20.44] ""  E115DCU

BO_ 2015 Obj_Whl_Pos8: 8 WheelObj
 SG_ ObjWhlRollCnt : 59|4@0+ (1,0) [0|15] ""  E115DCU
 SG_ Obj_Whl24_PosY : 53|10@0- (0.04,0) [-20.48|20.44] ""  E115DCU
 SG_ Obj_Whl24_PosX : 47|10@0- (0.04,0) [-20.48|20.44] ""  E115DCU
 SG_ Obj_Whl23_PosY : 25|10@0- (0.04,0) [-20.48|20.44] ""  E115DCU
 SG_ Obj_Whl23_PosX : 19|10@0- (0.04,0) [-20.48|20.44] ""  E115DCU
 SG_ Obj_Whl22_PosY : 13|10@0- (0.04,0) [-20.48|20.44] ""  E115DCU
 SG_ Obj_Whl22_PosX : 7|10@0- (0.04,0) [-20.48|20.44] ""  E115DCU

BO_ 1060 LatitudeLongitude: 8 E115DCU
 SG_ PosLon : 39|32@0- (1E-007,0) [-214.7483648|214.7483648] "deg" Vector__XXX
 SG_ PosLat : 7|32@0- (1E-007,0) [-214.7483648|214.7483648] "deg" Vector__XXX

BO_ 1059 InsStatus: 8 E115DCU
 SG_ AngRateRawZ : 47|20@0- (1,0) [0|0] "" Vector__XXX
 SG_ GpsNumSats2Used : 31|8@0+ (1,0) [0|255] "" Vector__XXX
 SG_ system_state : 7|8@0+ (1,0) [0|9] "" Vector__XXX
 SG_ satellite_status : 23|8@0+ (1,0) [0|9] "" Vector__XXX
 SG_ GpsNumSatsUsed : 15|8@0+ (1,0) [0|255] "" Vector__XXX

BO_ 1066 HeadingPitchRoll: 8 E115DCU
 SG_ AngleRoll : 39|16@0- (0.01,0) [-180|180] "deg" Vector__XXX
 SG_ AnglePitch : 23|16@0- (0.01,0) [-90|90] "deg" Vector__XXX
 SG_ AngleHeading : 7|16@0+ (0.01,0) [0|360] "deg" Vector__XXX

BO_ 769 Parking_UltraSonic: 8 E115DCU
 SG_ UltraSonic_FRS : 55|16@0+ (1,0) [0|600] "cm" Vector__XXX
 SG_ UltraSonic_FLS : 39|16@0+ (1,0) [0|600] "cm" Vector__XXX
 SG_ UltraSonic_RLS : 23|16@0+ (1,0) [0|600] "cm" Vector__XXX
 SG_ UltraSonic_RRS : 7|16@0+ (1,0) [0|600] "cm" Vector__XXX

BO_ 1911 RollIingCount: 8 E115DCU
 SG_ HZP_RllCnt : 3|4@0+ (1,0) [0|0] "" Vector__XXX
 SG_ APA_RllCnt : 7|4@0+ (1,0) [0|0] "" Vector__XXX

BO_ 1910 HZP_APA_Ctrl: 8 E115DCU
 SG_ APA_TarRefrshFlg : 40|1@0+ (1,0) [0|0] "" Vector__XXX
 SG_ APA_TarLen_CvRt : 55|14@0+ (0.01,0) [0|0] "m" Vector__XXX
 SG_ PathCollisionFlg : 43|1@0+ (1,0) [0|0] "" Vector__XXX
 SG_ TarPtNw_Y : 39|12@0- (0.01,0) [-20.48|20.47] "" Vector__XXX
 SG_ TarPtNw_X : 19|12@0- (0.01,0) [-20.48|20.47] "" Vector__XXX
 SG_ HZP_BlkFlg : 8|1@0+ (1,0) [0|0] "" Vector__XXX
 SG_ ACC_BlkFlg : 9|1@0+ (1,0) [0|1] "" Vector__XXX
 SG_ Fused_SlotNum : 23|4@0+ (1,0) [0|0] "" Vector__XXX
 SG_ APA_TarLen_PtRt : 7|14@0+ (0.01,0) [0|0] "" Vector__XXX

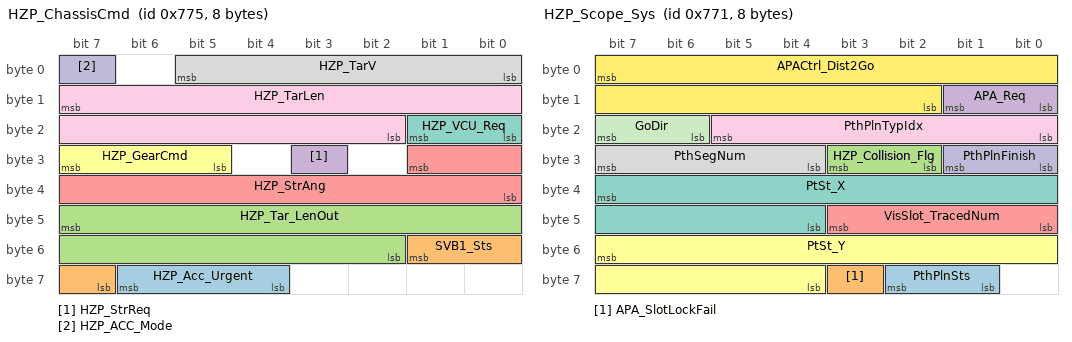
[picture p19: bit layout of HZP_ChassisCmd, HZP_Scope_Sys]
BO_ 1909 HZP_ChassisCmd: 8 E115DCU
 SG_ HZP_Acc_Urgent : 62|3@0+ (1,0) [0|3] "" Vector__XXX
 SG_ SVB1_Sts : 49|3@0+ (1,0) [0|0] "" Vector__XXX
 SG_ HZP_Tar_LenOut : 47|14@0- (0.01,0) [0|0] "m" Vector__XXX
 SG_ HZP_StrReq : 27|1@0+ (1,0) [0|0] "" Vector__XXX
 SG_ HZP_StrAng : 25|10@0- (1,0) [-512|511] "deg" Vector__XXX
 SG_ HZP_GearCmd : 31|3@0+ (1,0) [0|0] "" Vector__XXX
 SG_ HZP_VCU_Req : 17|2@0+ (1,0) [0|0] "" Vector__XXX
 SG_ HZP_TarV : 5|6@0+ (0.5,0) [0|0] "kph" Vector__XXX
 SG_ HZP_TarLen : 15|14@0+ (0.01,0) [0|0] "m" Vector__XXX
 SG_ HZP_ACC_Mode : 7|1@0+ (1,0) [0|0] "" Vector__XXX

BO_ 1908 HZP_USRtEdge: 8 E115DCU
 SG_ US_RtEdgeFlg : 7|2@0+ (1,0) [0|3] "" Vector__XXX
 SG_ US_RtEdg_St : 17|10@0- (0.02,-5) [-15.24|5.22] "" Vector__XXX
 SG_ US_RtEdg_Ed : 39|10@0- (0.02,-5) [-15.24|5.22] "" Vector__XXX
 SG_ US_RtEdg_A1 : 11|10@0- (0.0005,0) [-0.256|0.2555] "" Vector__XXX
 SG_ US_RtEdg_A0 : 5|10@0+ (0.01,-9.23) [-9.23|1] "" Vector__XXX

BO_ 1907 HZP_USLtEdge: 8 E115DCU
 SG_ US_LtEdg_St : 17|10@0- (0.02,-5) [-15.24|5.22] "" Vector__XXX
 SG_ US_LtEdg_Ed : 39|10@0- (0.02,-5) [-15.24|5.22] "" Vector__XXX
 SG_ US_LtEdgeFlg : 7|2@0+ (1,0) [0|3] "" Vector__XXX
 SG_ US_LtEdg_A1 : 11|10@0- (0.0005,0) [-0.256|0.2555] "" Vector__XXX
 SG_ US_LtEdg_A0 : 5|10@0+ (0.01,-1) [-1|9.23] "" Vector__XXX

BO_ 1906 HZP_Scope_E115: 8 E115DCU
 SG_ APA_TarTht : 43|12@0- (0.1,0) [-204.8|204.7] "" Vector__XXX
 SG_ APA_StpTht2Trn : 15|12@0- (0.1,0) [-204.8|204.7] "deg" Vector__XXX
 SG_ HZP_FP_PreLen : 39|12@0+ (0.01,0) [0|40.95] "m" Vector__XXX
 SG_ Emerg_mode : 31|8@0+ (1,0) [0|255] "" Vector__XXX
 SG_ StrCtrl_Sts : 2|3@0+ (1,0) [0|7] "cm" Vector__XXX
 SG_ LongiCtrl_Sts : 6|3@0+ (1,0) [0|7] "cm" Vector__XXX

BO_ 1905 HZP_Scope_Sys: 8 E115DCU
 SG_ PthPlnSts : 58|2@0+ (1,0) [0|0] "" Vector__XXX
 SG_ APA_SlotLockFail : 59|1@0+ (1,0) [0|0] "" Vector__XXX
 SG_ HZP_Collision_Flg : 27|2@0+ (1,0) [0|0] "" Vector__XXX
 SG_ APA_Req : 9|2@0+ (1,0) [0|0] "" Vector__XXX
 SG_ VisSlot_TracedNum : 43|4@0+ (1,0) [0|0] "" Vector__XXX
 SG_ PtSt_Y : 55|12@0- (0.01,0) [-20.48|20.47] "" Vector__XXX
 SG_ PtSt_X : 39|12@0- (0.01,0) [-20.48|20.47] "" Vector__XXX
 SG_ PthSegNum : 31|4@0+ (1,0) [0|0] "" Vector__XXX
 SG_ PthPlnTypIdx : 21|6@0+ (1,0) [0|63] "" Vector__XXX
 SG_ PthPlnFinish : 25|2@0+ (1,0) [0|3] "" Vector__XXX
 SG_ GoDir : 23|2@0- (1,0) [-2|1] "" Vector__XXX
 SG_ APACtrl_Dist2Go : 7|14@0- (0.01,0) [-81.92|81.91] "" Vector__XXX

BO_ 2001 HZP_RplnPathPoint_1: 8 E115DCU
 SG_ HZP_RplnPtNm : 49|6@0+ (1,0) [0|63] "" Vector__XXX
 SG_ HZP_RplnPathPoint2Ang : 43|10@0- (0.36,0) [-180|180] "" Vector__XXX
 SG_ HZP_RplnPathPoint1Ang : 23|10@0- (0.36,0) [-180|180] "" Vector__XXX
 SG_ HZP_RplnPathPoint2Y : 36|9@0- (0.1,0) [-25.6|25.5] "" Vector__XXX
 SG_ HZP_RplnPathPoint2X : 29|9@0- (0.1,0) [-25.6|25.5] "" Vector__XXX
 SG_ PthPtRollCnt : 59|4@0+ (1,0) [0|15] "" Vector__XXX
 SG_ HZP_RplnPathPoint1Y : 15|8@0- (0.1,0) [-12.8|12.7] "" Vector__XXX
 SG_ HZP_RplnPathPoint1X : 7|8@0- (0.1,0) [-12.8|12.7] "" Vector__XXX

BO_ 2002 HZP_RplnPathPoint_2: 8 E115DCU
 SG_ HZP_RplnPathPoint4Ang : 53|10@0- (0.36,0) [-180|180] "" Vector__XXX
 SG_ HZP_RplnPathPoint3Ang : 19|10@0- (0.36,0) [-180|180] "" Vector__XXX
 SG_ HZP_RplnPathPoint4Y : 47|10@0- (0.04,0) [-20.48|20.44] "" Vector__XXX
 SG_ HZP_RplnPathPoint4X : 25|10@0- (0.04,0) [-20.48|20.44] "" Vector__XXX
 SG_ PthPtRollCnt : 59|4@0+ (1,0) [0|15] "" Vector__XXX
 SG_ HZP_RplnPathPoint3Y : 13|10@0- (0.04,0) [-20.48|20.44] "" Vector__XXX
 SG_ HZP_RplnPathPoint3X : 7|10@0- (0.04,0) [-20.48|20.44] "" Vector__XXX

BO_ 2003 HZP_RplnPathPoint_3: 8 E115DCU
 SG_ HZP_RplnPathPoint6Ang : 53|10@0- (0.36,0) [-180|180] "" Vector__XXX
 SG_ HZP_RplnPathPoint5Ang : 19|10@0- (0.36,0) [-180|180] "" Vector__XXX
 SG_ HZP_RplnPathPoint6Y : 47|10@0- (0.04,0) [-20.48|20.44] "" Vector__XXX
 SG_ HZP_RplnPathPoint6X : 25|10@0- (0.04,0) [-20.48|20.44] "" Vector__XXX
 SG_ PthPtRollCnt : 59|4@0+ (1,0) [0|15] "" Vector__XXX
 SG_ HZP_RplnPathPoint5Y : 13|10@0- (0.04,0) [-20.48|20.44] "" Vector__XXX
 SG_ HZP_RplnPathPoint5X : 7|10@0- (0.04,0) [-20.48|20.44] "" Vector__XXX

BO_ 2004 HZP_RplnPathPoint_4: 8 E115DCU
 SG_ HZP_RplnPathPoint8Ang : 53|10@0- (0.36,0) [-180|180] "" Vector__XXX
 SG_ HZP_RplnPathPoint7Ang : 19|10@0- (0.36,0) [-180|180] "" Vector__XXX
 SG_ HZP_RplnPathPoint8Y : 47|10@0- (0.04,0) [-20.48|20.44] "" Vector__XXX
 SG_ HZP_RplnPathPoint8X : 25|10@0- (0.04,0) [-20.48|20.44] "" Vector__XXX
 SG_ PthPtRollCnt : 59|4@0+ (1,0) [0|15] "" Vector__XXX
 SG_ HZP_RplnPathPoint7Y : 13|10@0- (0.04,0) [-20.48|20.44] "" Vector__XXX
 SG_ HZP_RplnPathPoint7X : 7|10@0- (0.04,0) [-20.48|20.44] "" Vector__XXX

BO_ 2005 HZP_RplnPathPoint_5: 8 E115DCU
 SG_ HZP_RplnPathPoint10Ang : 53|10@0- (0.36,0) [-180|180] "" Vector__XXX
 SG_ HZP_RplnPathPoint9Ang : 19|10@0- (0.36,0) [-180|180] "" Vector__XXX
 SG_ HZP_RplnPathPoint10Y : 47|10@0- (0.04,0) [-20.48|20.44] "" Vector__XXX
 SG_ HZP_RplnPathPoint10X : 25|10@0- (0.04,0) [-20.48|20.44] "" Vector__XXX
 SG_ PthPtRollCnt : 59|4@0+ (1,0) [0|15] "" Vector__XXX
 SG_ HZP_RplnPathPoint9Y : 13|10@0- (0.04,0) [-20.48|20.44] "" Vector__XXX
 SG_ HZP_RplnPathPoint9X : 7|10@0- (0.04,0) [-20.48|20.44] "" Vector__XXX

BO_ 1921 HZP_Obj_1: 8 E115DCU
 SG_ HZP_Obj1_ID : 7|8@0+ (1,0) [0|0] "" Vector__XXX
 SG_ HZP_Obj1_Wdth : 40|6@0+ (0.1,0) [0|6.3] "m" Vector__XXX
 SG_ HZP_Obj1_Heading : 50|8@0- (1.42,0) [-181.76|180.34] "deg" Vector__XXX
 SG_ HZP_Obj1_Vy : 33|9@0- (0.04,0) [-10.24|10.2] "m/s" Vector__XXX
 SG_ HZP_Obj1_Vx : 26|9@0- (0.04,0) [-10.24|10.2] "m/s" Vector__XXX
 SG_ HZP_Obj1_Ry : 19|9@0- (0.1,0) [-25.6|25.5] "m" Vector__XXX
 SG_ HZP_Obj1_Rx : 12|9@0- (0.1,0) [-25.6|25.5] "m" Vector__XXX
 SG_ HZP_Obj1_Class : 15|3@0+ (1,0) [0|0] "" Vector__XXX

BO_ 1922 HZP_Obj_2: 8 E115DCU
 SG_ HZP_Obj2_ID : 7|8@0+ (1,0) [0|0] "" Vector__XXX
 SG_ HZP_Obj2_Wdth : 40|6@0+ (0.1,0) [0|6.3] "m" Vector__XXX
 SG_ HZP_Obj2_Heading : 50|8@0- (1.42,0) [-181.76|180.34] "deg" Vector__XXX
 SG_ HZP_Obj2_Vy : 33|9@0- (0.04,0) [-10.24|10.2] "m/s" Vector__XXX
 SG_ HZP_Obj2_Vx : 26|9@0- (0.04,0) [-10.24|10.2] "m/s" Vector__XXX
 SG_ HZP_Obj2_Ry : 19|9@0- (0.1,0) [-25.6|25.5] "m" Vector__XXX
 SG_ HZP_Obj2_Rx : 12|9@0- (0.1,0) [-25.6|25.5] "m" Vector__XXX
 SG_ HZP_Obj2_Class : 15|3@0+ (1,0) [0|0] "" Vector__XXX

BO_ 1923 HZP_Obj_3: 8 E115DCU
 SG_ HZP_Obj3_ID : 7|8@0+ (1,0) [0|0] "" Vector__XXX
 SG_ HZP_Obj3_Wdth : 40|6@0+ (0.1,0) [0|6.3] "m" Vector__XXX
 SG_ HZP_Obj3_Heading : 50|8@0- (1.42,0) [-181.76|180.34] "deg" Vector__XXX
 SG_ HZP_Obj3_Vy : 33|9@0- (0.04,0) [-10.24|10.2] "m/s" Vector__XXX
 SG_ HZP_Obj3_Vx : 26|9@0- (0.04,0) [-10.24|10.2] "m/s" Vector__XXX
 SG_ HZP_Obj3_Ry : 19|9@0- (0.1,0) [-25.6|25.5] "m" Vector__XXX
 SG_ HZP_Obj3_Rx : 12|9@0- (0.1,0) [-25.6|25.5] "m" Vector__XXX
 SG_ HZP_Obj3_Class : 15|3@0+ (1,0) [0|0] "" Vector__XXX

BO_ 1935 HZP_NearestObj: 8 E115DCU
 SG_ HZP_NrstObj_Wdth : 42|6@0+ (0.1,0) [0|6.3] "m" Vector__XXX
 SG_ HZP_NrstObj_Typ : 15|4@0+ (1,0) [0|15] "" Vector__XXX
 SG_ HZP_NrstObj_Ry : 35|9@0- (0.1,0) [-25.6|25.5] "m" Vector__XXX
 SG_ HZP_NrstObj_Rx : 28|9@0- (0.1,0) [-25.6|25.5] "m" Vector__XXX
 SG_ HZP_NrstObj_IntrDist : 21|9@0- (0.02,0) [-5.12|5.1] "m" Vector__XXX
 SG_ HZP_NrstObj_Indx : 11|6@0+ (1,0) [0|63] "" Vector__XXX
 SG_ HZP_NrstObj_ID : 7|8@0+ (1,0) [0|255] "" Vector__XXX

BO_ 1937 HZP_Bhr_Scope: 8 E115DCU
 SG_ HZP_BhrCmd_Mod : 23|8@0+ (1,0) [0|0] "" Vector__XXX
 SG_ HZP_Bhr_RplnCalFlg : 5|1@0- (1,0) [0|0] "" Vector__XXX
 SG_ BhrCmd1IntrIdx : 15|8@0+ (1,0) [0|255] "" Vector__XXX
 SG_ BehaviorReplanFlg : 7|2@0+ (1,0) [0|3] "" Vector__XXX

BO_ 1936 HZP_Obj_Info: 8 E115DCU
 SG_ HZP_IntrvPtIndx_3 : 37|5@0+ (1,0) [0|0] "" Vector__XXX
 SG_ HZP_IntrvPtIndx_2 : 26|5@0+ (1,0) [0|0] "" Vector__XXX
 SG_ HZP_IntrvPtIndx_1 : 31|5@0+ (1,0) [0|0] "" Vector__XXX
 SG_ HZP_Bhr_PlnFlg : 3|1@0+ (1,0) [0|0] "" Vector__XXX
 SG_ HZP_BehaviorCnt : 15|16@0+ (1,0) [0|0] "" Vector__XXX
 SG_ HZP_Obj_Num : 7|4@0+ (1,0) [0|0] "" Vector__XXX

BO_ 1939 PaperBox_2: 8 E115DCU
 SG_ PaperBox4_y : 37|9@0- (0.05,0) [-12.8|12.75] "m" Vector__XXX
 SG_ PaperBox4_x : 30|9@0- (0.05,0) [-12.8|12.75] "m" Vector__XXX
 SG_ PaperBox4_wd : 44|7@0+ (0.05,0) [0|6.35] "m" Vector__XXX
 SG_ PaperBox3_y : 14|9@0- (0.05,0) [-12.8|12.75] "m" Vector__XXX
 SG_ PaperBox3_x : 7|9@0- (0.05,0) [-12.8|12.75] "m" Vector__XXX
 SG_ PaperBox3_wd : 21|7@0+ (0.05,0) [0|6.35] "m" Vector__XXX

BO_ 1938 PaperBox_1: 8 E115DCU
 SG_ PaperBox2_y : 37|9@0- (0.05,0) [-12.8|12.75] "m" Vector__XXX
 SG_ PaperBox2_x : 30|9@0- (0.05,0) [-12.8|12.75] "m" Vector__XXX
 SG_ PaperBox2_wd : 44|7@0+ (0.05,0) [0|6.35] "m" Vector__XXX
 SG_ PaperBox_Nm : 53|6@0+ (1,0) [0|0] "" Vector__XXX
 SG_ PaperBox1_y : 14|9@0- (0.05,0) [-12.8|12.75] "m" Vector__XXX
 SG_ PaperBox1_x : 7|9@0- (0.05,0) [-12.8|12.75] "m" Vector__XXX
 SG_ PaperBox1_wd : 21|7@0+ (0.05,0) [0|6.35] "m" Vector__XXX

CM_ "

";
CM_ BO_ 3221225472 "This is a message for not used signals, created by Vector CANdb++ DBC OLE DB Provider.";
BA_DEF_ BO_  "GenMsgCycleTime" INT 0 0;
BA_DEF_ BO_  "GenMsgSendType" ENUM  "Cycle","Event";
BA_DEF_  "NmAsrRepeatMessageTime" INT 0 0;
BA_DEF_  "NmAsrWaitBusSleepTime" INT 0 0;
BA_DEF_  "NmAsrTimeoutTime" INT 0 0;
BA_DEF_  "NmAsrCanMsgCycleTime" INT 0 0;
BA_DEF_  "NmAsrMessageCount" INT 0 256;
BA_DEF_ BU_  "GenNodSleepTime" INT 0 1000000;
BA_DEF_DEF_  "GenMsgCycleTime" 0;
BA_DEF_DEF_  "GenMsgSendType" "Cycle";
BA_DEF_DEF_  "NmAsrRepeatMessageTime" 3200;
BA_DEF_DEF_  "NmAsrWaitBusSleepTime" 1500;
BA_DEF_DEF_  "NmAsrTimeoutTime" 2000;
BA_DEF_DEF_  "NmAsrCanMsgCycleTime" 640;
BA_DEF_DEF_  "NmAsrMessageCount" 64;
BA_DEF_DEF_  "GenNodSleepTime" 4000;
BA_ "GenMsgCycleTime" BO_ 1802 25;
BA_ "GenMsgCycleTime" BO_ 1861 25;
BA_ "GenMsgCycleTime" BO_ 1860 25;
BA_ "GenMsgCycleTime" BO_ 1859 25;
BA_ "GenMsgCycleTime" BO_ 1858 25;
BA_ "GenMsgCycleTime" BO_ 1857 25;
BA_ "GenMsgCycleTime" BO_ 1801 25;
BA_ "GenMsgCycleTime" BO_ 1797 25;
BA_ "GenMsgCycleTime" BO_ 1799 25;
BA_ "GenMsgCycleTime" BO_ 1796 25;
BA_ "GenMsgCycleTime" BO_ 1793 25;
BA_ "GenMsgCycleTime" BO_ 1060 25;
BA_ "GenMsgCycleTime" BO_ 1059 25;
BA_ "GenMsgCycleTime" BO_ 1066 25;
BA_ "GenMsgCycleTime" BO_ 769 25;
BA_ "GenMsgCycleTime" BO_ 1911 25;
BA_ "GenMsgCycleTime" BO_ 1910 25;
BA_ "GenMsgCycleTime" BO_ 1909 10;
BA_ "GenMsgCycleTime" BO_ 1908 25;
BA_ "GenMsgCycleTime" BO_ 1907 25;
BA_ "GenMsgCycleTime" BO_ 1906 25;
BA_ "GenMsgCycleTime" BO_ 1905 25;
BA_ "GenMsgCycleTime" BO_ 2001 25;
BA_ "GenMsgCycleTime" BO_ 2002 25;
BA_ "GenMsgCycleTime" BO_ 2003 25;
BA_ "GenMsgCycleTime" BO_ 2004 25;
BA_ "GenMsgCycleTime" BO_ 2005 25;
BA_ "GenMsgCycleTime" BO_ 1921 25;
BA_ "GenMsgCycleTime" BO_ 1922 25;
BA_ "GenMsgCycleTime" BO_ 1923 25;
BA_ "GenMsgCycleTime" BO_ 1935 25;
BA_ "GenMsgCycleTime" BO_ 1937 25;
BA_ "GenMsgCycleTime" BO_ 1936 25;
BA_ "GenMsgCycleTime" BO_ 1939 25;
BA_ "GenMsgCycleTime" BO_ 1938 25;
VAL_ 1366 HZP_VSLAM_Sts 9 "MappingSucc" 8 "MapSaving" 7 "Relocation" 6 "Locating Fail" 5 "Initial Locating Fail" 4 "Mapping OverSize" 3 "MappingFail" 2 "Localization" 1 "Mapping" 0 "NotRun" ;
VAL_ 1794 APA_STS 7 "RTA,Wait to release brake" 6 "APA_Fail" 5 "APA_Finish" 4 "APA HangOn" 3 "APA processing" 2 "Standby" 1 "OFF" 0 "Reserved" ;
VAL_ 1794 APA_Search_STS 7 "Finish" 6 "3rd Curb OK" 5 "Fail " 4 "Fall detect" 3 "Rise and Fall OK" 2 "Rise Conf" 1 "Rish detect" 0 "Reserved" ;
VAL_ 828 BCM_IgnitionSt 3 "START" 2 "ON" 1 "ACC" 0 "OFF" ;
